[part 4 of 4: package /ComponentTypes]
AUTOSAR XML (schema 4-3-0)
package /ComponentTypes  (continued)
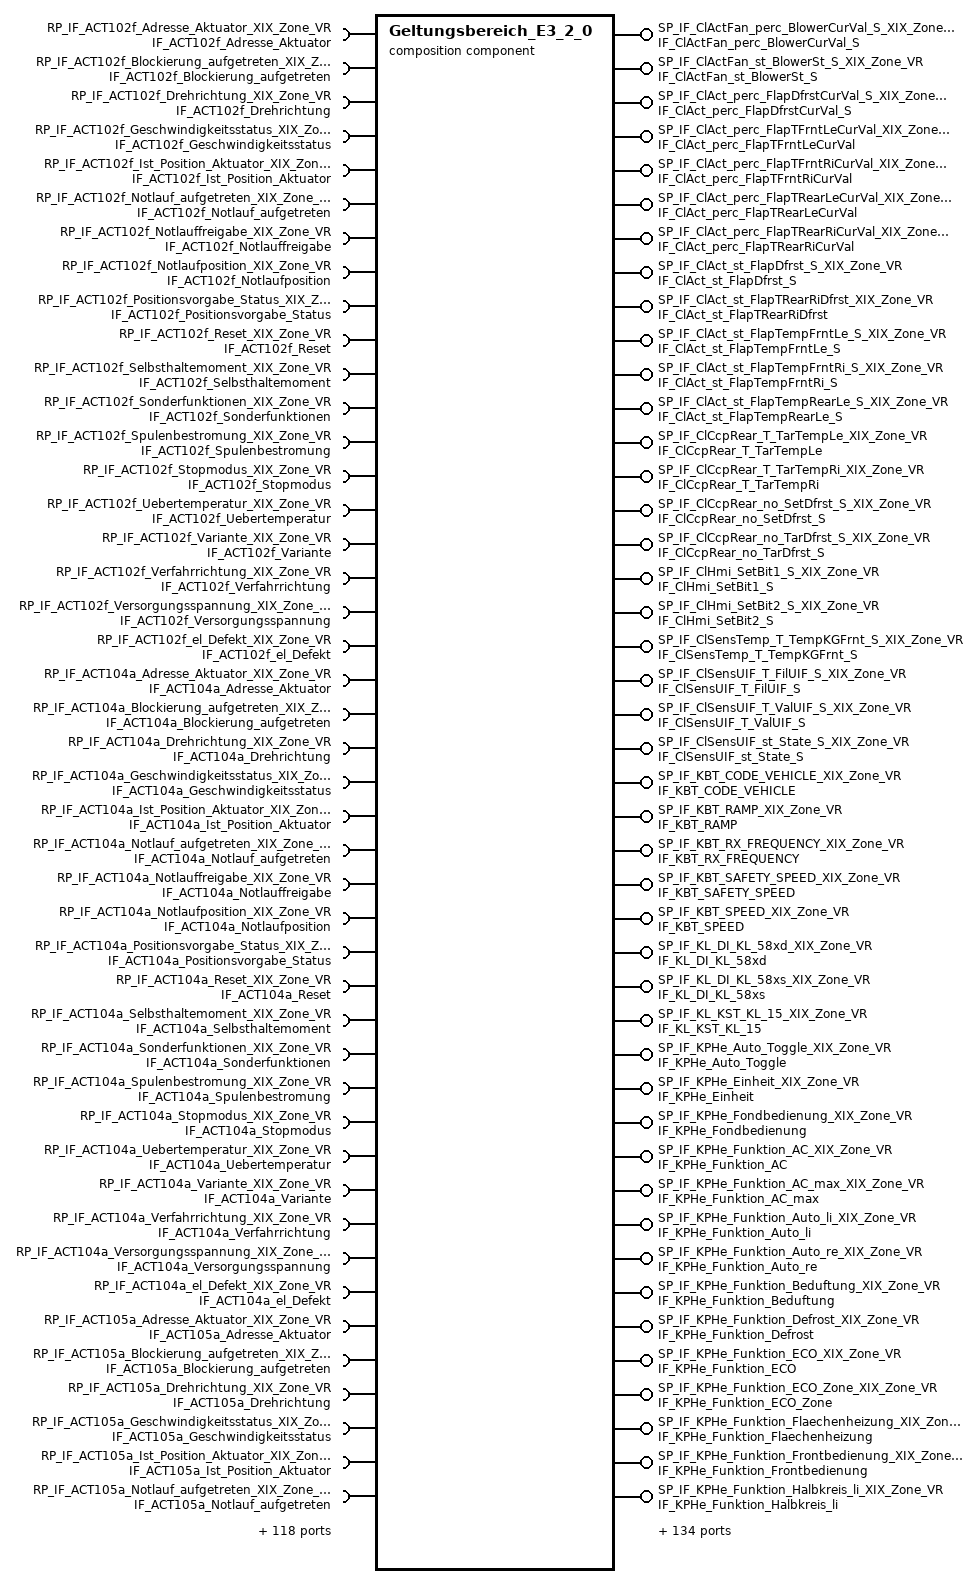
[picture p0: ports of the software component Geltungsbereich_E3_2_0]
  composition sw component type Geltungsbereich_E3_2_0
    178 x provide port:
      SP_IF_ClActFan_perc_BlowerCurVal_S_XIX_Zone_VR: provided-interface=IF_ClActFan_perc_BlowerCurVal_S
      SP_IF_ClActFan_st_BlowerSt_S_XIX_Zone_VR: provided-interface=IF_ClActFan_st_BlowerSt_S
      SP_IF_ClAct_perc_FlapDfrstCurVal_S_XIX_Zone_VR: provided-interface=IF_ClAct_perc_FlapDfrstCurVal_S
      SP_IF_ClAct_perc_FlapTFrntLeCurVal_XIX_Zone_VR: provided-interface=IF_ClAct_perc_FlapTFrntLeCurVal
      SP_IF_ClAct_perc_FlapTFrntRiCurVal_XIX_Zone_VR: provided-interface=IF_ClAct_perc_FlapTFrntRiCurVal
      SP_IF_ClAct_perc_FlapTRearLeCurVal_XIX_Zone_VR: provided-interface=IF_ClAct_perc_FlapTRearLeCurVal
      SP_IF_ClAct_perc_FlapTRearRiCurVal_XIX_Zone_VR: provided-interface=IF_ClAct_perc_FlapTRearRiCurVal
      SP_IF_ClAct_st_FlapDfrst_S_XIX_Zone_VR: provided-interface=IF_ClAct_st_FlapDfrst_S
      SP_IF_ClAct_st_FlapTRearRiDfrst_XIX_Zone_VR: provided-interface=IF_ClAct_st_FlapTRearRiDfrst
      SP_IF_ClAct_st_FlapTempFrntLe_S_XIX_Zone_VR: provided-interface=IF_ClAct_st_FlapTempFrntLe_S
      SP_IF_ClAct_st_FlapTempFrntRi_S_XIX_Zone_VR: provided-interface=IF_ClAct_st_FlapTempFrntRi_S
      SP_IF_ClAct_st_FlapTempRearLe_S_XIX_Zone_VR: provided-interface=IF_ClAct_st_FlapTempRearLe_S
      SP_IF_ClCcpRear_T_TarTempLe_XIX_Zone_VR: provided-interface=IF_ClCcpRear_T_TarTempLe
      SP_IF_ClCcpRear_T_TarTempRi_XIX_Zone_VR: provided-interface=IF_ClCcpRear_T_TarTempRi
      SP_IF_ClCcpRear_no_SetDfrst_S_XIX_Zone_VR: provided-interface=IF_ClCcpRear_no_SetDfrst_S
      SP_IF_ClCcpRear_no_TarDfrst_S_XIX_Zone_VR: provided-interface=IF_ClCcpRear_no_TarDfrst_S
      SP_IF_ClHmi_SetBit1_S_XIX_Zone_VR: provided-interface=IF_ClHmi_SetBit1_S
      SP_IF_ClHmi_SetBit2_S_XIX_Zone_VR: provided-interface=IF_ClHmi_SetBit2_S
      SP_IF_ClSensTemp_T_TempKGFrnt_S_XIX_Zone_VR: provided-interface=IF_ClSensTemp_T_TempKGFrnt_S
      SP_IF_ClSensUIF_T_FilUIF_S_XIX_Zone_VR: provided-interface=IF_ClSensUIF_T_FilUIF_S
      SP_IF_ClSensUIF_T_ValUIF_S_XIX_Zone_VR: provided-interface=IF_ClSensUIF_T_ValUIF_S
      SP_IF_ClSensUIF_st_State_S_XIX_Zone_VR: provided-interface=IF_ClSensUIF_st_State_S
      SP_IF_KBT_CODE_VEHICLE_XIX_Zone_VR: provided-interface=IF_KBT_CODE_VEHICLE
      SP_IF_KBT_RAMP_XIX_Zone_VR: provided-interface=IF_KBT_RAMP
      SP_IF_KBT_RX_FREQUENCY_XIX_Zone_VR: provided-interface=IF_KBT_RX_FREQUENCY
      SP_IF_KBT_SAFETY_SPEED_XIX_Zone_VR: provided-interface=IF_KBT_SAFETY_SPEED
      SP_IF_KBT_SPEED_XIX_Zone_VR: provided-interface=IF_KBT_SPEED
      SP_IF_KL_DI_KL_58xd_XIX_Zone_VR: provided-interface=IF_KL_DI_KL_58xd
      SP_IF_KL_DI_KL_58xs_XIX_Zone_VR: provided-interface=IF_KL_DI_KL_58xs
      SP_IF_KL_KST_KL_15_XIX_Zone_VR: provided-interface=IF_KL_KST_KL_15
      SP_IF_KPHe_Auto_Toggle_XIX_Zone_VR: provided-interface=IF_KPHe_Auto_Toggle
      SP_IF_KPHe_Einheit_XIX_Zone_VR: provided-interface=IF_KPHe_Einheit
      SP_IF_KPHe_Fondbedienung_XIX_Zone_VR: provided-interface=IF_KPHe_Fondbedienung
      SP_IF_KPHe_Funktion_AC_XIX_Zone_VR: provided-interface=IF_KPHe_Funktion_AC
      SP_IF_KPHe_Funktion_AC_max_XIX_Zone_VR: provided-interface=IF_KPHe_Funktion_AC_max
      SP_IF_KPHe_Funktion_Auto_li_XIX_Zone_VR: provided-interface=IF_KPHe_Funktion_Auto_li
      SP_IF_KPHe_Funktion_Auto_re_XIX_Zone_VR: provided-interface=IF_KPHe_Funktion_Auto_re
      SP_IF_KPHe_Funktion_Beduftung_XIX_Zone_VR: provided-interface=IF_KPHe_Funktion_Beduftung
      SP_IF_KPHe_Funktion_Defrost_XIX_Zone_VR: provided-interface=IF_KPHe_Funktion_Defrost
      SP_IF_KPHe_Funktion_ECO_XIX_Zone_VR: provided-interface=IF_KPHe_Funktion_ECO
      SP_IF_KPHe_Funktion_ECO_Zone_XIX_Zone_VR: provided-interface=IF_KPHe_Funktion_ECO_Zone
      SP_IF_KPHe_Funktion_Flaechenheizung_XIX_Zone_VR: provided-interface=IF_KPHe_Funktion_Flaechenheizung
      SP_IF_KPHe_Funktion_Frontbedienung_XIX_Zone_VR: provided-interface=IF_KPHe_Funktion_Frontbedienung
      SP_IF_KPHe_Funktion_Halbkreis_li_XIX_Zone_VR: provided-interface=IF_KPHe_Funktion_Halbkreis_li
      SP_IF_KPHe_Funktion_Halbkreis_re_XIX_Zone_VR: provided-interface=IF_KPHe_Funktion_Halbkreis_re
      SP_IF_KPHe_Funktion_Ionisator_XIX_Zone_VR: provided-interface=IF_KPHe_Funktion_Ionisator
      SP_IF_KPHe_Funktion_Kindersicherung_XIX_Zone_VR: provided-interface=IF_KPHe_Funktion_Kindersicherung
      SP_IF_KPHe_Funktion_Off_XIX_Zone_VR: provided-interface=IF_KPHe_Funktion_Off
      SP_IF_KPHe_Funktion_Sync_XIX_Zone_VR: provided-interface=IF_KPHe_Funktion_Sync
      SP_IF_KPHe_Funktion_Umluft_XIX_Zone_VR: provided-interface=IF_KPHe_Funktion_Umluft
      SP_IF_KPHe_Funktionsbeleuchtung_XIX_Zone_VR: provided-interface=IF_KPHe_Funktionsbeleuchtung
      SP_IF_KPHe_Fzg_Steigung_XIX_Zone_VR: provided-interface=IF_KPHe_Fzg_Steigung
      SP_IF_KPHe_Geblaese_Auto_li_XIX_Zone_VR: provided-interface=IF_KPHe_Geblaese_Auto_li
      SP_IF_KPHe_Geblaese_Auto_re_XIX_Zone_VR: provided-interface=IF_KPHe_Geblaese_Auto_re
      SP_IF_KPHe_Geblaese_Begrenzung_XIX_Zone_VR: provided-interface=IF_KPHe_Geblaese_Begrenzung
      SP_IF_KPHe_Geblaese_Stufe_li_XIX_Zone_VR: provided-interface=IF_KPHe_Geblaese_Stufe_li
      SP_IF_KPHe_Geblaese_Stufe_re_XIX_Zone_VR: provided-interface=IF_KPHe_Geblaese_Stufe_re
      SP_IF_KPHe_LCD_XIX_Zone_VR: provided-interface=IF_KPHe_LCD
      SP_IF_KPHe_Lenker_Position_XIX_Zone_VR: provided-interface=IF_KPHe_Lenker_Position
      SP_IF_KPHe_Luftverteilung_Auto_li_XIX_Zone_VR: provided-interface=IF_KPHe_Luftverteilung_Auto_li
      SP_IF_KPHe_Luftverteilung_Auto_re_XIX_Zone_VR: provided-interface=IF_KPHe_Luftverteilung_Auto_re
      SP_IF_KPHe_Luftverteilung_Mitte_li_XIX_Zone_VR: provided-interface=IF_KPHe_Luftverteilung_Mitte_li
      SP_IF_KPHe_Luftverteilung_Mitte_re_XIX_Zone_VR: provided-interface=IF_KPHe_Luftverteilung_Mitte_re
      SP_IF_KPHe_Luftverteilung_Oben_li_XIX_Zone_VR: provided-interface=IF_KPHe_Luftverteilung_Oben_li
      SP_IF_KPHe_Luftverteilung_Oben_re_XIX_Zone_VR: provided-interface=IF_KPHe_Luftverteilung_Oben_re
      SP_IF_KPHe_Luftverteilung_Unten_li_XIX_Zone_VR: provided-interface=IF_KPHe_Luftverteilung_Unten_li
      SP_IF_KPHe_Luftverteilung_Unten_re_XIX_Zone_VR: provided-interface=IF_KPHe_Luftverteilung_Unten_re
      SP_IF_KPHe_QBit_Steigung_XIX_Zone_VR: provided-interface=IF_KPHe_QBit_Steigung
      SP_IF_KPHe_Radio_Frequenz_XIX_Zone_VR: provided-interface=IF_KPHe_Radio_Frequenz
      SP_IF_KPHe_Sitzheizung_li_XIX_Zone_VR: provided-interface=IF_KPHe_Sitzheizung_li
      SP_IF_KPHe_Sitzheizung_re_XIX_Zone_VR: provided-interface=IF_KPHe_Sitzheizung_re
      SP_IF_KPHe_Sitzlueftung_li_XIX_Zone_VR: provided-interface=IF_KPHe_Sitzlueftung_li
      SP_IF_KPHe_Sitzlueftung_re_XIX_Zone_VR: provided-interface=IF_KPHe_Sitzlueftung_re
      SP_IF_KPHe_Stellgliedtest_XIX_Zone_VR: provided-interface=IF_KPHe_Stellgliedtest
      SP_IF_KPHe_Suchbeleuchtung_XIX_Zone_VR: provided-interface=IF_KPHe_Suchbeleuchtung
      SP_IF_KPHe_Symbol_Luftmenge_li_XIX_Zone_VR: provided-interface=IF_KPHe_Symbol_Luftmenge_li
      SP_IF_KPHe_Symbol_Luftmenge_re_XIX_Zone_VR: provided-interface=IF_KPHe_Symbol_Luftmenge_re
      SP_IF_KPHe_Symbol_Luftverteilung_li_XIX_Zone_VR: provided-interface=IF_KPHe_Symbol_Luftverteilung_li
      SP_IF_KPHe_Symbol_Luftverteilung_re_XIX_Zone_VR: provided-interface=IF_KPHe_Symbol_Luftverteilung_re
      SP_IF_KPHe_Symbol_Sitzheizung_li_XIX_Zone_VR: provided-interface=IF_KPHe_Symbol_Sitzheizung_li
      SP_IF_KPHe_Symbol_Sitzheizung_re_XIX_Zone_VR: provided-interface=IF_KPHe_Symbol_Sitzheizung_re
      SP_IF_KPHe_Symbol_Sitzlueftung_li_XIX_Zone_VR: provided-interface=IF_KPHe_Symbol_Sitzlueftung_li
      SP_IF_KPHe_Symbol_Sitzlueftung_re_XIX_Zone_VR: provided-interface=IF_KPHe_Symbol_Sitzlueftung_re
      SP_IF_KPHe_TFT_XIX_Zone_VR: provided-interface=IF_KPHe_TFT
      SP_IF_KPHe_Temp_li_XIX_Zone_VR: provided-interface=IF_KPHe_Temp_li
      SP_IF_KPHe_Temp_re_XIX_Zone_VR: provided-interface=IF_KPHe_Temp_re
      SP_IF_STRG100a_Adresse_XIX_Zone_VR: provided-interface=IF_STRG100a_Adresse
      SP_IF_STRG100a_Clear_Event_Flags_XIX_Zone_VR: provided-interface=IF_STRG100a_Clear_Event_Flags
      SP_IF_STRG100a_Drehrichtung_XIX_Zone_VR: provided-interface=IF_STRG100a_Drehrichtung
      SP_IF_STRG100a_Freig_Blockiererkennung_XIX_Zone_VR: provided-interface=IF_STRG100a_Freig_Blockiererkennung
      SP_IF_STRG100a_Geschwindigkeitsvorgabe_XIX_Zone_VR: provided-interface=IF_STRG100a_Geschwindigkeitsvorgabe
      SP_IF_STRG100a_Notlauffreigabe_XIX_Zone_VR: provided-interface=IF_STRG100a_Notlauffreigabe
      SP_IF_STRG100a_Notlaufposition_XIX_Zone_VR: provided-interface=IF_STRG100a_Notlaufposition
      SP_IF_STRG100a_PrgDaten_speichern_XIX_Zone_VR: provided-interface=IF_STRG100a_PrgDaten_speichern
      SP_IF_STRG100a_Select_Positionsvorgabe_XIX_Zone_VR: provided-interface=IF_STRG100a_Select_Positionsvorgabe
      SP_IF_STRG100a_Soll_Position_XIX_Zone_VR: provided-interface=IF_STRG100a_Soll_Position
      SP_IF_STRG100a_Spulenhaltebestromung_XIX_Zone_VR: provided-interface=IF_STRG100a_Spulenhaltebestromung
      SP_IF_STRG100a_Start_Position_XIX_Zone_VR: provided-interface=IF_STRG100a_Start_Position
      SP_IF_STRG100a_Stopmodus_XIX_Zone_VR: provided-interface=IF_STRG100a_Stopmodus
      SP_IF_STRG100f_Adresse_XIX_Zone_VR: provided-interface=IF_STRG100f_Adresse
      SP_IF_STRG100f_Clear_Event_Flags_XIX_Zone_VR: provided-interface=IF_STRG100f_Clear_Event_Flags
      SP_IF_STRG100f_Drehrichtung_XIX_Zone_VR: provided-interface=IF_STRG100f_Drehrichtung
      SP_IF_STRG100f_Freig_Blockiererkennung_XIX_Zone_VR: provided-interface=IF_STRG100f_Freig_Blockiererkennung
      SP_IF_STRG100f_Geschwindigkeitsvorgabe_XIX_Zone_VR: provided-interface=IF_STRG100f_Geschwindigkeitsvorgabe
      SP_IF_STRG100f_Notlauffreigabe_XIX_Zone_VR: provided-interface=IF_STRG100f_Notlauffreigabe
      SP_IF_STRG100f_Notlaufposition_XIX_Zone_VR: provided-interface=IF_STRG100f_Notlaufposition
      SP_IF_STRG100f_PrgDaten_speichern_XIX_Zone_VR: provided-interface=IF_STRG100f_PrgDaten_speichern
      SP_IF_STRG100f_Select_Positionsvorgabe_XIX_Zone_VR: provided-interface=IF_STRG100f_Select_Positionsvorgabe
      SP_IF_STRG100f_Soll_Position_XIX_Zone_VR: provided-interface=IF_STRG100f_Soll_Position
      SP_IF_STRG100f_Spulenhaltebestromung_XIX_Zone_VR: provided-interface=IF_STRG100f_Spulenhaltebestromung
      SP_IF_STRG100f_Start_Position_XIX_Zone_VR: provided-interface=IF_STRG100f_Start_Position
      SP_IF_STRG100f_Stopmodus_XIX_Zone_VR: provided-interface=IF_STRG100f_Stopmodus
      SP_IF_STRG102f_Adresse_XIX_Zone_VR: provided-interface=IF_STRG102f_Adresse
      SP_IF_STRG102f_Clear_Event_Flags_XIX_Zone_VR: provided-interface=IF_STRG102f_Clear_Event_Flags
      SP_IF_STRG102f_Drehrichtung_XIX_Zone_VR: provided-interface=IF_STRG102f_Drehrichtung
      SP_IF_STRG102f_Freig_Blockiererkennung_XIX_Zone_VR: provided-interface=IF_STRG102f_Freig_Blockiererkennung
      SP_IF_STRG102f_Geschwindigkeitsvorgabe_XIX_Zone_VR: provided-interface=IF_STRG102f_Geschwindigkeitsvorgabe
      SP_IF_STRG102f_Notlauffreigabe_XIX_Zone_VR: provided-interface=IF_STRG102f_Notlauffreigabe
      SP_IF_STRG102f_Notlaufposition_XIX_Zone_VR: provided-interface=IF_STRG102f_Notlaufposition
      SP_IF_STRG102f_PrgDaten_speichern_XIX_Zone_VR: provided-interface=IF_STRG102f_PrgDaten_speichern
      SP_IF_STRG102f_Select_Positionsvorgabe_XIX_Zone_VR: provided-interface=IF_STRG102f_Select_Positionsvorgabe
      SP_IF_STRG102f_Soll_Position_XIX_Zone_VR: provided-interface=IF_STRG102f_Soll_Position
      SP_IF_STRG102f_Spulenhaltebestromung_XIX_Zone_VR: provided-interface=IF_STRG102f_Spulenhaltebestromung
      SP_IF_STRG102f_Start_Position_XIX_Zone_VR: provided-interface=IF_STRG102f_Start_Position
      SP_IF_STRG102f_Stopmodus_XIX_Zone_VR: provided-interface=IF_STRG102f_Stopmodus
      SP_IF_STRG104a_Adresse_XIX_Zone_VR: provided-interface=IF_STRG104a_Adresse
      SP_IF_STRG104a_Clear_Event_Flags_XIX_Zone_VR: provided-interface=IF_STRG104a_Clear_Event_Flags
      SP_IF_STRG104a_Drehrichtung_XIX_Zone_VR: provided-interface=IF_STRG104a_Drehrichtung
      SP_IF_STRG104a_Freig_Blockiererkennung_XIX_Zone_VR: provided-interface=IF_STRG104a_Freig_Blockiererkennung
      SP_IF_STRG104a_Geschwindigkeitsvorgabe_XIX_Zone_VR: provided-interface=IF_STRG104a_Geschwindigkeitsvorgabe
      SP_IF_STRG104a_Notlauffreigabe_XIX_Zone_VR: provided-interface=IF_STRG104a_Notlauffreigabe
      SP_IF_STRG104a_Notlaufposition_XIX_Zone_VR: provided-interface=IF_STRG104a_Notlaufposition
      SP_IF_STRG104a_PrgDaten_speichern_XIX_Zone_VR: provided-interface=IF_STRG104a_PrgDaten_speichern
      SP_IF_STRG104a_Select_Positionsvorgabe_XIX_Zone_VR: provided-interface=IF_STRG104a_Select_Positionsvorgabe
      SP_IF_STRG104a_Soll_Position_XIX_Zone_VR: provided-interface=IF_STRG104a_Soll_Position
      SP_IF_STRG104a_Spulenhaltebestromung_XIX_Zone_VR: provided-interface=IF_STRG104a_Spulenhaltebestromung
      SP_IF_STRG104a_Start_Position_XIX_Zone_VR: provided-interface=IF_STRG104a_Start_Position
      SP_IF_STRG104a_Stopmodus_XIX_Zone_VR: provided-interface=IF_STRG104a_Stopmodus
      SP_IF_STRG105a_Adresse_XIX_Zone_VR: provided-interface=IF_STRG105a_Adresse
      SP_IF_STRG105a_Clear_Event_Flags_XIX_Zone_VR: provided-interface=IF_STRG105a_Clear_Event_Flags
      SP_IF_STRG105a_Drehrichtung_XIX_Zone_VR: provided-interface=IF_STRG105a_Drehrichtung
      SP_IF_STRG105a_Freig_Blockiererkennung_XIX_Zone_VR: provided-interface=IF_STRG105a_Freig_Blockiererkennung
      SP_IF_STRG105a_Geschwindigkeitsvorgabe_XIX_Zone_VR: provided-interface=IF_STRG105a_Geschwindigkeitsvorgabe
      SP_IF_STRG105a_Notlauffreigabe_XIX_Zone_VR: provided-interface=IF_STRG105a_Notlauffreigabe
      SP_IF_STRG105a_Notlaufposition_XIX_Zone_VR: provided-interface=IF_STRG105a_Notlaufposition
      SP_IF_STRG105a_PrgDaten_speichern_XIX_Zone_VR: provided-interface=IF_STRG105a_PrgDaten_speichern
      SP_IF_STRG105a_Select_Positionsvorgabe_XIX_Zone_VR: provided-interface=IF_STRG105a_Select_Positionsvorgabe
      SP_IF_STRG105a_Soll_Position_XIX_Zone_VR: provided-interface=IF_STRG105a_Soll_Position
      SP_IF_STRG105a_Spulenhaltebestromung_XIX_Zone_VR: provided-interface=IF_STRG105a_Spulenhaltebestromung
      SP_IF_STRG105a_Start_Position_XIX_Zone_VR: provided-interface=IF_STRG105a_Start_Position
      SP_IF_STRG105a_Stopmodus_XIX_Zone_VR: provided-interface=IF_STRG105a_Stopmodus
      SP_IF_STRG106a_Adresse_XIX_Zone_VR: provided-interface=IF_STRG106a_Adresse
      SP_IF_STRG106a_Clear_Event_Flags_XIX_Zone_VR: provided-interface=IF_STRG106a_Clear_Event_Flags
      SP_IF_STRG106a_Drehrichtung_XIX_Zone_VR: provided-interface=IF_STRG106a_Drehrichtung
      SP_IF_STRG106a_Freig_Blockiererkennung_XIX_Zone_VR: provided-interface=IF_STRG106a_Freig_Blockiererkennung
      SP_IF_STRG106a_Geschwindigkeitsvorgabe_XIX_Zone_VR: provided-interface=IF_STRG106a_Geschwindigkeitsvorgabe
      SP_IF_STRG106a_Notlauffreigabe_XIX_Zone_VR: provided-interface=IF_STRG106a_Notlauffreigabe
      SP_IF_STRG106a_Notlaufposition_XIX_Zone_VR: provided-interface=IF_STRG106a_Notlaufposition
      SP_IF_STRG106a_PrgDaten_speichern_XIX_Zone_VR: provided-interface=IF_STRG106a_PrgDaten_speichern
      SP_IF_STRG106a_Select_Positionsvorgabe_XIX_Zone_VR: provided-interface=IF_STRG106a_Select_Positionsvorgabe
      SP_IF_STRG106a_Soll_Position_XIX_Zone_VR: provided-interface=IF_STRG106a_Soll_Position
      SP_IF_STRG106a_Spulenhaltebestromung_XIX_Zone_VR: provided-interface=IF_STRG106a_Spulenhaltebestromung
      SP_IF_STRG106a_Start_Position_XIX_Zone_VR: provided-interface=IF_STRG106a_Start_Position
      SP_IF_STRG106a_Stopmodus_XIX_Zone_VR: provided-interface=IF_STRG106a_Stopmodus
      SP_IF_STRG109a_Adresse_XIX_Zone_VR: provided-interface=IF_STRG109a_Adresse
      SP_IF_STRG109a_Clear_Event_Flags_XIX_Zone_VR: provided-interface=IF_STRG109a_Clear_Event_Flags
      SP_IF_STRG109a_Drehrichtung_XIX_Zone_VR: provided-interface=IF_STRG109a_Drehrichtung
      SP_IF_STRG109a_Freig_Blockiererkennung_XIX_Zone_VR: provided-interface=IF_STRG109a_Freig_Blockiererkennung
      SP_IF_STRG109a_Geschwindigkeitsvorgabe_XIX_Zone_VR: provided-interface=IF_STRG109a_Geschwindigkeitsvorgabe
      SP_IF_STRG109a_Notlauffreigabe_XIX_Zone_VR: provided-interface=IF_STRG109a_Notlauffreigabe
      SP_IF_STRG109a_Notlaufposition_XIX_Zone_VR: provided-interface=IF_STRG109a_Notlaufposition
      SP_IF_STRG109a_PrgDaten_speichern_XIX_Zone_VR: provided-interface=IF_STRG109a_PrgDaten_speichern
      SP_IF_STRG109a_Select_Positionsvorgabe_XIX_Zone_VR: provided-interface=IF_STRG109a_Select_Positionsvorgabe
      SP_IF_STRG109a_Soll_Position_XIX_Zone_VR: provided-interface=IF_STRG109a_Soll_Position
      SP_IF_STRG109a_Spulenhaltebestromung_XIX_Zone_VR: provided-interface=IF_STRG109a_Spulenhaltebestromung
      SP_IF_STRG109a_Start_Position_XIX_Zone_VR: provided-interface=IF_STRG109a_Start_Position
      SP_IF_STRG109a_Stopmodus_XIX_Zone_VR: provided-interface=IF_STRG109a_Stopmodus
      SP_IF_TME_T_OutsideAirTemp_raw_XIX_Zone_VR: provided-interface=IF_TME_T_OutsideAirTemp_raw
    162 x require port:
      RP_IF_ACT102f_Adresse_Aktuator_XIX_Zone_VR: required-interface=IF_ACT102f_Adresse_Aktuator
      RP_IF_ACT102f_Blockierung_aufgetreten_XIX_Zone_VR: required-interface=IF_ACT102f_Blockierung_aufgetreten
      RP_IF_ACT102f_Drehrichtung_XIX_Zone_VR: required-interface=IF_ACT102f_Drehrichtung
      RP_IF_ACT102f_Geschwindigkeitsstatus_XIX_Zone_VR: required-interface=IF_ACT102f_Geschwindigkeitsstatus
      RP_IF_ACT102f_Ist_Position_Aktuator_XIX_Zone_VR: required-interface=IF_ACT102f_Ist_Position_Aktuator
      RP_IF_ACT102f_Notlauf_aufgetreten_XIX_Zone_VR: required-interface=IF_ACT102f_Notlauf_aufgetreten
      RP_IF_ACT102f_Notlauffreigabe_XIX_Zone_VR: required-interface=IF_ACT102f_Notlauffreigabe
      RP_IF_ACT102f_Notlaufposition_XIX_Zone_VR: required-interface=IF_ACT102f_Notlaufposition
      RP_IF_ACT102f_Positionsvorgabe_Status_XIX_Zone_VR: required-interface=IF_ACT102f_Positionsvorgabe_Status
      RP_IF_ACT102f_Reset_XIX_Zone_VR: required-interface=IF_ACT102f_Reset
      RP_IF_ACT102f_Selbsthaltemoment_XIX_Zone_VR: required-interface=IF_ACT102f_Selbsthaltemoment
      RP_IF_ACT102f_Sonderfunktionen_XIX_Zone_VR: required-interface=IF_ACT102f_Sonderfunktionen
      RP_IF_ACT102f_Spulenbestromung_XIX_Zone_VR: required-interface=IF_ACT102f_Spulenbestromung
      RP_IF_ACT102f_Stopmodus_XIX_Zone_VR: required-interface=IF_ACT102f_Stopmodus
      RP_IF_ACT102f_Uebertemperatur_XIX_Zone_VR: required-interface=IF_ACT102f_Uebertemperatur
      RP_IF_ACT102f_Variante_XIX_Zone_VR: required-interface=IF_ACT102f_Variante
      RP_IF_ACT102f_Verfahrrichtung_XIX_Zone_VR: required-interface=IF_ACT102f_Verfahrrichtung
      RP_IF_ACT102f_Versorgungsspannung_XIX_Zone_VR: required-interface=IF_ACT102f_Versorgungsspannung
      RP_IF_ACT102f_el_Defekt_XIX_Zone_VR: required-interface=IF_ACT102f_el_Defekt
      RP_IF_ACT104a_Adresse_Aktuator_XIX_Zone_VR: required-interface=IF_ACT104a_Adresse_Aktuator
      RP_IF_ACT104a_Blockierung_aufgetreten_XIX_Zone_VR: required-interface=IF_ACT104a_Blockierung_aufgetreten
      RP_IF_ACT104a_Drehrichtung_XIX_Zone_VR: required-interface=IF_ACT104a_Drehrichtung
      RP_IF_ACT104a_Geschwindigkeitsstatus_XIX_Zone_VR: required-interface=IF_ACT104a_Geschwindigkeitsstatus
      RP_IF_ACT104a_Ist_Position_Aktuator_XIX_Zone_VR: required-interface=IF_ACT104a_Ist_Position_Aktuator
      RP_IF_ACT104a_Notlauf_aufgetreten_XIX_Zone_VR: required-interface=IF_ACT104a_Notlauf_aufgetreten
      RP_IF_ACT104a_Notlauffreigabe_XIX_Zone_VR: required-interface=IF_ACT104a_Notlauffreigabe
      RP_IF_ACT104a_Notlaufposition_XIX_Zone_VR: required-interface=IF_ACT104a_Notlaufposition
      RP_IF_ACT104a_Positionsvorgabe_Status_XIX_Zone_VR: required-interface=IF_ACT104a_Positionsvorgabe_Status
      RP_IF_ACT104a_Reset_XIX_Zone_VR: required-interface=IF_ACT104a_Reset
      RP_IF_ACT104a_Selbsthaltemoment_XIX_Zone_VR: required-interface=IF_ACT104a_Selbsthaltemoment
      RP_IF_ACT104a_Sonderfunktionen_XIX_Zone_VR: required-interface=IF_ACT104a_Sonderfunktionen
      RP_IF_ACT104a_Spulenbestromung_XIX_Zone_VR: required-interface=IF_ACT104a_Spulenbestromung
      RP_IF_ACT104a_Stopmodus_XIX_Zone_VR: required-interface=IF_ACT104a_Stopmodus
      RP_IF_ACT104a_Uebertemperatur_XIX_Zone_VR: required-interface=IF_ACT104a_Uebertemperatur
      RP_IF_ACT104a_Variante_XIX_Zone_VR: required-interface=IF_ACT104a_Variante
      RP_IF_ACT104a_Verfahrrichtung_XIX_Zone_VR: required-interface=IF_ACT104a_Verfahrrichtung
      RP_IF_ACT104a_Versorgungsspannung_XIX_Zone_VR: required-interface=IF_ACT104a_Versorgungsspannung
      RP_IF_ACT104a_el_Defekt_XIX_Zone_VR: required-interface=IF_ACT104a_el_Defekt
      RP_IF_ACT105a_Adresse_Aktuator_XIX_Zone_VR: required-interface=IF_ACT105a_Adresse_Aktuator
      RP_IF_ACT105a_Blockierung_aufgetreten_XIX_Zone_VR: required-interface=IF_ACT105a_Blockierung_aufgetreten
      RP_IF_ACT105a_Drehrichtung_XIX_Zone_VR: required-interface=IF_ACT105a_Drehrichtung
      RP_IF_ACT105a_Geschwindigkeitsstatus_XIX_Zone_VR: required-interface=IF_ACT105a_Geschwindigkeitsstatus
      RP_IF_ACT105a_Ist_Position_Aktuator_XIX_Zone_VR: required-interface=IF_ACT105a_Ist_Position_Aktuator
      RP_IF_ACT105a_Notlauf_aufgetreten_XIX_Zone_VR: required-interface=IF_ACT105a_Notlauf_aufgetreten
      RP_IF_ACT105a_Notlauffreigabe_XIX_Zone_VR: required-interface=IF_ACT105a_Notlauffreigabe
      RP_IF_ACT105a_Notlaufposition_XIX_Zone_VR: required-interface=IF_ACT105a_Notlaufposition
      RP_IF_ACT105a_Positionsvorgabe_Status_XIX_Zone_VR: required-interface=IF_ACT105a_Positionsvorgabe_Status
      RP_IF_ACT105a_Reset_XIX_Zone_VR: required-interface=IF_ACT105a_Reset
      RP_IF_ACT105a_Selbsthaltemoment_XIX_Zone_VR: required-interface=IF_ACT105a_Selbsthaltemoment
      RP_IF_ACT105a_Sonderfunktionen_XIX_Zone_VR: required-interface=IF_ACT105a_Sonderfunktionen
      RP_IF_ACT105a_Spulenbestromung_XIX_Zone_VR: required-interface=IF_ACT105a_Spulenbestromung
      RP_IF_ACT105a_Stopmodus_XIX_Zone_VR: required-interface=IF_ACT105a_Stopmodus
      RP_IF_ACT105a_Uebertemperatur_XIX_Zone_VR: required-interface=IF_ACT105a_Uebertemperatur
      RP_IF_ACT105a_Variante_XIX_Zone_VR: required-interface=IF_ACT105a_Variante
      RP_IF_ACT105a_Verfahrrichtung_XIX_Zone_VR: required-interface=IF_ACT105a_Verfahrrichtung
      RP_IF_ACT105a_Versorgungsspannung_XIX_Zone_VR: required-interface=IF_ACT105a_Versorgungsspannung
      RP_IF_ACT105a_el_Defekt_XIX_Zone_VR: required-interface=IF_ACT105a_el_Defekt
      RP_IF_ACT106a_Adresse_Aktuator_XIX_Zone_VR: required-interface=IF_ACT106a_Adresse_Aktuator
      RP_IF_ACT106a_Blockierung_aufgetreten_XIX_Zone_VR: required-interface=IF_ACT106a_Blockierung_aufgetreten
      RP_IF_ACT106a_Drehrichtung_XIX_Zone_VR: required-interface=IF_ACT106a_Drehrichtung
      RP_IF_ACT106a_Geschwindigkeitsstatus_XIX_Zone_VR: required-interface=IF_ACT106a_Geschwindigkeitsstatus
      RP_IF_ACT106a_Ist_Position_Aktuator_XIX_Zone_VR: required-interface=IF_ACT106a_Ist_Position_Aktuator
      RP_IF_ACT106a_Notlauf_aufgetreten_XIX_Zone_VR: required-interface=IF_ACT106a_Notlauf_aufgetreten
      RP_IF_ACT106a_Notlauffreigabe_XIX_Zone_VR: required-interface=IF_ACT106a_Notlauffreigabe
      RP_IF_ACT106a_Notlaufposition_XIX_Zone_VR: required-interface=IF_ACT106a_Notlaufposition
      RP_IF_ACT106a_Positionsvorgabe_Status_XIX_Zone_VR: required-interface=IF_ACT106a_Positionsvorgabe_Status
      RP_IF_ACT106a_Reset_XIX_Zone_VR: required-interface=IF_ACT106a_Reset
      RP_IF_ACT106a_Selbsthaltemoment_XIX_Zone_VR: required-interface=IF_ACT106a_Selbsthaltemoment
      RP_IF_ACT106a_Sonderfunktionen_XIX_Zone_VR: required-interface=IF_ACT106a_Sonderfunktionen
      RP_IF_ACT106a_Spulenbestromung_XIX_Zone_VR: required-interface=IF_ACT106a_Spulenbestromung
      RP_IF_ACT106a_Stopmodus_XIX_Zone_VR: required-interface=IF_ACT106a_Stopmodus
      RP_IF_ACT106a_Uebertemperatur_XIX_Zone_VR: required-interface=IF_ACT106a_Uebertemperatur
      RP_IF_ACT106a_Variante_XIX_Zone_VR: required-interface=IF_ACT106a_Variante
      RP_IF_ACT106a_Verfahrrichtung_XIX_Zone_VR: required-interface=IF_ACT106a_Verfahrrichtung
      RP_IF_ACT106a_Versorgungsspannung_XIX_Zone_VR: required-interface=IF_ACT106a_Versorgungsspannung
      RP_IF_ACT106a_el_Defekt_XIX_Zone_VR: required-interface=IF_ACT106a_el_Defekt
      RP_IF_ACT109a_Adresse_Aktuator_XIX_Zone_VR: required-interface=IF_ACT109a_Adresse_Aktuator
      RP_IF_ACT109a_Blockierung_aufgetreten_XIX_Zone_VR: required-interface=IF_ACT109a_Blockierung_aufgetreten
      RP_IF_ACT109a_Drehrichtung_XIX_Zone_VR: required-interface=IF_ACT109a_Drehrichtung
      RP_IF_ACT109a_Geschwindigkeitsstatus_XIX_Zone_VR: required-interface=IF_ACT109a_Geschwindigkeitsstatus
      RP_IF_ACT109a_Ist_Position_Aktuator_XIX_Zone_VR: required-interface=IF_ACT109a_Ist_Position_Aktuator
      RP_IF_ACT109a_Notlauf_aufgetreten_XIX_Zone_VR: required-interface=IF_ACT109a_Notlauf_aufgetreten
      RP_IF_ACT109a_Notlauffreigabe_XIX_Zone_VR: required-interface=IF_ACT109a_Notlauffreigabe
      RP_IF_ACT109a_Notlaufposition_XIX_Zone_VR: required-interface=IF_ACT109a_Notlaufposition
      RP_IF_ACT109a_Positionsvorgabe_Status_XIX_Zone_VR: required-interface=IF_ACT109a_Positionsvorgabe_Status
      RP_IF_ACT109a_Reset_XIX_Zone_VR: required-interface=IF_ACT109a_Reset
      RP_IF_ACT109a_Selbsthaltemoment_XIX_Zone_VR: required-interface=IF_ACT109a_Selbsthaltemoment
      RP_IF_ACT109a_Sonderfunktionen_XIX_Zone_VR: required-interface=IF_ACT109a_Sonderfunktionen
      RP_IF_ACT109a_Spulenbestromung_XIX_Zone_VR: required-interface=IF_ACT109a_Spulenbestromung
      RP_IF_ACT109a_Stopmodus_XIX_Zone_VR: required-interface=IF_ACT109a_Stopmodus
      RP_IF_ACT109a_Uebertemperatur_XIX_Zone_VR: required-interface=IF_ACT109a_Uebertemperatur
      RP_IF_ACT109a_Variante_XIX_Zone_VR: required-interface=IF_ACT109a_Variante
      RP_IF_ACT109a_Verfahrrichtung_XIX_Zone_VR: required-interface=IF_ACT109a_Verfahrrichtung
      RP_IF_ACT109a_Versorgungsspannung_XIX_Zone_VR: required-interface=IF_ACT109a_Versorgungsspannung
      RP_IF_ACT109a_el_Defekt_XIX_Zone_VR: required-interface=IF_ACT109a_el_Defekt
      RP_IF_BLOWER_DIAG_FLAG1_XIX_Zone_VR: required-interface=IF_BLOWER_DIAG_FLAG1
      RP_IF_BLOWER_DIAG_FLAG2_XIX_Zone_VR: required-interface=IF_BLOWER_DIAG_FLAG2
      RP_IF_BLOWER_IBATT_XIX_Zone_VR: required-interface=IF_BLOWER_IBATT
      RP_IF_BLOWER_ROTATION_SPEED_XIX_Zone_VR: required-interface=IF_BLOWER_ROTATION_SPEED
      RP_IF_BLOWER_STATUS_MOTOR_XIX_Zone_VR: required-interface=IF_BLOWER_STATUS_MOTOR
      RP_IF_BLOWER_SUPPLIER_XIX_Zone_VR: required-interface=IF_BLOWER_SUPPLIER
      RP_IF_BLOWER_TEMPERATURE_XIX_Zone_VR: required-interface=IF_BLOWER_TEMPERATURE
      RP_IF_BLOWER_TORQUE_XIX_Zone_VR: required-interface=IF_BLOWER_TORQUE
      RP_IF_BLOWER_UBATT_XIX_Zone_VR: required-interface=IF_BLOWER_UBATT
      RP_IF_BLOWER_UMOTOR_XIX_Zone_VR: required-interface=IF_BLOWER_UMOTOR
      RP_IF_ClActFan_perc_BlowerTarVal_S_XIX_Zone_VR: required-interface=IF_ClActFan_perc_BlowerTarVal_S
      RP_IF_ClAct_perc_FlapDfrstTarVal_XIX_Zone_VR: required-interface=IF_ClAct_perc_FlapDfrstTarVal
      RP_IF_ClAct_perc_FlapTFrntLeTarVal_XIX_Zone_VR: required-interface=IF_ClAct_perc_FlapTFrntLeTarVal
      RP_IF_ClAct_perc_FlapTFrntRiTarVal_XIX_Zone_VR: required-interface=IF_ClAct_perc_FlapTFrntRiTarVal
      RP_IF_ClAct_perc_FlapTRearLeTarVal_XIX_Zone_VR: required-interface=IF_ClAct_perc_FlapTRearLeTarVal
      RP_IF_ClAct_perc_FlapTRearRiTarVal_XIX_Zone_VR: required-interface=IF_ClAct_perc_FlapTRearRiTarVal
      RP_IF_ClHmi_T_CurTempFrntLe_S_XIX_Zone_VR: required-interface=IF_ClHmi_T_CurTempFrntLe_S
      RP_IF_ClHmi_T_CurTempFrntRi_S_XIX_Zone_VR: required-interface=IF_ClHmi_T_CurTempFrntRi_S
      RP_IF_ClHmi_T_CurTempRearLe_S_XIX_Zone_VR: required-interface=IF_ClHmi_T_CurTempRearLe_S
      RP_IF_ClHmi_T_CurTempRearRi_S_XIX_Zone_VR: required-interface=IF_ClHmi_T_CurTempRearRi_S
      RP_IF_ClHmi_st_StDfrst_S_XIX_Zone_VR: required-interface=IF_ClHmi_st_StDfrst_S
      RP_IF_ClSens_SetBit1_S_XIX_Zone_VR: required-interface=IF_ClSens_SetBit1_S
      RP_IF_ClSens_SetBit2_S_XIX_Zone_VR: required-interface=IF_ClSens_SetBit2_S
      RP_IF_KL_DI_KL_58xd_XIX_Zone_VR: required-interface=IF_KL_DI_KL_58xd
      RP_IF_KL_DI_KL_58xs_XIX_Zone_VR: required-interface=IF_KL_DI_KL_58xs
      RP_IF_KL_KST_KL_15_XIX_Zone_VR: required-interface=IF_KL_KST_KL_15
      RP_IF_KPH_AC_XIX_Zone_VR: required-interface=IF_KPH_AC
      RP_IF_KPH_AC_max_XIX_Zone_VR: required-interface=IF_KPH_AC_max
      RP_IF_KPH_Auto_li_XIX_Zone_VR: required-interface=IF_KPH_Auto_li
      RP_IF_KPH_Auto_re_XIX_Zone_VR: required-interface=IF_KPH_Auto_re
      RP_IF_KPH_Beduftung_XIX_Zone_VR: required-interface=IF_KPH_Beduftung
      RP_IF_KPH_ECO_XIX_Zone_VR: required-interface=IF_KPH_ECO
      RP_IF_KPH_ECO_links_XIX_Zone_VR: required-interface=IF_KPH_ECO_links
      RP_IF_KPH_ECO_rechts_XIX_Zone_VR: required-interface=IF_KPH_ECO_rechts
      RP_IF_KPH_Flaechenheizung_XIX_Zone_VR: required-interface=IF_KPH_Flaechenheizung
      RP_IF_KPH_Geblaese_Auto_li_XIX_Zone_VR: required-interface=IF_KPH_Geblaese_Auto_li
      RP_IF_KPH_Geblaese_Auto_re_XIX_Zone_VR: required-interface=IF_KPH_Geblaese_Auto_re
      RP_IF_KPH_Geblaese_Stufe_li_XIX_Zone_VR: required-interface=IF_KPH_Geblaese_Stufe_li
      RP_IF_KPH_Geblaese_Stufe_re_XIX_Zone_VR: required-interface=IF_KPH_Geblaese_Stufe_re
      RP_IF_KPH_Init_XIX_Zone_VR: required-interface=IF_KPH_Init
      RP_IF_KPH_Ionisator_XIX_Zone_VR: required-interface=IF_KPH_Ionisator
      RP_IF_KPH_Klima_Menue_MMI_XIX_Zone_VR: required-interface=IF_KPH_Klima_Menue_MMI
      RP_IF_KPH_Lautsprecher_XIX_Zone_VR: required-interface=IF_KPH_Lautsprecher
      RP_IF_KPH_Lokalaktiv_XIX_Zone_VR: required-interface=IF_KPH_Lokalaktiv
      RP_IF_KPH_Luftverteilung_Auto_li_XIX_Zone_VR: required-interface=IF_KPH_Luftverteilung_Auto_li
      RP_IF_KPH_Luftverteilung_Auto_re_XIX_Zone_VR: required-interface=IF_KPH_Luftverteilung_Auto_re
      RP_IF_KPH_Luftverteilung_Mitte_li_XIX_Zone_VR: required-interface=IF_KPH_Luftverteilung_Mitte_li
      RP_IF_KPH_Luftverteilung_Mitte_re_XIX_Zone_VR: required-interface=IF_KPH_Luftverteilung_Mitte_re
      RP_IF_KPH_Luftverteilung_Oben_li_XIX_Zone_VR: required-interface=IF_KPH_Luftverteilung_Oben_li
      RP_IF_KPH_Luftverteilung_Oben_re_XIX_Zone_VR: required-interface=IF_KPH_Luftverteilung_Oben_re
      RP_IF_KPH_Luftverteilung_Unten_li_XIX_Zone_VR: required-interface=IF_KPH_Luftverteilung_Unten_li
      RP_IF_KPH_Luftverteilung_Unten_re_XIX_Zone_VR: required-interface=IF_KPH_Luftverteilung_Unten_re
      RP_IF_KPH_Neigungssensor_XIX_Zone_VR: required-interface=IF_KPH_Neigungssensor
      RP_IF_KPH_Off_XIX_Zone_VR: required-interface=IF_KPH_Off
      RP_IF_KPH_Panel_Error_XIX_Zone_VR: required-interface=IF_KPH_Panel_Error
      RP_IF_KPH_ResponseError_XIX_Zone_VR: required-interface=IF_KPH_ResponseError
      RP_IF_KPH_Sitzheizung_li_XIX_Zone_VR: required-interface=IF_KPH_Sitzheizung_li
      RP_IF_KPH_Sitzheizung_re_XIX_Zone_VR: required-interface=IF_KPH_Sitzheizung_re
      RP_IF_KPH_Sitzlueftung_li_XIX_Zone_VR: required-interface=IF_KPH_Sitzlueftung_li
      RP_IF_KPH_Sitzlueftung_re_XIX_Zone_VR: required-interface=IF_KPH_Sitzlueftung_re
      RP_IF_KPH_Status_Spannung_XIX_Zone_VR: required-interface=IF_KPH_Status_Spannung
      RP_IF_KPH_Sync_XIX_Zone_VR: required-interface=IF_KPH_Sync
      RP_IF_KPH_Tasten_Fehler_XIX_Zone_VR: required-interface=IF_KPH_Tasten_Fehler
      RP_IF_KPH_Temp_Platine_XIX_Zone_VR: required-interface=IF_KPH_Temp_Platine
      RP_IF_KPH_Temp_li_XIX_Zone_VR: required-interface=IF_KPH_Temp_li
      RP_IF_KPH_Temp_re_XIX_Zone_VR: required-interface=IF_KPH_Temp_re
      RP_IF_KPH_Umluft_XIX_Zone_VR: required-interface=IF_KPH_Umluft
    component ClimateControl_VR_XIX_Innenraumheizenelektrisch_XIX_Zone_VR: type=ClimateControl_VR_XIX_Innenraumheizenelektrisch_XIX_Zone_VR
    component Grundumfang_XIX_Zone_VR: type=Grundumfang_XIX_Zone_VR
    component ThermalManagement_VR_XIX_BereitstellungAuentemperatursignal_XIX_Zone_VR: type=ThermalManagement_VR_XIX_BereitstellungAuentemperatursignal_XIX_Zone_VR
    delegate ClimateControl_VR_XIX_Innenraumheizenelektrisch_XIX_Zone_VR.SP_IF_ClActFan_perc_BlowerCurVal_S_XIX_ClimateControl_VR_XIX_Innenraumheizenelektrisch_XIX_Zone_VR <-> outer port SP_IF_ClActFan_perc_BlowerCurVal_S_XIX_Zone_VR  # _XIX_ClimateControl_VR_XIX_Innenraumheizenelektrisch_XIX_Zone_VR_XIX_ClimateControl_XIX_Innenraumheizenelektrisch_XIX_VCP_Body_XIX_ClActFan_perc_BlowerCurVal_S
    delegate ClimateControl_VR_XIX_Innenraumheizenelektrisch_XIX_Zone_VR.SP_IF_ClActFan_st_BlowerSt_S_XIX_ClimateControl_VR_XIX_Innenraumheizenelektrisch_XIX_Zone_VR <-> outer port SP_IF_ClActFan_st_BlowerSt_S_XIX_Zone_VR  # _XIX_ClimateControl_VR_XIX_Innenraumheizenelektrisch_XIX_Zone_VR_XIX_ClimateControl_XIX_Innenraumheizenelektrisch_XIX_VCP_Body_XIX_ClActFan_st_BlowerSt_S
    delegate ClimateControl_VR_XIX_Innenraumheizenelektrisch_XIX_Zone_VR.SP_IF_ClAct_perc_FlapDfrstCurVal_S_XIX_ClimateControl_VR_XIX_Innenraumheizenelektrisch_XIX_Zone_VR <-> outer port SP_IF_ClAct_perc_FlapDfrstCurVal_S_XIX_Zone_VR  # _XIX_ClimateControl_VR_XIX_Innenraumheizenelektrisch_XIX_Zone_VR_XIX_ClimateControl_XIX_Innenraumheizenelektrisch_XIX_VCP_Body_XIX_ClAct_perc_FlapDfrstCurVal_S
    delegate ClimateControl_VR_XIX_Innenraumheizenelektrisch_XIX_Zone_VR.SP_IF_ClAct_perc_FlapTFrntLeCurVal_XIX_ClimateControl_VR_XIX_Innenraumheizenelektrisch_XIX_Zone_VR <-> outer port SP_IF_ClAct_perc_FlapTFrntLeCurVal_XIX_Zone_VR  # _XIX_ClimateControl_VR_XIX_Innenraumheizenelektrisch_XIX_Zone_VR_XIX_ClimateControl_XIX_Innenraumheizenelektrisch_XIX_VCP_Body_XIX_ClAct_perc_FlapTFrntLeCurVal
    delegate ClimateControl_VR_XIX_Innenraumheizenelektrisch_XIX_Zone_VR.SP_IF_ClAct_perc_FlapTFrntRiCurVal_XIX_ClimateControl_VR_XIX_Innenraumheizenelektrisch_XIX_Zone_VR <-> outer port SP_IF_ClAct_perc_FlapTFrntRiCurVal_XIX_Zone_VR  # _XIX_ClimateControl_VR_XIX_Innenraumheizenelektrisch_XIX_Zone_VR_XIX_ClimateControl_XIX_Innenraumheizenelektrisch_XIX_VCP_Body_XIX_ClAct_perc_FlapTFrntRiCurVal
    delegate ClimateControl_VR_XIX_Innenraumheizenelektrisch_XIX_Zone_VR.SP_IF_ClAct_perc_FlapTRearLeCurVal_XIX_ClimateControl_VR_XIX_Innenraumheizenelektrisch_XIX_Zone_VR <-> outer port SP_IF_ClAct_perc_FlapTRearLeCurVal_XIX_Zone_VR  # _XIX_ClimateControl_VR_XIX_Innenraumheizenelektrisch_XIX_Zone_VR_XIX_ClimateControl_XIX_Innenraumheizenelektrisch_XIX_VCP_Body_XIX_ClAct_perc_FlapTRearLeCurVal
    delegate ClimateControl_VR_XIX_Innenraumheizenelektrisch_XIX_Zone_VR.SP_IF_ClAct_perc_FlapTRearRiCurVal_XIX_ClimateControl_VR_XIX_Innenraumheizenelektrisch_XIX_Zone_VR <-> outer port SP_IF_ClAct_perc_FlapTRearRiCurVal_XIX_Zone_VR  # _XIX_ClimateControl_VR_XIX_Innenraumheizenelektrisch_XIX_Zone_VR_XIX_ClimateControl_XIX_Innenraumheizenelektrisch_XIX_VCP_Body_XIX_ClAct_perc_FlapTRearRiCurVal
    delegate ClimateControl_VR_XIX_Innenraumheizenelektrisch_XIX_Zone_VR.SP_IF_ClAct_st_FlapDfrst_S_XIX_ClimateControl_VR_XIX_Innenraumheizenelektrisch_XIX_Zone_VR <-> outer port SP_IF_ClAct_st_FlapDfrst_S_XIX_Zone_VR  # _XIX_ClimateControl_VR_XIX_Innenraumheizenelektrisch_XIX_Zone_VR_XIX_ClimateControl_XIX_Innenraumheizenelektrisch_XIX_VCP_Body_XIX_ClAct_st_FlapDfrst_S
    delegate ClimateControl_VR_XIX_Innenraumheizenelektrisch_XIX_Zone_VR.SP_IF_ClAct_st_FlapTRearRiDfrst_XIX_ClimateControl_VR_XIX_Innenraumheizenelektrisch_XIX_Zone_VR <-> outer port SP_IF_ClAct_st_FlapTRearRiDfrst_XIX_Zone_VR  # _XIX_ClimateControl_VR_XIX_Innenraumheizenelektrisch_XIX_Zone_VR_XIX_ClimateControl_XIX_Innenraumheizenelektrisch_XIX_VCP_Body_XIX_ClAct_st_FlapTRearRiDfrst
    delegate ClimateControl_VR_XIX_Innenraumheizenelektrisch_XIX_Zone_VR.SP_IF_ClAct_st_FlapTempFrntLe_S_XIX_ClimateControl_VR_XIX_Innenraumheizenelektrisch_XIX_Zone_VR <-> outer port SP_IF_ClAct_st_FlapTempFrntLe_S_XIX_Zone_VR  # _XIX_ClimateControl_VR_XIX_Innenraumheizenelektrisch_XIX_Zone_VR_XIX_ClimateControl_XIX_Innenraumheizenelektrisch_XIX_VCP_Body_XIX_ClAct_st_FlapTempFrntLe_S
    delegate ClimateControl_VR_XIX_Innenraumheizenelektrisch_XIX_Zone_VR.SP_IF_ClAct_st_FlapTempFrntRi_S_XIX_ClimateControl_VR_XIX_Innenraumheizenelektrisch_XIX_Zone_VR <-> outer port SP_IF_ClAct_st_FlapTempFrntRi_S_XIX_Zone_VR  # _XIX_ClimateControl_VR_XIX_Innenraumheizenelektrisch_XIX_Zone_VR_XIX_ClimateControl_XIX_Innenraumheizenelektrisch_XIX_VCP_Body_XIX_ClAct_st_FlapTempFrntRi_S
    delegate ClimateControl_VR_XIX_Innenraumheizenelektrisch_XIX_Zone_VR.SP_IF_ClAct_st_FlapTempRearLe_S_XIX_ClimateControl_VR_XIX_Innenraumheizenelektrisch_XIX_Zone_VR <-> outer port SP_IF_ClAct_st_FlapTempRearLe_S_XIX_Zone_VR  # _XIX_ClimateControl_VR_XIX_Innenraumheizenelektrisch_XIX_Zone_VR_XIX_ClimateControl_XIX_Innenraumheizenelektrisch_XIX_VCP_Body_XIX_ClAct_st_FlapTempRearLe_S
    delegate ClimateControl_VR_XIX_Innenraumheizenelektrisch_XIX_Zone_VR.SP_IF_ClCcpRear_T_TarTempLe_XIX_ClimateControl_VR_XIX_Innenraumheizenelektrisch_XIX_Zone_VR <-> outer port SP_IF_ClCcpRear_T_TarTempLe_XIX_Zone_VR  # _XIX_ClimateControl_VR_XIX_Innenraumheizenelektrisch_XIX_Zone_VR_XIX_ClimateControl_XIX_Innenraumheizenelektrisch_XIX_VCP_Body_XIX_ClCcpRear_T_TarTempLe
    delegate ClimateControl_VR_XIX_Innenraumheizenelektrisch_XIX_Zone_VR.SP_IF_ClCcpRear_T_TarTempRi_XIX_ClimateControl_VR_XIX_Innenraumheizenelektrisch_XIX_Zone_VR <-> outer port SP_IF_ClCcpRear_T_TarTempRi_XIX_Zone_VR  # _XIX_ClimateControl_VR_XIX_Innenraumheizenelektrisch_XIX_Zone_VR_XIX_ClimateControl_XIX_Innenraumheizenelektrisch_XIX_VCP_Body_XIX_ClCcpRear_T_TarTempRi
    delegate ClimateControl_VR_XIX_Innenraumheizenelektrisch_XIX_Zone_VR.SP_IF_ClCcpRear_no_SetDfrst_S_XIX_ClimateControl_VR_XIX_Innenraumheizenelektrisch_XIX_Zone_VR <-> outer port SP_IF_ClCcpRear_no_SetDfrst_S_XIX_Zone_VR  # _XIX_ClimateControl_VR_XIX_Innenraumheizenelektrisch_XIX_Zone_VR_XIX_ClimateControl_XIX_Innenraumheizenelektrisch_XIX_VCP_Body_XIX_ClCcpRear_no_SetDfrst_S
    delegate ClimateControl_VR_XIX_Innenraumheizenelektrisch_XIX_Zone_VR.SP_IF_ClCcpRear_no_TarDfrst_S_XIX_ClimateControl_VR_XIX_Innenraumheizenelektrisch_XIX_Zone_VR <-> outer port SP_IF_ClCcpRear_no_TarDfrst_S_XIX_Zone_VR  # _XIX_ClimateControl_VR_XIX_Innenraumheizenelektrisch_XIX_Zone_VR_XIX_ClimateControl_XIX_Innenraumheizenelektrisch_XIX_VCP_Body_XIX_ClCcpRear_no_TarDfrst_S
    delegate ClimateControl_VR_XIX_Innenraumheizenelektrisch_XIX_Zone_VR.SP_IF_ClHmi_SetBit1_S_XIX_ClimateControl_VR_XIX_Innenraumheizenelektrisch_XIX_Zone_VR <-> outer port SP_IF_ClHmi_SetBit1_S_XIX_Zone_VR  # _XIX_ClimateControl_VR_XIX_Innenraumheizenelektrisch_XIX_Zone_VR_XIX_ClimateControl_XIX_Innenraumheizenelektrisch_XIX_VCP_Body_XIX_ClHmi_SetBit1_S
    delegate ClimateControl_VR_XIX_Innenraumheizenelektrisch_XIX_Zone_VR.SP_IF_ClHmi_SetBit2_S_XIX_ClimateControl_VR_XIX_Innenraumheizenelektrisch_XIX_Zone_VR <-> outer port SP_IF_ClHmi_SetBit2_S_XIX_Zone_VR  # _XIX_ClimateControl_VR_XIX_Innenraumheizenelektrisch_XIX_Zone_VR_XIX_ClimateControl_XIX_Innenraumheizenelektrisch_XIX_VCP_Body_XIX_ClHmi_SetBit2_S
    delegate ClimateControl_VR_XIX_Innenraumheizenelektrisch_XIX_Zone_VR.SP_IF_ClSensTemp_T_TempKGFrnt_S_XIX_ClimateControl_VR_XIX_Innenraumheizenelektrisch_XIX_Zone_VR <-> outer port SP_IF_ClSensTemp_T_TempKGFrnt_S_XIX_Zone_VR  # _XIX_ClimateControl_VR_XIX_Innenraumheizenelektrisch_XIX_Zone_VR_XIX_ClimateControl_XIX_Innenraumheizenelektrisch_XIX_VCP_Body_XIX_ClSensTemp_T_TempKGFrnt_S
    delegate ClimateControl_VR_XIX_Innenraumheizenelektrisch_XIX_Zone_VR.SP_IF_ClSensUIF_T_FilUIF_S_XIX_ClimateControl_VR_XIX_Innenraumheizenelektrisch_XIX_Zone_VR <-> outer port SP_IF_ClSensUIF_T_FilUIF_S_XIX_Zone_VR  # _XIX_ClimateControl_VR_XIX_Innenraumheizenelektrisch_XIX_Zone_VR_XIX_ClimateControl_XIX_Innenraumheizenelektrisch_XIX_VCP_Body_XIX_ClSensUIF_T_FilUIF_S
    delegate ClimateControl_VR_XIX_Innenraumheizenelektrisch_XIX_Zone_VR.SP_IF_ClSensUIF_T_ValUIF_S_XIX_ClimateControl_VR_XIX_Innenraumheizenelektrisch_XIX_Zone_VR <-> outer port SP_IF_ClSensUIF_T_ValUIF_S_XIX_Zone_VR  # _XIX_ClimateControl_VR_XIX_Innenraumheizenelektrisch_XIX_Zone_VR_XIX_ClimateControl_XIX_Innenraumheizenelektrisch_XIX_VCP_Body_XIX_ClSensUIF_T_ValUIF_S
    delegate ClimateControl_VR_XIX_Innenraumheizenelektrisch_XIX_Zone_VR.SP_IF_ClSensUIF_st_State_S_XIX_ClimateControl_VR_XIX_Innenraumheizenelektrisch_XIX_Zone_VR <-> outer port SP_IF_ClSensUIF_st_State_S_XIX_Zone_VR  # _XIX_ClimateControl_VR_XIX_Innenraumheizenelektrisch_XIX_Zone_VR_XIX_ClimateControl_XIX_Innenraumheizenelektrisch_XIX_VCP_Body_XIX_ClSensUIF_st_State_S
    delegate ClimateControl_VR_XIX_Innenraumheizenelektrisch_XIX_Zone_VR.SP_IF_KBT_CODE_VEHICLE_XIX_ClimateControl_VR_XIX_Innenraumheizenelektrisch_XIX_Zone_VR <-> outer port SP_IF_KBT_CODE_VEHICLE_XIX_Zone_VR  # _XIX_ClimateControl_VR_XIX_Innenraumheizenelektrisch_XIX_Zone_VR_XIX_GeblaeseSteuerung_XIX_Innenraumheizenelektrisch_XIX_BLDC1_XIX_KBT_CODE_VEHICLE
    delegate ClimateControl_VR_XIX_Innenraumheizenelektrisch_XIX_Zone_VR.SP_IF_KBT_RAMP_XIX_ClimateControl_VR_XIX_Innenraumheizenelektrisch_XIX_Zone_VR <-> outer port SP_IF_KBT_RAMP_XIX_Zone_VR  # _XIX_ClimateControl_VR_XIX_Innenraumheizenelektrisch_XIX_Zone_VR_XIX_GeblaeseSteuerung_XIX_Innenraumheizenelektrisch_XIX_BLDC1_XIX_KBT_RAMP
    delegate ClimateControl_VR_XIX_Innenraumheizenelektrisch_XIX_Zone_VR.SP_IF_KBT_RX_FREQUENCY_XIX_ClimateControl_VR_XIX_Innenraumheizenelektrisch_XIX_Zone_VR <-> outer port SP_IF_KBT_RX_FREQUENCY_XIX_Zone_VR  # _XIX_ClimateControl_VR_XIX_Innenraumheizenelektrisch_XIX_Zone_VR_XIX_GeblaeseSteuerung_XIX_Innenraumheizenelektrisch_XIX_BLDC1_XIX_KBT_RX_FREQUENCY
    delegate ClimateControl_VR_XIX_Innenraumheizenelektrisch_XIX_Zone_VR.SP_IF_KBT_SAFETY_SPEED_XIX_ClimateControl_VR_XIX_Innenraumheizenelektrisch_XIX_Zone_VR <-> outer port SP_IF_KBT_SAFETY_SPEED_XIX_Zone_VR  # _XIX_ClimateControl_VR_XIX_Innenraumheizenelektrisch_XIX_Zone_VR_XIX_GeblaeseSteuerung_XIX_Innenraumheizenelektrisch_XIX_BLDC1_XIX_KBT_SAFETY_SPEED
    delegate ClimateControl_VR_XIX_Innenraumheizenelektrisch_XIX_Zone_VR.SP_IF_KBT_SPEED_XIX_ClimateControl_VR_XIX_Innenraumheizenelektrisch_XIX_Zone_VR <-> outer port SP_IF_KBT_SPEED_XIX_Zone_VR  # _XIX_ClimateControl_VR_XIX_Innenraumheizenelektrisch_XIX_Zone_VR_XIX_GeblaeseSteuerung_XIX_Innenraumheizenelektrisch_XIX_BLDC1_XIX_KBT_SPEED
    delegate ClimateControl_VR_XIX_Innenraumheizenelektrisch_XIX_Zone_VR.SP_IF_KL_DI_KL_58xd_XIX_ClimateControl_VR_XIX_Innenraumheizenelektrisch_XIX_Zone_VR <-> outer port SP_IF_KL_DI_KL_58xd_XIX_Zone_VR  # _XIX_ClimateControl_VR_XIX_Innenraumheizenelektrisch_XIX_Zone_VR_XIX_KlimasteuerungHinten_XIX_Innenraumheizenelektrisch_XIX_KPH_XIX_KL_DI_KL_58xd
    delegate ClimateControl_VR_XIX_Innenraumheizenelektrisch_XIX_Zone_VR.SP_IF_KL_DI_KL_58xs_XIX_ClimateControl_VR_XIX_Innenraumheizenelektrisch_XIX_Zone_VR <-> outer port SP_IF_KL_DI_KL_58xs_XIX_Zone_VR  # _XIX_ClimateControl_VR_XIX_Innenraumheizenelektrisch_XIX_Zone_VR_XIX_KlimasteuerungHinten_XIX_Innenraumheizenelektrisch_XIX_KPH_XIX_KL_DI_KL_58xs
    delegate ClimateControl_VR_XIX_Innenraumheizenelektrisch_XIX_Zone_VR.SP_IF_KL_KST_KL_15_XIX_ClimateControl_VR_XIX_Innenraumheizenelektrisch_XIX_Zone_VR <-> outer port SP_IF_KL_KST_KL_15_XIX_Zone_VR  # _XIX_ClimateControl_VR_XIX_Innenraumheizenelektrisch_XIX_Zone_VR_XIX_KlimasteuerungHinten_XIX_Innenraumheizenelektrisch_XIX_KPH_XIX_KL_KST_KL_15
    delegate ClimateControl_VR_XIX_Innenraumheizenelektrisch_XIX_Zone_VR.SP_IF_KPHe_Auto_Toggle_XIX_ClimateControl_VR_XIX_Innenraumheizenelektrisch_XIX_Zone_VR <-> outer port SP_IF_KPHe_Auto_Toggle_XIX_Zone_VR  # _XIX_ClimateControl_VR_XIX_Innenraumheizenelektrisch_XIX_Zone_VR_XIX_KlimasteuerungHinten_XIX_Innenraumheizenelektrisch_XIX_KPH_XIX_KPHe_Auto_Toggle
    delegate ClimateControl_VR_XIX_Innenraumheizenelektrisch_XIX_Zone_VR.SP_IF_KPHe_Einheit_XIX_ClimateControl_VR_XIX_Innenraumheizenelektrisch_XIX_Zone_VR <-> outer port SP_IF_KPHe_Einheit_XIX_Zone_VR  # _XIX_ClimateControl_VR_XIX_Innenraumheizenelektrisch_XIX_Zone_VR_XIX_KlimasteuerungHinten_XIX_Innenraumheizenelektrisch_XIX_KPH_XIX_KPHe_Einheit
    delegate ClimateControl_VR_XIX_Innenraumheizenelektrisch_XIX_Zone_VR.SP_IF_KPHe_Fondbedienung_XIX_ClimateControl_VR_XIX_Innenraumheizenelektrisch_XIX_Zone_VR <-> outer port SP_IF_KPHe_Fondbedienung_XIX_Zone_VR  # _XIX_ClimateControl_VR_XIX_Innenraumheizenelektrisch_XIX_Zone_VR_XIX_KlimasteuerungHinten_XIX_Innenraumheizenelektrisch_XIX_KPH_XIX_KPHe_Fondbedienung
    delegate ClimateControl_VR_XIX_Innenraumheizenelektrisch_XIX_Zone_VR.SP_IF_KPHe_Funktion_AC_XIX_ClimateControl_VR_XIX_Innenraumheizenelektrisch_XIX_Zone_VR <-> outer port SP_IF_KPHe_Funktion_AC_XIX_Zone_VR  # _XIX_ClimateControl_VR_XIX_Innenraumheizenelektrisch_XIX_Zone_VR_XIX_KlimasteuerungHinten_XIX_Innenraumheizenelektrisch_XIX_KPH_XIX_KPHe_Funktion_AC
    delegate ClimateControl_VR_XIX_Innenraumheizenelektrisch_XIX_Zone_VR.SP_IF_KPHe_Funktion_AC_max_XIX_ClimateControl_VR_XIX_Innenraumheizenelektrisch_XIX_Zone_VR <-> outer port SP_IF_KPHe_Funktion_AC_max_XIX_Zone_VR  # _XIX_ClimateControl_VR_XIX_Innenraumheizenelektrisch_XIX_Zone_VR_XIX_KlimasteuerungHinten_XIX_Innenraumheizenelektrisch_XIX_KPH_XIX_KPHe_Funktion_AC_max
    delegate ClimateControl_VR_XIX_Innenraumheizenelektrisch_XIX_Zone_VR.SP_IF_KPHe_Funktion_Auto_li_XIX_ClimateControl_VR_XIX_Innenraumheizenelektrisch_XIX_Zone_VR <-> outer port SP_IF_KPHe_Funktion_Auto_li_XIX_Zone_VR  # _XIX_ClimateControl_VR_XIX_Innenraumheizenelektrisch_XIX_Zone_VR_XIX_KlimasteuerungHinten_XIX_Innenraumheizenelektrisch_XIX_KPH_XIX_KPHe_Funktion_Auto_li
    delegate ClimateControl_VR_XIX_Innenraumheizenelektrisch_XIX_Zone_VR.SP_IF_KPHe_Funktion_Auto_re_XIX_ClimateControl_VR_XIX_Innenraumheizenelektrisch_XIX_Zone_VR <-> outer port SP_IF_KPHe_Funktion_Auto_re_XIX_Zone_VR  # _XIX_ClimateControl_VR_XIX_Innenraumheizenelektrisch_XIX_Zone_VR_XIX_KlimasteuerungHinten_XIX_Innenraumheizenelektrisch_XIX_KPH_XIX_KPHe_Funktion_Auto_re
    delegate ClimateControl_VR_XIX_Innenraumheizenelektrisch_XIX_Zone_VR.SP_IF_KPHe_Funktion_Beduftung_XIX_ClimateControl_VR_XIX_Innenraumheizenelektrisch_XIX_Zone_VR <-> outer port SP_IF_KPHe_Funktion_Beduftung_XIX_Zone_VR  # _XIX_ClimateControl_VR_XIX_Innenraumheizenelektrisch_XIX_Zone_VR_XIX_KlimasteuerungHinten_XIX_Innenraumheizenelektrisch_XIX_KPH_XIX_KPHe_Funktion_Beduftung
    delegate ClimateControl_VR_XIX_Innenraumheizenelektrisch_XIX_Zone_VR.SP_IF_KPHe_Funktion_Defrost_XIX_ClimateControl_VR_XIX_Innenraumheizenelektrisch_XIX_Zone_VR <-> outer port SP_IF_KPHe_Funktion_Defrost_XIX_Zone_VR  # _XIX_ClimateControl_VR_XIX_Innenraumheizenelektrisch_XIX_Zone_VR_XIX_KlimasteuerungHinten_XIX_Innenraumheizenelektrisch_XIX_KPH_XIX_KPHe_Funktion_Defrost
    delegate ClimateControl_VR_XIX_Innenraumheizenelektrisch_XIX_Zone_VR.SP_IF_KPHe_Funktion_ECO_XIX_ClimateControl_VR_XIX_Innenraumheizenelektrisch_XIX_Zone_VR <-> outer port SP_IF_KPHe_Funktion_ECO_XIX_Zone_VR  # _XIX_ClimateControl_VR_XIX_Innenraumheizenelektrisch_XIX_Zone_VR_XIX_KlimasteuerungHinten_XIX_Innenraumheizenelektrisch_XIX_KPH_XIX_KPHe_Funktion_ECO
    delegate ClimateControl_VR_XIX_Innenraumheizenelektrisch_XIX_Zone_VR.SP_IF_KPHe_Funktion_ECO_Zone_XIX_ClimateControl_VR_XIX_Innenraumheizenelektrisch_XIX_Zone_VR <-> outer port SP_IF_KPHe_Funktion_ECO_Zone_XIX_Zone_VR  # _XIX_ClimateControl_VR_XIX_Innenraumheizenelektrisch_XIX_Zone_VR_XIX_KlimasteuerungHinten_XIX_Innenraumheizenelektrisch_XIX_KPH_XIX_KPHe_Funktion_ECO_Zone
    delegate ClimateControl_VR_XIX_Innenraumheizenelektrisch_XIX_Zone_VR.SP_IF_KPHe_Funktion_Flaechenheizung_XIX_ClimateControl_VR_XIX_Innenraumheizenelektrisch_XIX_Zone_VR <-> outer port SP_IF_KPHe_Funktion_Flaechenheizung_XIX_Zone_VR  # _XIX_ClimateControl_VR_XIX_Innenraumheizenelektrisch_XIX_Zone_VR_XIX_KlimasteuerungHinten_XIX_Innenraumheizenelektrisch_XIX_KPH_XIX_KPHe_Funktion_Flaechenheizung
    delegate ClimateControl_VR_XIX_Innenraumheizenelektrisch_XIX_Zone_VR.SP_IF_KPHe_Funktion_Frontbedienung_XIX_ClimateControl_VR_XIX_Innenraumheizenelektrisch_XIX_Zone_VR <-> outer port SP_IF_KPHe_Funktion_Frontbedienung_XIX_Zone_VR  # _XIX_ClimateControl_VR_XIX_Innenraumheizenelektrisch_XIX_Zone_VR_XIX_KlimasteuerungHinten_XIX_Innenraumheizenelektrisch_XIX_KPH_XIX_KPHe_Funktion_Frontbedienung
    delegate ClimateControl_VR_XIX_Innenraumheizenelektrisch_XIX_Zone_VR.SP_IF_KPHe_Funktion_Halbkreis_li_XIX_ClimateControl_VR_XIX_Innenraumheizenelektrisch_XIX_Zone_VR <-> outer port SP_IF_KPHe_Funktion_Halbkreis_li_XIX_Zone_VR  # _XIX_ClimateControl_VR_XIX_Innenraumheizenelektrisch_XIX_Zone_VR_XIX_KlimasteuerungHinten_XIX_Innenraumheizenelektrisch_XIX_KPH_XIX_KPHe_Funktion_Halbkreis_li
    delegate ClimateControl_VR_XIX_Innenraumheizenelektrisch_XIX_Zone_VR.SP_IF_KPHe_Funktion_Halbkreis_re_XIX_ClimateControl_VR_XIX_Innenraumheizenelektrisch_XIX_Zone_VR <-> outer port SP_IF_KPHe_Funktion_Halbkreis_re_XIX_Zone_VR  # _XIX_ClimateControl_VR_XIX_Innenraumheizenelektrisch_XIX_Zone_VR_XIX_KlimasteuerungHinten_XIX_Innenraumheizenelektrisch_XIX_KPH_XIX_KPHe_Funktion_Halbkreis_re
    delegate ClimateControl_VR_XIX_Innenraumheizenelektrisch_XIX_Zone_VR.SP_IF_KPHe_Funktion_Ionisator_XIX_ClimateControl_VR_XIX_Innenraumheizenelektrisch_XIX_Zone_VR <-> outer port SP_IF_KPHe_Funktion_Ionisator_XIX_Zone_VR  # _XIX_ClimateControl_VR_XIX_Innenraumheizenelektrisch_XIX_Zone_VR_XIX_KlimasteuerungHinten_XIX_Innenraumheizenelektrisch_XIX_KPH_XIX_KPHe_Funktion_Ionisator
    delegate ClimateControl_VR_XIX_Innenraumheizenelektrisch_XIX_Zone_VR.SP_IF_KPHe_Funktion_Kindersicherung_XIX_ClimateControl_VR_XIX_Innenraumheizenelektrisch_XIX_Zone_VR <-> outer port SP_IF_KPHe_Funktion_Kindersicherung_XIX_Zone_VR  # _XIX_ClimateControl_VR_XIX_Innenraumheizenelektrisch_XIX_Zone_VR_XIX_KlimasteuerungHinten_XIX_Innenraumheizenelektrisch_XIX_KPH_XIX_KPHe_Funktion_Kindersicherung
    delegate ClimateControl_VR_XIX_Innenraumheizenelektrisch_XIX_Zone_VR.SP_IF_KPHe_Funktion_Off_XIX_ClimateControl_VR_XIX_Innenraumheizenelektrisch_XIX_Zone_VR <-> outer port SP_IF_KPHe_Funktion_Off_XIX_Zone_VR  # _XIX_ClimateControl_VR_XIX_Innenraumheizenelektrisch_XIX_Zone_VR_XIX_KlimasteuerungHinten_XIX_Innenraumheizenelektrisch_XIX_KPH_XIX_KPHe_Funktion_Off
    delegate ClimateControl_VR_XIX_Innenraumheizenelektrisch_XIX_Zone_VR.SP_IF_KPHe_Funktion_Sync_XIX_ClimateControl_VR_XIX_Innenraumheizenelektrisch_XIX_Zone_VR <-> outer port SP_IF_KPHe_Funktion_Sync_XIX_Zone_VR  # _XIX_ClimateControl_VR_XIX_Innenraumheizenelektrisch_XIX_Zone_VR_XIX_KlimasteuerungHinten_XIX_Innenraumheizenelektrisch_XIX_KPH_XIX_KPHe_Funktion_Sync
    delegate ClimateControl_VR_XIX_Innenraumheizenelektrisch_XIX_Zone_VR.SP_IF_KPHe_Funktion_Umluft_XIX_ClimateControl_VR_XIX_Innenraumheizenelektrisch_XIX_Zone_VR <-> outer port SP_IF_KPHe_Funktion_Umluft_XIX_Zone_VR  # _XIX_ClimateControl_VR_XIX_Innenraumheizenelektrisch_XIX_Zone_VR_XIX_KlimasteuerungHinten_XIX_Innenraumheizenelektrisch_XIX_KPH_XIX_KPHe_Funktion_Umluft
    delegate ClimateControl_VR_XIX_Innenraumheizenelektrisch_XIX_Zone_VR.SP_IF_KPHe_Funktionsbeleuchtung_XIX_ClimateControl_VR_XIX_Innenraumheizenelektrisch_XIX_Zone_VR <-> outer port SP_IF_KPHe_Funktionsbeleuchtung_XIX_Zone_VR  # _XIX_ClimateControl_VR_XIX_Innenraumheizenelektrisch_XIX_Zone_VR_XIX_KlimasteuerungHinten_XIX_Innenraumheizenelektrisch_XIX_KPH_XIX_KPHe_Funktionsbeleuchtung
    delegate ClimateControl_VR_XIX_Innenraumheizenelektrisch_XIX_Zone_VR.SP_IF_KPHe_Fzg_Steigung_XIX_ClimateControl_VR_XIX_Innenraumheizenelektrisch_XIX_Zone_VR <-> outer port SP_IF_KPHe_Fzg_Steigung_XIX_Zone_VR  # _XIX_ClimateControl_VR_XIX_Innenraumheizenelektrisch_XIX_Zone_VR_XIX_KlimasteuerungHinten_XIX_Innenraumheizenelektrisch_XIX_KPH_XIX_KPHe_Fzg_Steigung
    delegate ClimateControl_VR_XIX_Innenraumheizenelektrisch_XIX_Zone_VR.SP_IF_KPHe_Geblaese_Auto_li_XIX_ClimateControl_VR_XIX_Innenraumheizenelektrisch_XIX_Zone_VR <-> outer port SP_IF_KPHe_Geblaese_Auto_li_XIX_Zone_VR  # _XIX_ClimateControl_VR_XIX_Innenraumheizenelektrisch_XIX_Zone_VR_XIX_KlimasteuerungHinten_XIX_Innenraumheizenelektrisch_XIX_KPH_XIX_KPHe_Geblaese_Auto_li
    delegate ClimateControl_VR_XIX_Innenraumheizenelektrisch_XIX_Zone_VR.SP_IF_KPHe_Geblaese_Auto_re_XIX_ClimateControl_VR_XIX_Innenraumheizenelektrisch_XIX_Zone_VR <-> outer port SP_IF_KPHe_Geblaese_Auto_re_XIX_Zone_VR  # _XIX_ClimateControl_VR_XIX_Innenraumheizenelektrisch_XIX_Zone_VR_XIX_KlimasteuerungHinten_XIX_Innenraumheizenelektrisch_XIX_KPH_XIX_KPHe_Geblaese_Auto_re
    delegate ClimateControl_VR_XIX_Innenraumheizenelektrisch_XIX_Zone_VR.SP_IF_KPHe_Geblaese_Begrenzung_XIX_ClimateControl_VR_XIX_Innenraumheizenelektrisch_XIX_Zone_VR <-> outer port SP_IF_KPHe_Geblaese_Begrenzung_XIX_Zone_VR  # _XIX_ClimateControl_VR_XIX_Innenraumheizenelektrisch_XIX_Zone_VR_XIX_KlimasteuerungHinten_XIX_Innenraumheizenelektrisch_XIX_KPH_XIX_KPHe_Geblaese_Begrenzung
    delegate ClimateControl_VR_XIX_Innenraumheizenelektrisch_XIX_Zone_VR.SP_IF_KPHe_Geblaese_Stufe_li_XIX_ClimateControl_VR_XIX_Innenraumheizenelektrisch_XIX_Zone_VR <-> outer port SP_IF_KPHe_Geblaese_Stufe_li_XIX_Zone_VR  # _XIX_ClimateControl_VR_XIX_Innenraumheizenelektrisch_XIX_Zone_VR_XIX_KlimasteuerungHinten_XIX_Innenraumheizenelektrisch_XIX_KPH_XIX_KPHe_Geblaese_Stufe_li
    delegate ClimateControl_VR_XIX_Innenraumheizenelektrisch_XIX_Zone_VR.SP_IF_KPHe_Geblaese_Stufe_re_XIX_ClimateControl_VR_XIX_Innenraumheizenelektrisch_XIX_Zone_VR <-> outer port SP_IF_KPHe_Geblaese_Stufe_re_XIX_Zone_VR  # _XIX_ClimateControl_VR_XIX_Innenraumheizenelektrisch_XIX_Zone_VR_XIX_KlimasteuerungHinten_XIX_Innenraumheizenelektrisch_XIX_KPH_XIX_KPHe_Geblaese_Stufe_re
    delegate ClimateControl_VR_XIX_Innenraumheizenelektrisch_XIX_Zone_VR.SP_IF_KPHe_LCD_XIX_ClimateControl_VR_XIX_Innenraumheizenelektrisch_XIX_Zone_VR <-> outer port SP_IF_KPHe_LCD_XIX_Zone_VR  # _XIX_ClimateControl_VR_XIX_Innenraumheizenelektrisch_XIX_Zone_VR_XIX_KlimasteuerungHinten_XIX_Innenraumheizenelektrisch_XIX_KPH_XIX_KPHe_LCD
    delegate ClimateControl_VR_XIX_Innenraumheizenelektrisch_XIX_Zone_VR.SP_IF_KPHe_Lenker_Position_XIX_ClimateControl_VR_XIX_Innenraumheizenelektrisch_XIX_Zone_VR <-> outer port SP_IF_KPHe_Lenker_Position_XIX_Zone_VR  # _XIX_ClimateControl_VR_XIX_Innenraumheizenelektrisch_XIX_Zone_VR_XIX_KlimasteuerungHinten_XIX_Innenraumheizenelektrisch_XIX_KPH_XIX_KPHe_Lenker_Position
    delegate ClimateControl_VR_XIX_Innenraumheizenelektrisch_XIX_Zone_VR.SP_IF_KPHe_Luftverteilung_Auto_li_XIX_ClimateControl_VR_XIX_Innenraumheizenelektrisch_XIX_Zone_VR <-> outer port SP_IF_KPHe_Luftverteilung_Auto_li_XIX_Zone_VR  # _XIX_ClimateControl_VR_XIX_Innenraumheizenelektrisch_XIX_Zone_VR_XIX_KlimasteuerungHinten_XIX_Innenraumheizenelektrisch_XIX_KPH_XIX_KPHe_Luftverteilung_Auto_li
    delegate ClimateControl_VR_XIX_Innenraumheizenelektrisch_XIX_Zone_VR.SP_IF_KPHe_Luftverteilung_Auto_re_XIX_ClimateControl_VR_XIX_Innenraumheizenelektrisch_XIX_Zone_VR <-> outer port SP_IF_KPHe_Luftverteilung_Auto_re_XIX_Zone_VR  # _XIX_ClimateControl_VR_XIX_Innenraumheizenelektrisch_XIX_Zone_VR_XIX_KlimasteuerungHinten_XIX_Innenraumheizenelektrisch_XIX_KPH_XIX_KPHe_Luftverteilung_Auto_re
    delegate ClimateControl_VR_XIX_Innenraumheizenelektrisch_XIX_Zone_VR.SP_IF_KPHe_Luftverteilung_Mitte_li_XIX_ClimateControl_VR_XIX_Innenraumheizenelektrisch_XIX_Zone_VR <-> outer port SP_IF_KPHe_Luftverteilung_Mitte_li_XIX_Zone_VR  # _XIX_ClimateControl_VR_XIX_Innenraumheizenelektrisch_XIX_Zone_VR_XIX_KlimasteuerungHinten_XIX_Innenraumheizenelektrisch_XIX_KPH_XIX_KPHe_Luftverteilung_Mitte_li
    delegate ClimateControl_VR_XIX_Innenraumheizenelektrisch_XIX_Zone_VR.SP_IF_KPHe_Luftverteilung_Mitte_re_XIX_ClimateControl_VR_XIX_Innenraumheizenelektrisch_XIX_Zone_VR <-> outer port SP_IF_KPHe_Luftverteilung_Mitte_re_XIX_Zone_VR  # _XIX_ClimateControl_VR_XIX_Innenraumheizenelektrisch_XIX_Zone_VR_XIX_KlimasteuerungHinten_XIX_Innenraumheizenelektrisch_XIX_KPH_XIX_KPHe_Luftverteilung_Mitte_re
    delegate ClimateControl_VR_XIX_Innenraumheizenelektrisch_XIX_Zone_VR.SP_IF_KPHe_Luftverteilung_Oben_li_XIX_ClimateControl_VR_XIX_Innenraumheizenelektrisch_XIX_Zone_VR <-> outer port SP_IF_KPHe_Luftverteilung_Oben_li_XIX_Zone_VR  # _XIX_ClimateControl_VR_XIX_Innenraumheizenelektrisch_XIX_Zone_VR_XIX_KlimasteuerungHinten_XIX_Innenraumheizenelektrisch_XIX_KPH_XIX_KPHe_Luftverteilung_Oben_li
    delegate ClimateControl_VR_XIX_Innenraumheizenelektrisch_XIX_Zone_VR.SP_IF_KPHe_Luftverteilung_Oben_re_XIX_ClimateControl_VR_XIX_Innenraumheizenelektrisch_XIX_Zone_VR <-> outer port SP_IF_KPHe_Luftverteilung_Oben_re_XIX_Zone_VR  # _XIX_ClimateControl_VR_XIX_Innenraumheizenelektrisch_XIX_Zone_VR_XIX_KlimasteuerungHinten_XIX_Innenraumheizenelektrisch_XIX_KPH_XIX_KPHe_Luftverteilung_Oben_re
    delegate ClimateControl_VR_XIX_Innenraumheizenelektrisch_XIX_Zone_VR.SP_IF_KPHe_Luftverteilung_Unten_li_XIX_ClimateControl_VR_XIX_Innenraumheizenelektrisch_XIX_Zone_VR <-> outer port SP_IF_KPHe_Luftverteilung_Unten_li_XIX_Zone_VR  # _XIX_ClimateControl_VR_XIX_Innenraumheizenelektrisch_XIX_Zone_VR_XIX_KlimasteuerungHinten_XIX_Innenraumheizenelektrisch_XIX_KPH_XIX_KPHe_Luftverteilung_Unten_li
    delegate ClimateControl_VR_XIX_Innenraumheizenelektrisch_XIX_Zone_VR.SP_IF_KPHe_Luftverteilung_Unten_re_XIX_ClimateControl_VR_XIX_Innenraumheizenelektrisch_XIX_Zone_VR <-> outer port SP_IF_KPHe_Luftverteilung_Unten_re_XIX_Zone_VR  # _XIX_ClimateControl_VR_XIX_Innenraumheizenelektrisch_XIX_Zone_VR_XIX_KlimasteuerungHinten_XIX_Innenraumheizenelektrisch_XIX_KPH_XIX_KPHe_Luftverteilung_Unten_re
    delegate ClimateControl_VR_XIX_Innenraumheizenelektrisch_XIX_Zone_VR.SP_IF_KPHe_QBit_Steigung_XIX_ClimateControl_VR_XIX_Innenraumheizenelektrisch_XIX_Zone_VR <-> outer port SP_IF_KPHe_QBit_Steigung_XIX_Zone_VR  # _XIX_ClimateControl_VR_XIX_Innenraumheizenelektrisch_XIX_Zone_VR_XIX_KlimasteuerungHinten_XIX_Innenraumheizenelektrisch_XIX_KPH_XIX_KPHe_QBit_Steigung
    delegate ClimateControl_VR_XIX_Innenraumheizenelektrisch_XIX_Zone_VR.SP_IF_KPHe_Radio_Frequenz_XIX_ClimateControl_VR_XIX_Innenraumheizenelektrisch_XIX_Zone_VR <-> outer port SP_IF_KPHe_Radio_Frequenz_XIX_Zone_VR  # _XIX_ClimateControl_VR_XIX_Innenraumheizenelektrisch_XIX_Zone_VR_XIX_KlimasteuerungHinten_XIX_Innenraumheizenelektrisch_XIX_KPH_XIX_KPHe_Radio_Frequenz
    delegate ClimateControl_VR_XIX_Innenraumheizenelektrisch_XIX_Zone_VR.SP_IF_KPHe_Sitzheizung_li_XIX_ClimateControl_VR_XIX_Innenraumheizenelektrisch_XIX_Zone_VR <-> outer port SP_IF_KPHe_Sitzheizung_li_XIX_Zone_VR  # _XIX_ClimateControl_VR_XIX_Innenraumheizenelektrisch_XIX_Zone_VR_XIX_KlimasteuerungHinten_XIX_Innenraumheizenelektrisch_XIX_KPH_XIX_KPHe_Sitzheizung_li
    delegate ClimateControl_VR_XIX_Innenraumheizenelektrisch_XIX_Zone_VR.SP_IF_KPHe_Sitzheizung_re_XIX_ClimateControl_VR_XIX_Innenraumheizenelektrisch_XIX_Zone_VR <-> outer port SP_IF_KPHe_Sitzheizung_re_XIX_Zone_VR  # _XIX_ClimateControl_VR_XIX_Innenraumheizenelektrisch_XIX_Zone_VR_XIX_KlimasteuerungHinten_XIX_Innenraumheizenelektrisch_XIX_KPH_XIX_KPHe_Sitzheizung_re
    delegate ClimateControl_VR_XIX_Innenraumheizenelektrisch_XIX_Zone_VR.SP_IF_KPHe_Sitzlueftung_li_XIX_ClimateControl_VR_XIX_Innenraumheizenelektrisch_XIX_Zone_VR <-> outer port SP_IF_KPHe_Sitzlueftung_li_XIX_Zone_VR  # _XIX_ClimateControl_VR_XIX_Innenraumheizenelektrisch_XIX_Zone_VR_XIX_KlimasteuerungHinten_XIX_Innenraumheizenelektrisch_XIX_KPH_XIX_KPHe_Sitzlueftung_li
    delegate ClimateControl_VR_XIX_Innenraumheizenelektrisch_XIX_Zone_VR.SP_IF_KPHe_Sitzlueftung_re_XIX_ClimateControl_VR_XIX_Innenraumheizenelektrisch_XIX_Zone_VR <-> outer port SP_IF_KPHe_Sitzlueftung_re_XIX_Zone_VR  # _XIX_ClimateControl_VR_XIX_Innenraumheizenelektrisch_XIX_Zone_VR_XIX_KlimasteuerungHinten_XIX_Innenraumheizenelektrisch_XIX_KPH_XIX_KPHe_Sitzlueftung_re
    delegate ClimateControl_VR_XIX_Innenraumheizenelektrisch_XIX_Zone_VR.SP_IF_KPHe_Stellgliedtest_XIX_ClimateControl_VR_XIX_Innenraumheizenelektrisch_XIX_Zone_VR <-> outer port SP_IF_KPHe_Stellgliedtest_XIX_Zone_VR  # _XIX_ClimateControl_VR_XIX_Innenraumheizenelektrisch_XIX_Zone_VR_XIX_KlimasteuerungHinten_XIX_Innenraumheizenelektrisch_XIX_KPH_XIX_KPHe_Stellgliedtest
    delegate ClimateControl_VR_XIX_Innenraumheizenelektrisch_XIX_Zone_VR.SP_IF_KPHe_Suchbeleuchtung_XIX_ClimateControl_VR_XIX_Innenraumheizenelektrisch_XIX_Zone_VR <-> outer port SP_IF_KPHe_Suchbeleuchtung_XIX_Zone_VR  # _XIX_ClimateControl_VR_XIX_Innenraumheizenelektrisch_XIX_Zone_VR_XIX_KlimasteuerungHinten_XIX_Innenraumheizenelektrisch_XIX_KPH_XIX_KPHe_Suchbeleuchtung
    delegate ClimateControl_VR_XIX_Innenraumheizenelektrisch_XIX_Zone_VR.SP_IF_KPHe_Symbol_Luftmenge_li_XIX_ClimateControl_VR_XIX_Innenraumheizenelektrisch_XIX_Zone_VR <-> outer port SP_IF_KPHe_Symbol_Luftmenge_li_XIX_Zone_VR  # _XIX_ClimateControl_VR_XIX_Innenraumheizenelektrisch_XIX_Zone_VR_XIX_KlimasteuerungHinten_XIX_Innenraumheizenelektrisch_XIX_KPH_XIX_KPHe_Symbol_Luftmenge_li
    delegate ClimateControl_VR_XIX_Innenraumheizenelektrisch_XIX_Zone_VR.SP_IF_KPHe_Symbol_Luftmenge_re_XIX_ClimateControl_VR_XIX_Innenraumheizenelektrisch_XIX_Zone_VR <-> outer port SP_IF_KPHe_Symbol_Luftmenge_re_XIX_Zone_VR  # _XIX_ClimateControl_VR_XIX_Innenraumheizenelektrisch_XIX_Zone_VR_XIX_KlimasteuerungHinten_XIX_Innenraumheizenelektrisch_XIX_KPH_XIX_KPHe_Symbol_Luftmenge_re
    delegate ClimateControl_VR_XIX_Innenraumheizenelektrisch_XIX_Zone_VR.SP_IF_KPHe_Symbol_Luftverteilung_li_XIX_ClimateControl_VR_XIX_Innenraumheizenelektrisch_XIX_Zone_VR <-> outer port SP_IF_KPHe_Symbol_Luftverteilung_li_XIX_Zone_VR  # _XIX_ClimateControl_VR_XIX_Innenraumheizenelektrisch_XIX_Zone_VR_XIX_KlimasteuerungHinten_XIX_Innenraumheizenelektrisch_XIX_KPH_XIX_KPHe_Symbol_Luftverteilung_li
    delegate ClimateControl_VR_XIX_Innenraumheizenelektrisch_XIX_Zone_VR.SP_IF_KPHe_Symbol_Luftverteilung_re_XIX_ClimateControl_VR_XIX_Innenraumheizenelektrisch_XIX_Zone_VR <-> outer port SP_IF_KPHe_Symbol_Luftverteilung_re_XIX_Zone_VR  # _XIX_ClimateControl_VR_XIX_Innenraumheizenelektrisch_XIX_Zone_VR_XIX_KlimasteuerungHinten_XIX_Innenraumheizenelektrisch_XIX_KPH_XIX_KPHe_Symbol_Luftverteilung_re
    delegate ClimateControl_VR_XIX_Innenraumheizenelektrisch_XIX_Zone_VR.SP_IF_KPHe_Symbol_Sitzheizung_li_XIX_ClimateControl_VR_XIX_Innenraumheizenelektrisch_XIX_Zone_VR <-> outer port SP_IF_KPHe_Symbol_Sitzheizung_li_XIX_Zone_VR  # _XIX_ClimateControl_VR_XIX_Innenraumheizenelektrisch_XIX_Zone_VR_XIX_KlimasteuerungHinten_XIX_Innenraumheizenelektrisch_XIX_KPH_XIX_KPHe_Symbol_Sitzheizung_li
    delegate ClimateControl_VR_XIX_Innenraumheizenelektrisch_XIX_Zone_VR.SP_IF_KPHe_Symbol_Sitzheizung_re_XIX_ClimateControl_VR_XIX_Innenraumheizenelektrisch_XIX_Zone_VR <-> outer port SP_IF_KPHe_Symbol_Sitzheizung_re_XIX_Zone_VR  # _XIX_ClimateControl_VR_XIX_Innenraumheizenelektrisch_XIX_Zone_VR_XIX_KlimasteuerungHinten_XIX_Innenraumheizenelektrisch_XIX_KPH_XIX_KPHe_Symbol_Sitzheizung_re
    delegate ClimateControl_VR_XIX_Innenraumheizenelektrisch_XIX_Zone_VR.SP_IF_KPHe_Symbol_Sitzlueftung_li_XIX_ClimateControl_VR_XIX_Innenraumheizenelektrisch_XIX_Zone_VR <-> outer port SP_IF_KPHe_Symbol_Sitzlueftung_li_XIX_Zone_VR  # _XIX_ClimateControl_VR_XIX_Innenraumheizenelektrisch_XIX_Zone_VR_XIX_KlimasteuerungHinten_XIX_Innenraumheizenelektrisch_XIX_KPH_XIX_KPHe_Symbol_Sitzlueftung_li
    delegate ClimateControl_VR_XIX_Innenraumheizenelektrisch_XIX_Zone_VR.SP_IF_KPHe_Symbol_Sitzlueftung_re_XIX_ClimateControl_VR_XIX_Innenraumheizenelektrisch_XIX_Zone_VR <-> outer port SP_IF_KPHe_Symbol_Sitzlueftung_re_XIX_Zone_VR  # _XIX_ClimateControl_VR_XIX_Innenraumheizenelektrisch_XIX_Zone_VR_XIX_KlimasteuerungHinten_XIX_Innenraumheizenelektrisch_XIX_KPH_XIX_KPHe_Symbol_Sitzlueftung_re
    delegate ClimateControl_VR_XIX_Innenraumheizenelektrisch_XIX_Zone_VR.SP_IF_KPHe_TFT_XIX_ClimateControl_VR_XIX_Innenraumheizenelektrisch_XIX_Zone_VR <-> outer port SP_IF_KPHe_TFT_XIX_Zone_VR  # _XIX_ClimateControl_VR_XIX_Innenraumheizenelektrisch_XIX_Zone_VR_XIX_KlimasteuerungHinten_XIX_Innenraumheizenelektrisch_XIX_KPH_XIX_KPHe_TFT
    delegate ClimateControl_VR_XIX_Innenraumheizenelektrisch_XIX_Zone_VR.SP_IF_KPHe_Temp_li_XIX_ClimateControl_VR_XIX_Innenraumheizenelektrisch_XIX_Zone_VR <-> outer port SP_IF_KPHe_Temp_li_XIX_Zone_VR  # _XIX_ClimateControl_VR_XIX_Innenraumheizenelektrisch_XIX_Zone_VR_XIX_KlimasteuerungHinten_XIX_Innenraumheizenelektrisch_XIX_KPH_XIX_KPHe_Temp_li
    delegate ClimateControl_VR_XIX_Innenraumheizenelektrisch_XIX_Zone_VR.SP_IF_KPHe_Temp_re_XIX_ClimateControl_VR_XIX_Innenraumheizenelektrisch_XIX_Zone_VR <-> outer port SP_IF_KPHe_Temp_re_XIX_Zone_VR  # _XIX_ClimateControl_VR_XIX_Innenraumheizenelektrisch_XIX_Zone_VR_XIX_KlimasteuerungHinten_XIX_Innenraumheizenelektrisch_XIX_KPH_XIX_KPHe_Temp_re
    delegate ClimateControl_VR_XIX_Innenraumheizenelektrisch_XIX_Zone_VR.SP_IF_STRG100a_Adresse_XIX_ClimateControl_VR_XIX_Innenraumheizenelektrisch_XIX_Zone_VR <-> outer port SP_IF_STRG100a_Adresse_XIX_Zone_VR  # _XIX_ClimateControl_VR_XIX_Innenraumheizenelektrisch_XIX_Zone_VR_XIX_Klappen104aStellen_XIX_Innenraumheizenelektrisch_XIX_ACT_104a_XIX_STRG100a_Adresse
    delegate ClimateControl_VR_XIX_Innenraumheizenelektrisch_XIX_Zone_VR.SP_IF_STRG100a_Clear_Event_Flags_XIX_ClimateControl_VR_XIX_Innenraumheizenelektrisch_XIX_Zone_VR <-> outer port SP_IF_STRG100a_Clear_Event_Flags_XIX_Zone_VR  # _XIX_ClimateControl_VR_XIX_Innenraumheizenelektrisch_XIX_Zone_VR_XIX_Klappen104aStellen_XIX_Innenraumheizenelektrisch_XIX_ACT_104a_XIX_STRG100a_Clear_Event_Flags
    delegate ClimateControl_VR_XIX_Innenraumheizenelektrisch_XIX_Zone_VR.SP_IF_STRG100a_Drehrichtung_XIX_ClimateControl_VR_XIX_Innenraumheizenelektrisch_XIX_Zone_VR <-> outer port SP_IF_STRG100a_Drehrichtung_XIX_Zone_VR  # _XIX_ClimateControl_VR_XIX_Innenraumheizenelektrisch_XIX_Zone_VR_XIX_Klappen104aStellen_XIX_Innenraumheizenelektrisch_XIX_ACT_104a_XIX_STRG100a_Drehrichtung
    delegate ClimateControl_VR_XIX_Innenraumheizenelektrisch_XIX_Zone_VR.SP_IF_STRG100a_Freig_Blockiererkennung_XIX_ClimateControl_VR_XIX_Innenraumheizenelektrisch_XIX_Zone_VR <-> outer port SP_IF_STRG100a_Freig_Blockiererkennung_XIX_Zone_VR  # _XIX_ClimateControl_VR_XIX_Innenraumheizenelektrisch_XIX_Zone_VR_XIX_Klappen104aStellen_XIX_Innenraumheizenelektrisch_XIX_ACT_104a_XIX_STRG100a_Freig_Blockiererkennung
    delegate ClimateControl_VR_XIX_Innenraumheizenelektrisch_XIX_Zone_VR.SP_IF_STRG100a_Geschwindigkeitsvorgabe_XIX_ClimateControl_VR_XIX_Innenraumheizenelektrisch_XIX_Zone_VR <-> outer port SP_IF_STRG100a_Geschwindigkeitsvorgabe_XIX_Zone_VR  # _XIX_ClimateControl_VR_XIX_Innenraumheizenelektrisch_XIX_Zone_VR_XIX_Klappen104aStellen_XIX_Innenraumheizenelektrisch_XIX_ACT_104a_XIX_STRG100a_Geschwindigkeitsvorgabe
    delegate ClimateControl_VR_XIX_Innenraumheizenelektrisch_XIX_Zone_VR.SP_IF_STRG100a_Notlauffreigabe_XIX_ClimateControl_VR_XIX_Innenraumheizenelektrisch_XIX_Zone_VR <-> outer port SP_IF_STRG100a_Notlauffreigabe_XIX_Zone_VR  # _XIX_ClimateControl_VR_XIX_Innenraumheizenelektrisch_XIX_Zone_VR_XIX_Klappen104aStellen_XIX_Innenraumheizenelektrisch_XIX_ACT_104a_XIX_STRG100a_Notlauffreigabe
    delegate ClimateControl_VR_XIX_Innenraumheizenelektrisch_XIX_Zone_VR.SP_IF_STRG100a_Notlaufposition_XIX_ClimateControl_VR_XIX_Innenraumheizenelektrisch_XIX_Zone_VR <-> outer port SP_IF_STRG100a_Notlaufposition_XIX_Zone_VR  # _XIX_ClimateControl_VR_XIX_Innenraumheizenelektrisch_XIX_Zone_VR_XIX_Klappen104aStellen_XIX_Innenraumheizenelektrisch_XIX_ACT_104a_XIX_STRG100a_Notlaufposition
    delegate ClimateControl_VR_XIX_Innenraumheizenelektrisch_XIX_Zone_VR.SP_IF_STRG100a_PrgDaten_speichern_XIX_ClimateControl_VR_XIX_Innenraumheizenelektrisch_XIX_Zone_VR <-> outer port SP_IF_STRG100a_PrgDaten_speichern_XIX_Zone_VR  # _XIX_ClimateControl_VR_XIX_Innenraumheizenelektrisch_XIX_Zone_VR_XIX_Klappen104aStellen_XIX_Innenraumheizenelektrisch_XIX_ACT_104a_XIX_STRG100a_PrgDaten_speichern
    delegate ClimateControl_VR_XIX_Innenraumheizenelektrisch_XIX_Zone_VR.SP_IF_STRG100a_Select_Positionsvorgabe_XIX_ClimateControl_VR_XIX_Innenraumheizenelektrisch_XIX_Zone_VR <-> outer port SP_IF_STRG100a_Select_Positionsvorgabe_XIX_Zone_VR  # _XIX_ClimateControl_VR_XIX_Innenraumheizenelektrisch_XIX_Zone_VR_XIX_Klappen104aStellen_XIX_Innenraumheizenelektrisch_XIX_ACT_104a_XIX_STRG100a_Select_Positionsvorgabe
    delegate ClimateControl_VR_XIX_Innenraumheizenelektrisch_XIX_Zone_VR.SP_IF_STRG100a_Soll_Position_XIX_ClimateControl_VR_XIX_Innenraumheizenelektrisch_XIX_Zone_VR <-> outer port SP_IF_STRG100a_Soll_Position_XIX_Zone_VR  # _XIX_ClimateControl_VR_XIX_Innenraumheizenelektrisch_XIX_Zone_VR_XIX_Klappen104aStellen_XIX_Innenraumheizenelektrisch_XIX_ACT_104a_XIX_STRG100a_Soll_Position
    delegate ClimateControl_VR_XIX_Innenraumheizenelektrisch_XIX_Zone_VR.SP_IF_STRG100a_Spulenhaltebestromung_XIX_ClimateControl_VR_XIX_Innenraumheizenelektrisch_XIX_Zone_VR <-> outer port SP_IF_STRG100a_Spulenhaltebestromung_XIX_Zone_VR  # _XIX_ClimateControl_VR_XIX_Innenraumheizenelektrisch_XIX_Zone_VR_XIX_Klappen104aStellen_XIX_Innenraumheizenelektrisch_XIX_ACT_104a_XIX_STRG100a_Spulenhaltebestromung
    delegate ClimateControl_VR_XIX_Innenraumheizenelektrisch_XIX_Zone_VR.SP_IF_STRG100a_Start_Position_XIX_ClimateControl_VR_XIX_Innenraumheizenelektrisch_XIX_Zone_VR <-> outer port SP_IF_STRG100a_Start_Position_XIX_Zone_VR  # _XIX_ClimateControl_VR_XIX_Innenraumheizenelektrisch_XIX_Zone_VR_XIX_Klappen104aStellen_XIX_Innenraumheizenelektrisch_XIX_ACT_104a_XIX_STRG100a_Start_Position
    delegate ClimateControl_VR_XIX_Innenraumheizenelektrisch_XIX_Zone_VR.SP_IF_STRG100a_Stopmodus_XIX_ClimateControl_VR_XIX_Innenraumheizenelektrisch_XIX_Zone_VR <-> outer port SP_IF_STRG100a_Stopmodus_XIX_Zone_VR  # _XIX_ClimateControl_VR_XIX_Innenraumheizenelektrisch_XIX_Zone_VR_XIX_Klappen104aStellen_XIX_Innenraumheizenelektrisch_XIX_ACT_104a_XIX_STRG100a_Stopmodus
    delegate ClimateControl_VR_XIX_Innenraumheizenelektrisch_XIX_Zone_VR.SP_IF_STRG100f_Adresse_XIX_ClimateControl_VR_XIX_Innenraumheizenelektrisch_XIX_Zone_VR <-> outer port SP_IF_STRG100f_Adresse_XIX_Zone_VR  # _XIX_ClimateControl_VR_XIX_Innenraumheizenelektrisch_XIX_Zone_VR_XIX_Klappen102fStellen_XIX_Innenraumheizenelektrisch_XIX_ACT_102f_XIX_STRG100f_Adresse
    delegate ClimateControl_VR_XIX_Innenraumheizenelektrisch_XIX_Zone_VR.SP_IF_STRG100f_Clear_Event_Flags_XIX_ClimateControl_VR_XIX_Innenraumheizenelektrisch_XIX_Zone_VR <-> outer port SP_IF_STRG100f_Clear_Event_Flags_XIX_Zone_VR  # _XIX_ClimateControl_VR_XIX_Innenraumheizenelektrisch_XIX_Zone_VR_XIX_Klappen102fStellen_XIX_Innenraumheizenelektrisch_XIX_ACT_102f_XIX_STRG100f_Clear_Event_Flags
    delegate ClimateControl_VR_XIX_Innenraumheizenelektrisch_XIX_Zone_VR.SP_IF_STRG100f_Drehrichtung_XIX_ClimateControl_VR_XIX_Innenraumheizenelektrisch_XIX_Zone_VR <-> outer port SP_IF_STRG100f_Drehrichtung_XIX_Zone_VR  # _XIX_ClimateControl_VR_XIX_Innenraumheizenelektrisch_XIX_Zone_VR_XIX_Klappen102fStellen_XIX_Innenraumheizenelektrisch_XIX_ACT_102f_XIX_STRG100f_Drehrichtung
    delegate ClimateControl_VR_XIX_Innenraumheizenelektrisch_XIX_Zone_VR.SP_IF_STRG100f_Freig_Blockiererkennung_XIX_ClimateControl_VR_XIX_Innenraumheizenelektrisch_XIX_Zone_VR <-> outer port SP_IF_STRG100f_Freig_Blockiererkennung_XIX_Zone_VR  # _XIX_ClimateControl_VR_XIX_Innenraumheizenelektrisch_XIX_Zone_VR_XIX_Klappen102fStellen_XIX_Innenraumheizenelektrisch_XIX_ACT_102f_XIX_STRG100f_Freig_Blockiererkennung
    delegate ClimateControl_VR_XIX_Innenraumheizenelektrisch_XIX_Zone_VR.SP_IF_STRG100f_Geschwindigkeitsvorgabe_XIX_ClimateControl_VR_XIX_Innenraumheizenelektrisch_XIX_Zone_VR <-> outer port SP_IF_STRG100f_Geschwindigkeitsvorgabe_XIX_Zone_VR  # _XIX_ClimateControl_VR_XIX_Innenraumheizenelektrisch_XIX_Zone_VR_XIX_Klappen102fStellen_XIX_Innenraumheizenelektrisch_XIX_ACT_102f_XIX_STRG100f_Geschwindigkeitsvorgabe
    delegate ClimateControl_VR_XIX_Innenraumheizenelektrisch_XIX_Zone_VR.SP_IF_STRG100f_Notlauffreigabe_XIX_ClimateControl_VR_XIX_Innenraumheizenelektrisch_XIX_Zone_VR <-> outer port SP_IF_STRG100f_Notlauffreigabe_XIX_Zone_VR  # _XIX_ClimateControl_VR_XIX_Innenraumheizenelektrisch_XIX_Zone_VR_XIX_Klappen102fStellen_XIX_Innenraumheizenelektrisch_XIX_ACT_102f_XIX_STRG100f_Notlauffreigabe
    delegate ClimateControl_VR_XIX_Innenraumheizenelektrisch_XIX_Zone_VR.SP_IF_STRG100f_Notlaufposition_XIX_ClimateControl_VR_XIX_Innenraumheizenelektrisch_XIX_Zone_VR <-> outer port SP_IF_STRG100f_Notlaufposition_XIX_Zone_VR  # _XIX_ClimateControl_VR_XIX_Innenraumheizenelektrisch_XIX_Zone_VR_XIX_Klappen102fStellen_XIX_Innenraumheizenelektrisch_XIX_ACT_102f_XIX_STRG100f_Notlaufposition
    delegate ClimateControl_VR_XIX_Innenraumheizenelektrisch_XIX_Zone_VR.SP_IF_STRG100f_PrgDaten_speichern_XIX_ClimateControl_VR_XIX_Innenraumheizenelektrisch_XIX_Zone_VR <-> outer port SP_IF_STRG100f_PrgDaten_speichern_XIX_Zone_VR  # _XIX_ClimateControl_VR_XIX_Innenraumheizenelektrisch_XIX_Zone_VR_XIX_Klappen102fStellen_XIX_Innenraumheizenelektrisch_XIX_ACT_102f_XIX_STRG100f_PrgDaten_speichern
    delegate ClimateControl_VR_XIX_Innenraumheizenelektrisch_XIX_Zone_VR.SP_IF_STRG100f_Select_Positionsvorgabe_XIX_ClimateControl_VR_XIX_Innenraumheizenelektrisch_XIX_Zone_VR <-> outer port SP_IF_STRG100f_Select_Positionsvorgabe_XIX_Zone_VR  # _XIX_ClimateControl_VR_XIX_Innenraumheizenelektrisch_XIX_Zone_VR_XIX_Klappen102fStellen_XIX_Innenraumheizenelektrisch_XIX_ACT_102f_XIX_STRG100f_Select_Positionsvorgabe
    delegate ClimateControl_VR_XIX_Innenraumheizenelektrisch_XIX_Zone_VR.SP_IF_STRG100f_Soll_Position_XIX_ClimateControl_VR_XIX_Innenraumheizenelektrisch_XIX_Zone_VR <-> outer port SP_IF_STRG100f_Soll_Position_XIX_Zone_VR  # _XIX_ClimateControl_VR_XIX_Innenraumheizenelektrisch_XIX_Zone_VR_XIX_Klappen102fStellen_XIX_Innenraumheizenelektrisch_XIX_ACT_102f_XIX_STRG100f_Soll_Position
    delegate ClimateControl_VR_XIX_Innenraumheizenelektrisch_XIX_Zone_VR.SP_IF_STRG100f_Spulenhaltebestromung_XIX_ClimateControl_VR_XIX_Innenraumheizenelektrisch_XIX_Zone_VR <-> outer port SP_IF_STRG100f_Spulenhaltebestromung_XIX_Zone_VR  # _XIX_ClimateControl_VR_XIX_Innenraumheizenelektrisch_XIX_Zone_VR_XIX_Klappen102fStellen_XIX_Innenraumheizenelektrisch_XIX_ACT_102f_XIX_STRG100f_Spulenhaltebestromung
    delegate ClimateControl_VR_XIX_Innenraumheizenelektrisch_XIX_Zone_VR.SP_IF_STRG100f_Start_Position_XIX_ClimateControl_VR_XIX_Innenraumheizenelektrisch_XIX_Zone_VR <-> outer port SP_IF_STRG100f_Start_Position_XIX_Zone_VR  # _XIX_ClimateControl_VR_XIX_Innenraumheizenelektrisch_XIX_Zone_VR_XIX_Klappen102fStellen_XIX_Innenraumheizenelektrisch_XIX_ACT_102f_XIX_STRG100f_Start_Position
    delegate ClimateControl_VR_XIX_Innenraumheizenelektrisch_XIX_Zone_VR.SP_IF_STRG100f_Stopmodus_XIX_ClimateControl_VR_XIX_Innenraumheizenelektrisch_XIX_Zone_VR <-> outer port SP_IF_STRG100f_Stopmodus_XIX_Zone_VR  # _XIX_ClimateControl_VR_XIX_Innenraumheizenelektrisch_XIX_Zone_VR_XIX_Klappen102fStellen_XIX_Innenraumheizenelektrisch_XIX_ACT_102f_XIX_STRG100f_Stopmodus
    delegate ClimateControl_VR_XIX_Innenraumheizenelektrisch_XIX_Zone_VR.SP_IF_STRG102f_Adresse_XIX_ClimateControl_VR_XIX_Innenraumheizenelektrisch_XIX_Zone_VR <-> outer port SP_IF_STRG102f_Adresse_XIX_Zone_VR  # _XIX_ClimateControl_VR_XIX_Innenraumheizenelektrisch_XIX_Zone_VR_XIX_Klappen102fStellen_XIX_Innenraumheizenelektrisch_XIX_ACT_102f_XIX_STRG102f_Adresse
    delegate ClimateControl_VR_XIX_Innenraumheizenelektrisch_XIX_Zone_VR.SP_IF_STRG102f_Clear_Event_Flags_XIX_ClimateControl_VR_XIX_Innenraumheizenelektrisch_XIX_Zone_VR <-> outer port SP_IF_STRG102f_Clear_Event_Flags_XIX_Zone_VR  # _XIX_ClimateControl_VR_XIX_Innenraumheizenelektrisch_XIX_Zone_VR_XIX_Klappen102fStellen_XIX_Innenraumheizenelektrisch_XIX_ACT_102f_XIX_STRG102f_Clear_Event_Flags
    delegate ClimateControl_VR_XIX_Innenraumheizenelektrisch_XIX_Zone_VR.SP_IF_STRG102f_Drehrichtung_XIX_ClimateControl_VR_XIX_Innenraumheizenelektrisch_XIX_Zone_VR <-> outer port SP_IF_STRG102f_Drehrichtung_XIX_Zone_VR  # _XIX_ClimateControl_VR_XIX_Innenraumheizenelektrisch_XIX_Zone_VR_XIX_Klappen102fStellen_XIX_Innenraumheizenelektrisch_XIX_ACT_102f_XIX_STRG102f_Drehrichtung
    delegate ClimateControl_VR_XIX_Innenraumheizenelektrisch_XIX_Zone_VR.SP_IF_STRG102f_Freig_Blockiererkennung_XIX_ClimateControl_VR_XIX_Innenraumheizenelektrisch_XIX_Zone_VR <-> outer port SP_IF_STRG102f_Freig_Blockiererkennung_XIX_Zone_VR  # _XIX_ClimateControl_VR_XIX_Innenraumheizenelektrisch_XIX_Zone_VR_XIX_Klappen102fStellen_XIX_Innenraumheizenelektrisch_XIX_ACT_102f_XIX_STRG102f_Freig_Blockiererkennung
    delegate ClimateControl_VR_XIX_Innenraumheizenelektrisch_XIX_Zone_VR.SP_IF_STRG102f_Geschwindigkeitsvorgabe_XIX_ClimateControl_VR_XIX_Innenraumheizenelektrisch_XIX_Zone_VR <-> outer port SP_IF_STRG102f_Geschwindigkeitsvorgabe_XIX_Zone_VR  # _XIX_ClimateControl_VR_XIX_Innenraumheizenelektrisch_XIX_Zone_VR_XIX_Klappen102fStellen_XIX_Innenraumheizenelektrisch_XIX_ACT_102f_XIX_STRG102f_Geschwindigkeitsvorgabe
    delegate ClimateControl_VR_XIX_Innenraumheizenelektrisch_XIX_Zone_VR.SP_IF_STRG102f_Notlauffreigabe_XIX_ClimateControl_VR_XIX_Innenraumheizenelektrisch_XIX_Zone_VR <-> outer port SP_IF_STRG102f_Notlauffreigabe_XIX_Zone_VR  # _XIX_ClimateControl_VR_XIX_Innenraumheizenelektrisch_XIX_Zone_VR_XIX_Klappen102fStellen_XIX_Innenraumheizenelektrisch_XIX_ACT_102f_XIX_STRG102f_Notlauffreigabe
    delegate ClimateControl_VR_XIX_Innenraumheizenelektrisch_XIX_Zone_VR.SP_IF_STRG102f_Notlaufposition_XIX_ClimateControl_VR_XIX_Innenraumheizenelektrisch_XIX_Zone_VR <-> outer port SP_IF_STRG102f_Notlaufposition_XIX_Zone_VR  # _XIX_ClimateControl_VR_XIX_Innenraumheizenelektrisch_XIX_Zone_VR_XIX_Klappen102fStellen_XIX_Innenraumheizenelektrisch_XIX_ACT_102f_XIX_STRG102f_Notlaufposition
    delegate ClimateControl_VR_XIX_Innenraumheizenelektrisch_XIX_Zone_VR.SP_IF_STRG102f_PrgDaten_speichern_XIX_ClimateControl_VR_XIX_Innenraumheizenelektrisch_XIX_Zone_VR <-> outer port SP_IF_STRG102f_PrgDaten_speichern_XIX_Zone_VR  # _XIX_ClimateControl_VR_XIX_Innenraumheizenelektrisch_XIX_Zone_VR_XIX_Klappen102fStellen_XIX_Innenraumheizenelektrisch_XIX_ACT_102f_XIX_STRG102f_PrgDaten_speichern
    delegate ClimateControl_VR_XIX_Innenraumheizenelektrisch_XIX_Zone_VR.SP_IF_STRG102f_Select_Positionsvorgabe_XIX_ClimateControl_VR_XIX_Innenraumheizenelektrisch_XIX_Zone_VR <-> outer port SP_IF_STRG102f_Select_Positionsvorgabe_XIX_Zone_VR  # _XIX_ClimateControl_VR_XIX_Innenraumheizenelektrisch_XIX_Zone_VR_XIX_Klappen102fStellen_XIX_Innenraumheizenelektrisch_XIX_ACT_102f_XIX_STRG102f_Select_Positionsvorgabe
    delegate ClimateControl_VR_XIX_Innenraumheizenelektrisch_XIX_Zone_VR.SP_IF_STRG102f_Soll_Position_XIX_ClimateControl_VR_XIX_Innenraumheizenelektrisch_XIX_Zone_VR <-> outer port SP_IF_STRG102f_Soll_Position_XIX_Zone_VR  # _XIX_ClimateControl_VR_XIX_Innenraumheizenelektrisch_XIX_Zone_VR_XIX_Klappen102fStellen_XIX_Innenraumheizenelektrisch_XIX_ACT_102f_XIX_STRG102f_Soll_Position
    delegate ClimateControl_VR_XIX_Innenraumheizenelektrisch_XIX_Zone_VR.SP_IF_STRG102f_Spulenhaltebestromung_XIX_ClimateControl_VR_XIX_Innenraumheizenelektrisch_XIX_Zone_VR <-> outer port SP_IF_STRG102f_Spulenhaltebestromung_XIX_Zone_VR  # _XIX_ClimateControl_VR_XIX_Innenraumheizenelektrisch_XIX_Zone_VR_XIX_Klappen102fStellen_XIX_Innenraumheizenelektrisch_XIX_ACT_102f_XIX_STRG102f_Spulenhaltebestromung
    delegate ClimateControl_VR_XIX_Innenraumheizenelektrisch_XIX_Zone_VR.SP_IF_STRG102f_Start_Position_XIX_ClimateControl_VR_XIX_Innenraumheizenelektrisch_XIX_Zone_VR <-> outer port SP_IF_STRG102f_Start_Position_XIX_Zone_VR  # _XIX_ClimateControl_VR_XIX_Innenraumheizenelektrisch_XIX_Zone_VR_XIX_Klappen102fStellen_XIX_Innenraumheizenelektrisch_XIX_ACT_102f_XIX_STRG102f_Start_Position
    delegate ClimateControl_VR_XIX_Innenraumheizenelektrisch_XIX_Zone_VR.SP_IF_STRG102f_Stopmodus_XIX_ClimateControl_VR_XIX_Innenraumheizenelektrisch_XIX_Zone_VR <-> outer port SP_IF_STRG102f_Stopmodus_XIX_Zone_VR  # _XIX_ClimateControl_VR_XIX_Innenraumheizenelektrisch_XIX_Zone_VR_XIX_Klappen102fStellen_XIX_Innenraumheizenelektrisch_XIX_ACT_102f_XIX_STRG102f_Stopmodus
    delegate ClimateControl_VR_XIX_Innenraumheizenelektrisch_XIX_Zone_VR.SP_IF_STRG104a_Adresse_XIX_ClimateControl_VR_XIX_Innenraumheizenelektrisch_XIX_Zone_VR <-> outer port SP_IF_STRG104a_Adresse_XIX_Zone_VR  # _XIX_ClimateControl_VR_XIX_Innenraumheizenelektrisch_XIX_Zone_VR_XIX_Klappen104aStellen_XIX_Innenraumheizenelektrisch_XIX_ACT_104a_XIX_STRG104a_Adresse
    delegate ClimateControl_VR_XIX_Innenraumheizenelektrisch_XIX_Zone_VR.SP_IF_STRG104a_Clear_Event_Flags_XIX_ClimateControl_VR_XIX_Innenraumheizenelektrisch_XIX_Zone_VR <-> outer port SP_IF_STRG104a_Clear_Event_Flags_XIX_Zone_VR  # _XIX_ClimateControl_VR_XIX_Innenraumheizenelektrisch_XIX_Zone_VR_XIX_Klappen104aStellen_XIX_Innenraumheizenelektrisch_XIX_ACT_104a_XIX_STRG104a_Clear_Event_Flags
    delegate ClimateControl_VR_XIX_Innenraumheizenelektrisch_XIX_Zone_VR.SP_IF_STRG104a_Drehrichtung_XIX_ClimateControl_VR_XIX_Innenraumheizenelektrisch_XIX_Zone_VR <-> outer port SP_IF_STRG104a_Drehrichtung_XIX_Zone_VR  # _XIX_ClimateControl_VR_XIX_Innenraumheizenelektrisch_XIX_Zone_VR_XIX_Klappen104aStellen_XIX_Innenraumheizenelektrisch_XIX_ACT_104a_XIX_STRG104a_Drehrichtung
    delegate ClimateControl_VR_XIX_Innenraumheizenelektrisch_XIX_Zone_VR.SP_IF_STRG104a_Freig_Blockiererkennung_XIX_ClimateControl_VR_XIX_Innenraumheizenelektrisch_XIX_Zone_VR <-> outer port SP_IF_STRG104a_Freig_Blockiererkennung_XIX_Zone_VR  # _XIX_ClimateControl_VR_XIX_Innenraumheizenelektrisch_XIX_Zone_VR_XIX_Klappen104aStellen_XIX_Innenraumheizenelektrisch_XIX_ACT_104a_XIX_STRG104a_Freig_Blockiererkennung
    delegate ClimateControl_VR_XIX_Innenraumheizenelektrisch_XIX_Zone_VR.SP_IF_STRG104a_Geschwindigkeitsvorgabe_XIX_ClimateControl_VR_XIX_Innenraumheizenelektrisch_XIX_Zone_VR <-> outer port SP_IF_STRG104a_Geschwindigkeitsvorgabe_XIX_Zone_VR  # _XIX_ClimateControl_VR_XIX_Innenraumheizenelektrisch_XIX_Zone_VR_XIX_Klappen104aStellen_XIX_Innenraumheizenelektrisch_XIX_ACT_104a_XIX_STRG104a_Geschwindigkeitsvorgabe
    delegate ClimateControl_VR_XIX_Innenraumheizenelektrisch_XIX_Zone_VR.SP_IF_STRG104a_Notlauffreigabe_XIX_ClimateControl_VR_XIX_Innenraumheizenelektrisch_XIX_Zone_VR <-> outer port SP_IF_STRG104a_Notlauffreigabe_XIX_Zone_VR  # _XIX_ClimateControl_VR_XIX_Innenraumheizenelektrisch_XIX_Zone_VR_XIX_Klappen104aStellen_XIX_Innenraumheizenelektrisch_XIX_ACT_104a_XIX_STRG104a_Notlauffreigabe
    delegate ClimateControl_VR_XIX_Innenraumheizenelektrisch_XIX_Zone_VR.SP_IF_STRG104a_Notlaufposition_XIX_ClimateControl_VR_XIX_Innenraumheizenelektrisch_XIX_Zone_VR <-> outer port SP_IF_STRG104a_Notlaufposition_XIX_Zone_VR  # _XIX_ClimateControl_VR_XIX_Innenraumheizenelektrisch_XIX_Zone_VR_XIX_Klappen104aStellen_XIX_Innenraumheizenelektrisch_XIX_ACT_104a_XIX_STRG104a_Notlaufposition
    delegate ClimateControl_VR_XIX_Innenraumheizenelektrisch_XIX_Zone_VR.SP_IF_STRG104a_PrgDaten_speichern_XIX_ClimateControl_VR_XIX_Innenraumheizenelektrisch_XIX_Zone_VR <-> outer port SP_IF_STRG104a_PrgDaten_speichern_XIX_Zone_VR  # _XIX_ClimateControl_VR_XIX_Innenraumheizenelektrisch_XIX_Zone_VR_XIX_Klappen104aStellen_XIX_Innenraumheizenelektrisch_XIX_ACT_104a_XIX_STRG104a_PrgDaten_speichern
    delegate ClimateControl_VR_XIX_Innenraumheizenelektrisch_XIX_Zone_VR.SP_IF_STRG104a_Select_Positionsvorgabe_XIX_ClimateControl_VR_XIX_Innenraumheizenelektrisch_XIX_Zone_VR <-> outer port SP_IF_STRG104a_Select_Positionsvorgabe_XIX_Zone_VR  # _XIX_ClimateControl_VR_XIX_Innenraumheizenelektrisch_XIX_Zone_VR_XIX_Klappen104aStellen_XIX_Innenraumheizenelektrisch_XIX_ACT_104a_XIX_STRG104a_Select_Positionsvorgabe
    delegate ClimateControl_VR_XIX_Innenraumheizenelektrisch_XIX_Zone_VR.SP_IF_STRG104a_Soll_Position_XIX_ClimateControl_VR_XIX_Innenraumheizenelektrisch_XIX_Zone_VR <-> outer port SP_IF_STRG104a_Soll_Position_XIX_Zone_VR  # _XIX_ClimateControl_VR_XIX_Innenraumheizenelektrisch_XIX_Zone_VR_XIX_Klappen104aStellen_XIX_Innenraumheizenelektrisch_XIX_ACT_104a_XIX_STRG104a_Soll_Position
    delegate ClimateControl_VR_XIX_Innenraumheizenelektrisch_XIX_Zone_VR.SP_IF_STRG104a_Spulenhaltebestromung_XIX_ClimateControl_VR_XIX_Innenraumheizenelektrisch_XIX_Zone_VR <-> outer port SP_IF_STRG104a_Spulenhaltebestromung_XIX_Zone_VR  # _XIX_ClimateControl_VR_XIX_Innenraumheizenelektrisch_XIX_Zone_VR_XIX_Klappen104aStellen_XIX_Innenraumheizenelektrisch_XIX_ACT_104a_XIX_STRG104a_Spulenhaltebestromung
    delegate ClimateControl_VR_XIX_Innenraumheizenelektrisch_XIX_Zone_VR.SP_IF_STRG104a_Start_Position_XIX_ClimateControl_VR_XIX_Innenraumheizenelektrisch_XIX_Zone_VR <-> outer port SP_IF_STRG104a_Start_Position_XIX_Zone_VR  # _XIX_ClimateControl_VR_XIX_Innenraumheizenelektrisch_XIX_Zone_VR_XIX_Klappen104aStellen_XIX_Innenraumheizenelektrisch_XIX_ACT_104a_XIX_STRG104a_Start_Position
    delegate ClimateControl_VR_XIX_Innenraumheizenelektrisch_XIX_Zone_VR.SP_IF_STRG104a_Stopmodus_XIX_ClimateControl_VR_XIX_Innenraumheizenelektrisch_XIX_Zone_VR <-> outer port SP_IF_STRG104a_Stopmodus_XIX_Zone_VR  # _XIX_ClimateControl_VR_XIX_Innenraumheizenelektrisch_XIX_Zone_VR_XIX_Klappen104aStellen_XIX_Innenraumheizenelektrisch_XIX_ACT_104a_XIX_STRG104a_Stopmodus
    delegate ClimateControl_VR_XIX_Innenraumheizenelektrisch_XIX_Zone_VR.SP_IF_STRG105a_Adresse_XIX_ClimateControl_VR_XIX_Innenraumheizenelektrisch_XIX_Zone_VR <-> outer port SP_IF_STRG105a_Adresse_XIX_Zone_VR  # _XIX_ClimateControl_VR_XIX_Innenraumheizenelektrisch_XIX_Zone_VR_XIX_Klappen105aStellen_XIX_Innenraumheizenelektrisch_XIX_ACT_105a_XIX_STRG105a_Adresse
    delegate ClimateControl_VR_XIX_Innenraumheizenelektrisch_XIX_Zone_VR.SP_IF_STRG105a_Clear_Event_Flags_XIX_ClimateControl_VR_XIX_Innenraumheizenelektrisch_XIX_Zone_VR <-> outer port SP_IF_STRG105a_Clear_Event_Flags_XIX_Zone_VR  # _XIX_ClimateControl_VR_XIX_Innenraumheizenelektrisch_XIX_Zone_VR_XIX_Klappen105aStellen_XIX_Innenraumheizenelektrisch_XIX_ACT_105a_XIX_STRG105a_Clear_Event_Flags
    delegate ClimateControl_VR_XIX_Innenraumheizenelektrisch_XIX_Zone_VR.SP_IF_STRG105a_Drehrichtung_XIX_ClimateControl_VR_XIX_Innenraumheizenelektrisch_XIX_Zone_VR <-> outer port SP_IF_STRG105a_Drehrichtung_XIX_Zone_VR  # _XIX_ClimateControl_VR_XIX_Innenraumheizenelektrisch_XIX_Zone_VR_XIX_Klappen105aStellen_XIX_Innenraumheizenelektrisch_XIX_ACT_105a_XIX_STRG105a_Drehrichtung
    delegate ClimateControl_VR_XIX_Innenraumheizenelektrisch_XIX_Zone_VR.SP_IF_STRG105a_Freig_Blockiererkennung_XIX_ClimateControl_VR_XIX_Innenraumheizenelektrisch_XIX_Zone_VR <-> outer port SP_IF_STRG105a_Freig_Blockiererkennung_XIX_Zone_VR  # _XIX_ClimateControl_VR_XIX_Innenraumheizenelektrisch_XIX_Zone_VR_XIX_Klappen105aStellen_XIX_Innenraumheizenelektrisch_XIX_ACT_105a_XIX_STRG105a_Freig_Blockiererkennung
    delegate ClimateControl_VR_XIX_Innenraumheizenelektrisch_XIX_Zone_VR.SP_IF_STRG105a_Geschwindigkeitsvorgabe_XIX_ClimateControl_VR_XIX_Innenraumheizenelektrisch_XIX_Zone_VR <-> outer port SP_IF_STRG105a_Geschwindigkeitsvorgabe_XIX_Zone_VR  # _XIX_ClimateControl_VR_XIX_Innenraumheizenelektrisch_XIX_Zone_VR_XIX_Klappen105aStellen_XIX_Innenraumheizenelektrisch_XIX_ACT_105a_XIX_STRG105a_Geschwindigkeitsvorgabe
    delegate ClimateControl_VR_XIX_Innenraumheizenelektrisch_XIX_Zone_VR.SP_IF_STRG105a_Notlauffreigabe_XIX_ClimateControl_VR_XIX_Innenraumheizenelektrisch_XIX_Zone_VR <-> outer port SP_IF_STRG105a_Notlauffreigabe_XIX_Zone_VR  # _XIX_ClimateControl_VR_XIX_Innenraumheizenelektrisch_XIX_Zone_VR_XIX_Klappen105aStellen_XIX_Innenraumheizenelektrisch_XIX_ACT_105a_XIX_STRG105a_Notlauffreigabe
    delegate ClimateControl_VR_XIX_Innenraumheizenelektrisch_XIX_Zone_VR.SP_IF_STRG105a_Notlaufposition_XIX_ClimateControl_VR_XIX_Innenraumheizenelektrisch_XIX_Zone_VR <-> outer port SP_IF_STRG105a_Notlaufposition_XIX_Zone_VR  # _XIX_ClimateControl_VR_XIX_Innenraumheizenelektrisch_XIX_Zone_VR_XIX_Klappen105aStellen_XIX_Innenraumheizenelektrisch_XIX_ACT_105a_XIX_STRG105a_Notlaufposition
    delegate ClimateControl_VR_XIX_Innenraumheizenelektrisch_XIX_Zone_VR.SP_IF_STRG105a_PrgDaten_speichern_XIX_ClimateControl_VR_XIX_Innenraumheizenelektrisch_XIX_Zone_VR <-> outer port SP_IF_STRG105a_PrgDaten_speichern_XIX_Zone_VR  # _XIX_ClimateControl_VR_XIX_Innenraumheizenelektrisch_XIX_Zone_VR_XIX_Klappen105aStellen_XIX_Innenraumheizenelektrisch_XIX_ACT_105a_XIX_STRG105a_PrgDaten_speichern
    delegate ClimateControl_VR_XIX_Innenraumheizenelektrisch_XIX_Zone_VR.SP_IF_STRG105a_Select_Positionsvorgabe_XIX_ClimateControl_VR_XIX_Innenraumheizenelektrisch_XIX_Zone_VR <-> outer port SP_IF_STRG105a_Select_Positionsvorgabe_XIX_Zone_VR  # _XIX_ClimateControl_VR_XIX_Innenraumheizenelektrisch_XIX_Zone_VR_XIX_Klappen105aStellen_XIX_Innenraumheizenelektrisch_XIX_ACT_105a_XIX_STRG105a_Select_Positionsvorgabe
    delegate ClimateControl_VR_XIX_Innenraumheizenelektrisch_XIX_Zone_VR.SP_IF_STRG105a_Soll_Position_XIX_ClimateControl_VR_XIX_Innenraumheizenelektrisch_XIX_Zone_VR <-> outer port SP_IF_STRG105a_Soll_Position_XIX_Zone_VR  # _XIX_ClimateControl_VR_XIX_Innenraumheizenelektrisch_XIX_Zone_VR_XIX_Klappen105aStellen_XIX_Innenraumheizenelektrisch_XIX_ACT_105a_XIX_STRG105a_Soll_Position
    delegate ClimateControl_VR_XIX_Innenraumheizenelektrisch_XIX_Zone_VR.SP_IF_STRG105a_Spulenhaltebestromung_XIX_ClimateControl_VR_XIX_Innenraumheizenelektrisch_XIX_Zone_VR <-> outer port SP_IF_STRG105a_Spulenhaltebestromung_XIX_Zone_VR  # _XIX_ClimateControl_VR_XIX_Innenraumheizenelektrisch_XIX_Zone_VR_XIX_Klappen105aStellen_XIX_Innenraumheizenelektrisch_XIX_ACT_105a_XIX_STRG105a_Spulenhaltebestromung
    delegate ClimateControl_VR_XIX_Innenraumheizenelektrisch_XIX_Zone_VR.SP_IF_STRG105a_Start_Position_XIX_ClimateControl_VR_XIX_Innenraumheizenelektrisch_XIX_Zone_VR <-> outer port SP_IF_STRG105a_Start_Position_XIX_Zone_VR  # _XIX_ClimateControl_VR_XIX_Innenraumheizenelektrisch_XIX_Zone_VR_XIX_Klappen105aStellen_XIX_Innenraumheizenelektrisch_XIX_ACT_105a_XIX_STRG105a_Start_Position
    delegate ClimateControl_VR_XIX_Innenraumheizenelektrisch_XIX_Zone_VR.SP_IF_STRG105a_Stopmodus_XIX_ClimateControl_VR_XIX_Innenraumheizenelektrisch_XIX_Zone_VR <-> outer port SP_IF_STRG105a_Stopmodus_XIX_Zone_VR  # _XIX_ClimateControl_VR_XIX_Innenraumheizenelektrisch_XIX_Zone_VR_XIX_Klappen105aStellen_XIX_Innenraumheizenelektrisch_XIX_ACT_105a_XIX_STRG105a_Stopmodus
    delegate ClimateControl_VR_XIX_Innenraumheizenelektrisch_XIX_Zone_VR.SP_IF_STRG106a_Adresse_XIX_ClimateControl_VR_XIX_Innenraumheizenelektrisch_XIX_Zone_VR <-> outer port SP_IF_STRG106a_Adresse_XIX_Zone_VR  # _XIX_ClimateControl_VR_XIX_Innenraumheizenelektrisch_XIX_Zone_VR_XIX_Klappen106aStellen_XIX_Innenraumheizenelektrisch_XIX_ACT_106a_XIX_STRG106a_Adresse
    delegate ClimateControl_VR_XIX_Innenraumheizenelektrisch_XIX_Zone_VR.SP_IF_STRG106a_Clear_Event_Flags_XIX_ClimateControl_VR_XIX_Innenraumheizenelektrisch_XIX_Zone_VR <-> outer port SP_IF_STRG106a_Clear_Event_Flags_XIX_Zone_VR  # _XIX_ClimateControl_VR_XIX_Innenraumheizenelektrisch_XIX_Zone_VR_XIX_Klappen106aStellen_XIX_Innenraumheizenelektrisch_XIX_ACT_106a_XIX_STRG106a_Clear_Event_Flags
    delegate ClimateControl_VR_XIX_Innenraumheizenelektrisch_XIX_Zone_VR.SP_IF_STRG106a_Drehrichtung_XIX_ClimateControl_VR_XIX_Innenraumheizenelektrisch_XIX_Zone_VR <-> outer port SP_IF_STRG106a_Drehrichtung_XIX_Zone_VR  # _XIX_ClimateControl_VR_XIX_Innenraumheizenelektrisch_XIX_Zone_VR_XIX_Klappen106aStellen_XIX_Innenraumheizenelektrisch_XIX_ACT_106a_XIX_STRG106a_Drehrichtung
    delegate ClimateControl_VR_XIX_Innenraumheizenelektrisch_XIX_Zone_VR.SP_IF_STRG106a_Freig_Blockiererkennung_XIX_ClimateControl_VR_XIX_Innenraumheizenelektrisch_XIX_Zone_VR <-> outer port SP_IF_STRG106a_Freig_Blockiererkennung_XIX_Zone_VR  # _XIX_ClimateControl_VR_XIX_Innenraumheizenelektrisch_XIX_Zone_VR_XIX_Klappen106aStellen_XIX_Innenraumheizenelektrisch_XIX_ACT_106a_XIX_STRG106a_Freig_Blockiererkennung
    delegate ClimateControl_VR_XIX_Innenraumheizenelektrisch_XIX_Zone_VR.SP_IF_STRG106a_Geschwindigkeitsvorgabe_XIX_ClimateControl_VR_XIX_Innenraumheizenelektrisch_XIX_Zone_VR <-> outer port SP_IF_STRG106a_Geschwindigkeitsvorgabe_XIX_Zone_VR  # _XIX_ClimateControl_VR_XIX_Innenraumheizenelektrisch_XIX_Zone_VR_XIX_Klappen106aStellen_XIX_Innenraumheizenelektrisch_XIX_ACT_106a_XIX_STRG106a_Geschwindigkeitsvorgabe
    delegate ClimateControl_VR_XIX_Innenraumheizenelektrisch_XIX_Zone_VR.SP_IF_STRG106a_Notlauffreigabe_XIX_ClimateControl_VR_XIX_Innenraumheizenelektrisch_XIX_Zone_VR <-> outer port SP_IF_STRG106a_Notlauffreigabe_XIX_Zone_VR  # _XIX_ClimateControl_VR_XIX_Innenraumheizenelektrisch_XIX_Zone_VR_XIX_Klappen106aStellen_XIX_Innenraumheizenelektrisch_XIX_ACT_106a_XIX_STRG106a_Notlauffreigabe
    delegate ClimateControl_VR_XIX_Innenraumheizenelektrisch_XIX_Zone_VR.SP_IF_STRG106a_Notlaufposition_XIX_ClimateControl_VR_XIX_Innenraumheizenelektrisch_XIX_Zone_VR <-> outer port SP_IF_STRG106a_Notlaufposition_XIX_Zone_VR  # _XIX_ClimateControl_VR_XIX_Innenraumheizenelektrisch_XIX_Zone_VR_XIX_Klappen106aStellen_XIX_Innenraumheizenelektrisch_XIX_ACT_106a_XIX_STRG106a_Notlaufposition
    delegate ClimateControl_VR_XIX_Innenraumheizenelektrisch_XIX_Zone_VR.SP_IF_STRG106a_PrgDaten_speichern_XIX_ClimateControl_VR_XIX_Innenraumheizenelektrisch_XIX_Zone_VR <-> outer port SP_IF_STRG106a_PrgDaten_speichern_XIX_Zone_VR  # _XIX_ClimateControl_VR_XIX_Innenraumheizenelektrisch_XIX_Zone_VR_XIX_Klappen106aStellen_XIX_Innenraumheizenelektrisch_XIX_ACT_106a_XIX_STRG106a_PrgDaten_speichern
    delegate ClimateControl_VR_XIX_Innenraumheizenelektrisch_XIX_Zone_VR.SP_IF_STRG106a_Select_Positionsvorgabe_XIX_ClimateControl_VR_XIX_Innenraumheizenelektrisch_XIX_Zone_VR <-> outer port SP_IF_STRG106a_Select_Positionsvorgabe_XIX_Zone_VR  # _XIX_ClimateControl_VR_XIX_Innenraumheizenelektrisch_XIX_Zone_VR_XIX_Klappen106aStellen_XIX_Innenraumheizenelektrisch_XIX_ACT_106a_XIX_STRG106a_Select_Positionsvorgabe
    delegate ClimateControl_VR_XIX_Innenraumheizenelektrisch_XIX_Zone_VR.SP_IF_STRG106a_Soll_Position_XIX_ClimateControl_VR_XIX_Innenraumheizenelektrisch_XIX_Zone_VR <-> outer port SP_IF_STRG106a_Soll_Position_XIX_Zone_VR  # _XIX_ClimateControl_VR_XIX_Innenraumheizenelektrisch_XIX_Zone_VR_XIX_Klappen106aStellen_XIX_Innenraumheizenelektrisch_XIX_ACT_106a_XIX_STRG106a_Soll_Position
    delegate ClimateControl_VR_XIX_Innenraumheizenelektrisch_XIX_Zone_VR.SP_IF_STRG106a_Spulenhaltebestromung_XIX_ClimateControl_VR_XIX_Innenraumheizenelektrisch_XIX_Zone_VR <-> outer port SP_IF_STRG106a_Spulenhaltebestromung_XIX_Zone_VR  # _XIX_ClimateControl_VR_XIX_Innenraumheizenelektrisch_XIX_Zone_VR_XIX_Klappen106aStellen_XIX_Innenraumheizenelektrisch_XIX_ACT_106a_XIX_STRG106a_Spulenhaltebestromung
    delegate ClimateControl_VR_XIX_Innenraumheizenelektrisch_XIX_Zone_VR.SP_IF_STRG106a_Start_Position_XIX_ClimateControl_VR_XIX_Innenraumheizenelektrisch_XIX_Zone_VR <-> outer port SP_IF_STRG106a_Start_Position_XIX_Zone_VR  # _XIX_ClimateControl_VR_XIX_Innenraumheizenelektrisch_XIX_Zone_VR_XIX_Klappen106aStellen_XIX_Innenraumheizenelektrisch_XIX_ACT_106a_XIX_STRG106a_Start_Position
    delegate ClimateControl_VR_XIX_Innenraumheizenelektrisch_XIX_Zone_VR.SP_IF_STRG106a_Stopmodus_XIX_ClimateControl_VR_XIX_Innenraumheizenelektrisch_XIX_Zone_VR <-> outer port SP_IF_STRG106a_Stopmodus_XIX_Zone_VR  # _XIX_ClimateControl_VR_XIX_Innenraumheizenelektrisch_XIX_Zone_VR_XIX_Klappen106aStellen_XIX_Innenraumheizenelektrisch_XIX_ACT_106a_XIX_STRG106a_Stopmodus
    delegate ClimateControl_VR_XIX_Innenraumheizenelektrisch_XIX_Zone_VR.SP_IF_STRG109a_Adresse_XIX_ClimateControl_VR_XIX_Innenraumheizenelektrisch_XIX_Zone_VR <-> outer port SP_IF_STRG109a_Adresse_XIX_Zone_VR  # _XIX_ClimateControl_VR_XIX_Innenraumheizenelektrisch_XIX_Zone_VR_XIX_Klappen109aStellen_XIX_Innenraumheizenelektrisch_XIX_ACT_109a_XIX_STRG109a_Adresse
    delegate ClimateControl_VR_XIX_Innenraumheizenelektrisch_XIX_Zone_VR.SP_IF_STRG109a_Clear_Event_Flags_XIX_ClimateControl_VR_XIX_Innenraumheizenelektrisch_XIX_Zone_VR <-> outer port SP_IF_STRG109a_Clear_Event_Flags_XIX_Zone_VR  # _XIX_ClimateControl_VR_XIX_Innenraumheizenelektrisch_XIX_Zone_VR_XIX_Klappen109aStellen_XIX_Innenraumheizenelektrisch_XIX_ACT_109a_XIX_STRG109a_Clear_Event_Flags
    delegate ClimateControl_VR_XIX_Innenraumheizenelektrisch_XIX_Zone_VR.SP_IF_STRG109a_Drehrichtung_XIX_ClimateControl_VR_XIX_Innenraumheizenelektrisch_XIX_Zone_VR <-> outer port SP_IF_STRG109a_Drehrichtung_XIX_Zone_VR  # _XIX_ClimateControl_VR_XIX_Innenraumheizenelektrisch_XIX_Zone_VR_XIX_Klappen109aStellen_XIX_Innenraumheizenelektrisch_XIX_ACT_109a_XIX_STRG109a_Drehrichtung
    delegate ClimateControl_VR_XIX_Innenraumheizenelektrisch_XIX_Zone_VR.SP_IF_STRG109a_Freig_Blockiererkennung_XIX_ClimateControl_VR_XIX_Innenraumheizenelektrisch_XIX_Zone_VR <-> outer port SP_IF_STRG109a_Freig_Blockiererkennung_XIX_Zone_VR  # _XIX_ClimateControl_VR_XIX_Innenraumheizenelektrisch_XIX_Zone_VR_XIX_Klappen109aStellen_XIX_Innenraumheizenelektrisch_XIX_ACT_109a_XIX_STRG109a_Freig_Blockiererkennung
    delegate ClimateControl_VR_XIX_Innenraumheizenelektrisch_XIX_Zone_VR.SP_IF_STRG109a_Geschwindigkeitsvorgabe_XIX_ClimateControl_VR_XIX_Innenraumheizenelektrisch_XIX_Zone_VR <-> outer port SP_IF_STRG109a_Geschwindigkeitsvorgabe_XIX_Zone_VR  # _XIX_ClimateControl_VR_XIX_Innenraumheizenelektrisch_XIX_Zone_VR_XIX_Klappen109aStellen_XIX_Innenraumheizenelektrisch_XIX_ACT_109a_XIX_STRG109a_Geschwindigkeitsvorgabe
    delegate ClimateControl_VR_XIX_Innenraumheizenelektrisch_XIX_Zone_VR.SP_IF_STRG109a_Notlauffreigabe_XIX_ClimateControl_VR_XIX_Innenraumheizenelektrisch_XIX_Zone_VR <-> outer port SP_IF_STRG109a_Notlauffreigabe_XIX_Zone_VR  # _XIX_ClimateControl_VR_XIX_Innenraumheizenelektrisch_XIX_Zone_VR_XIX_Klappen109aStellen_XIX_Innenraumheizenelektrisch_XIX_ACT_109a_XIX_STRG109a_Notlauffreigabe
    delegate ClimateControl_VR_XIX_Innenraumheizenelektrisch_XIX_Zone_VR.SP_IF_STRG109a_Notlaufposition_XIX_ClimateControl_VR_XIX_Innenraumheizenelektrisch_XIX_Zone_VR <-> outer port SP_IF_STRG109a_Notlaufposition_XIX_Zone_VR  # _XIX_ClimateControl_VR_XIX_Innenraumheizenelektrisch_XIX_Zone_VR_XIX_Klappen109aStellen_XIX_Innenraumheizenelektrisch_XIX_ACT_109a_XIX_STRG109a_Notlaufposition
    delegate ClimateControl_VR_XIX_Innenraumheizenelektrisch_XIX_Zone_VR.SP_IF_STRG109a_PrgDaten_speichern_XIX_ClimateControl_VR_XIX_Innenraumheizenelektrisch_XIX_Zone_VR <-> outer port SP_IF_STRG109a_PrgDaten_speichern_XIX_Zone_VR  # _XIX_ClimateControl_VR_XIX_Innenraumheizenelektrisch_XIX_Zone_VR_XIX_Klappen109aStellen_XIX_Innenraumheizenelektrisch_XIX_ACT_109a_XIX_STRG109a_PrgDaten_speichern
    delegate ClimateControl_VR_XIX_Innenraumheizenelektrisch_XIX_Zone_VR.SP_IF_STRG109a_Select_Positionsvorgabe_XIX_ClimateControl_VR_XIX_Innenraumheizenelektrisch_XIX_Zone_VR <-> outer port SP_IF_STRG109a_Select_Positionsvorgabe_XIX_Zone_VR  # _XIX_ClimateControl_VR_XIX_Innenraumheizenelektrisch_XIX_Zone_VR_XIX_Klappen109aStellen_XIX_Innenraumheizenelektrisch_XIX_ACT_109a_XIX_STRG109a_Select_Positionsvorgabe
    delegate ClimateControl_VR_XIX_Innenraumheizenelektrisch_XIX_Zone_VR.SP_IF_STRG109a_Soll_Position_XIX_ClimateControl_VR_XIX_Innenraumheizenelektrisch_XIX_Zone_VR <-> outer port SP_IF_STRG109a_Soll_Position_XIX_Zone_VR  # _XIX_ClimateControl_VR_XIX_Innenraumheizenelektrisch_XIX_Zone_VR_XIX_Klappen109aStellen_XIX_Innenraumheizenelektrisch_XIX_ACT_109a_XIX_STRG109a_Soll_Position
    delegate ClimateControl_VR_XIX_Innenraumheizenelektrisch_XIX_Zone_VR.SP_IF_STRG109a_Spulenhaltebestromung_XIX_ClimateControl_VR_XIX_Innenraumheizenelektrisch_XIX_Zone_VR <-> outer port SP_IF_STRG109a_Spulenhaltebestromung_XIX_Zone_VR  # _XIX_ClimateControl_VR_XIX_Innenraumheizenelektrisch_XIX_Zone_VR_XIX_Klappen109aStellen_XIX_Innenraumheizenelektrisch_XIX_ACT_109a_XIX_STRG109a_Spulenhaltebestromung
    delegate ClimateControl_VR_XIX_Innenraumheizenelektrisch_XIX_Zone_VR.SP_IF_STRG109a_Start_Position_XIX_ClimateControl_VR_XIX_Innenraumheizenelektrisch_XIX_Zone_VR <-> outer port SP_IF_STRG109a_Start_Position_XIX_Zone_VR  # _XIX_ClimateControl_VR_XIX_Innenraumheizenelektrisch_XIX_Zone_VR_XIX_Klappen109aStellen_XIX_Innenraumheizenelektrisch_XIX_ACT_109a_XIX_STRG109a_Start_Position
    delegate ClimateControl_VR_XIX_Innenraumheizenelektrisch_XIX_Zone_VR.SP_IF_STRG109a_Stopmodus_XIX_ClimateControl_VR_XIX_Innenraumheizenelektrisch_XIX_Zone_VR <-> outer port SP_IF_STRG109a_Stopmodus_XIX_Zone_VR  # _XIX_ClimateControl_VR_XIX_Innenraumheizenelektrisch_XIX_Zone_VR_XIX_Klappen109aStellen_XIX_Innenraumheizenelektrisch_XIX_ACT_109a_XIX_STRG109a_Stopmodus
    delegate ClimateControl_VR_XIX_Innenraumheizenelektrisch_XIX_Zone_VR.RP_IF_KL_DI_KL_58xs_XIX_ClimateControl_VR_XIX_Innenraumheizenelektrisch_XIX_Zone_VR <-> outer port RP_IF_KL_DI_KL_58xs_XIX_Zone_VR  # _XIX_ClimateControl_XIX_Innenraumheizenelektrisch_XIX_VCP_Body_XIX_ClimateControl_VR_XIX_Innenraumheizenelektrisch_XIX_Zone_VR_XIX_KL_DI_KL_58xs
    delegate ClimateControl_VR_XIX_Innenraumheizenelektrisch_XIX_Zone_VR.RP_IF_KL_DI_KL_58xd_XIX_ClimateControl_VR_XIX_Innenraumheizenelektrisch_XIX_Zone_VR <-> outer port RP_IF_KL_DI_KL_58xd_XIX_Zone_VR  # _XIX_ClimateControl_XIX_Innenraumheizenelektrisch_XIX_VCP_Body_XIX_ClimateControl_VR_XIX_Innenraumheizenelektrisch_XIX_Zone_VR_XIX_KL_DI_KL_58xd
    delegate ClimateControl_VR_XIX_Innenraumheizenelektrisch_XIX_Zone_VR.RP_IF_ClHmi_T_CurTempRearLe_S_XIX_ClimateControl_VR_XIX_Innenraumheizenelektrisch_XIX_Zone_VR <-> outer port RP_IF_ClHmi_T_CurTempRearLe_S_XIX_Zone_VR  # _XIX_ClimateControl_XIX_Innenraumheizenelektrisch_XIX_VCP_Body_XIX_ClimateControl_VR_XIX_Innenraumheizenelektrisch_XIX_Zone_VR_XIX_ClHmi_T_CurTempRearLe_S
    delegate ClimateControl_VR_XIX_Innenraumheizenelektrisch_XIX_Zone_VR.RP_IF_ClHmi_T_CurTempFrntLe_S_XIX_ClimateControl_VR_XIX_Innenraumheizenelektrisch_XIX_Zone_VR <-> outer port RP_IF_ClHmi_T_CurTempFrntLe_S_XIX_Zone_VR  # _XIX_ClimateControl_XIX_Innenraumheizenelektrisch_XIX_VCP_Body_XIX_ClimateControl_VR_XIX_Innenraumheizenelektrisch_XIX_Zone_VR_XIX_ClHmi_T_CurTempFrntLe_S
    delegate ClimateControl_VR_XIX_Innenraumheizenelektrisch_XIX_Zone_VR.RP_IF_ClActFan_perc_BlowerTarVal_S_XIX_ClimateControl_VR_XIX_Innenraumheizenelektrisch_XIX_Zone_VR <-> outer port RP_IF_ClActFan_perc_BlowerTarVal_S_XIX_Zone_VR  # _XIX_ClimateControl_XIX_Innenraumheizenelektrisch_XIX_VCP_Body_XIX_ClimateControl_VR_XIX_Innenraumheizenelektrisch_XIX_Zone_VR_XIX_ClActFan_perc_BlowerTarVal_S
    delegate ClimateControl_VR_XIX_Innenraumheizenelektrisch_XIX_Zone_VR.RP_IF_ClSens_SetBit1_S_XIX_ClimateControl_VR_XIX_Innenraumheizenelektrisch_XIX_Zone_VR <-> outer port RP_IF_ClSens_SetBit1_S_XIX_Zone_VR  # _XIX_ClimateControl_XIX_Innenraumheizenelektrisch_XIX_VCP_Body_XIX_ClimateControl_VR_XIX_Innenraumheizenelektrisch_XIX_Zone_VR_XIX_ClSens_SetBit1_S
    delegate ClimateControl_VR_XIX_Innenraumheizenelektrisch_XIX_Zone_VR.RP_IF_ClHmi_st_StDfrst_S_XIX_ClimateControl_VR_XIX_Innenraumheizenelektrisch_XIX_Zone_VR <-> outer port RP_IF_ClHmi_st_StDfrst_S_XIX_Zone_VR  # _XIX_ClimateControl_XIX_Innenraumheizenelektrisch_XIX_VCP_Body_XIX_ClimateControl_VR_XIX_Innenraumheizenelektrisch_XIX_Zone_VR_XIX_ClHmi_st_StDfrst_S
    delegate ClimateControl_VR_XIX_Innenraumheizenelektrisch_XIX_Zone_VR.RP_IF_ClSens_SetBit2_S_XIX_ClimateControl_VR_XIX_Innenraumheizenelektrisch_XIX_Zone_VR <-> outer port RP_IF_ClSens_SetBit2_S_XIX_Zone_VR  # _XIX_ClimateControl_XIX_Innenraumheizenelektrisch_XIX_VCP_Body_XIX_ClimateControl_VR_XIX_Innenraumheizenelektrisch_XIX_Zone_VR_XIX_ClSens_SetBit2_S
    delegate ClimateControl_VR_XIX_Innenraumheizenelektrisch_XIX_Zone_VR.RP_IF_ClHmi_T_CurTempRearRi_S_XIX_ClimateControl_VR_XIX_Innenraumheizenelektrisch_XIX_Zone_VR <-> outer port RP_IF_ClHmi_T_CurTempRearRi_S_XIX_Zone_VR  # _XIX_ClimateControl_XIX_Innenraumheizenelektrisch_XIX_VCP_Body_XIX_ClimateControl_VR_XIX_Innenraumheizenelektrisch_XIX_Zone_VR_XIX_ClHmi_T_CurTempRearRi_S
    delegate ClimateControl_VR_XIX_Innenraumheizenelektrisch_XIX_Zone_VR.RP_IF_ClAct_perc_FlapTFrntLeTarVal_XIX_ClimateControl_VR_XIX_Innenraumheizenelektrisch_XIX_Zone_VR <-> outer port RP_IF_ClAct_perc_FlapTFrntLeTarVal_XIX_Zone_VR  # _XIX_ClimateControl_XIX_Innenraumheizenelektrisch_XIX_VCP_Body_XIX_ClimateControl_VR_XIX_Innenraumheizenelektrisch_XIX_Zone_VR_XIX_ClAct_perc_FlapTFrntLeTarVal
    delegate ClimateControl_VR_XIX_Innenraumheizenelektrisch_XIX_Zone_VR.RP_IF_KL_KST_KL_15_XIX_ClimateControl_VR_XIX_Innenraumheizenelektrisch_XIX_Zone_VR <-> outer port RP_IF_KL_KST_KL_15_XIX_Zone_VR  # _XIX_ClimateControl_XIX_Innenraumheizenelektrisch_XIX_VCP_Body_XIX_ClimateControl_VR_XIX_Innenraumheizenelektrisch_XIX_Zone_VR_XIX_KL_KST_KL_15
    delegate ClimateControl_VR_XIX_Innenraumheizenelektrisch_XIX_Zone_VR.RP_IF_ClAct_perc_FlapTRearLeTarVal_XIX_ClimateControl_VR_XIX_Innenraumheizenelektrisch_XIX_Zone_VR <-> outer port RP_IF_ClAct_perc_FlapTRearLeTarVal_XIX_Zone_VR  # _XIX_ClimateControl_XIX_Innenraumheizenelektrisch_XIX_VCP_Body_XIX_ClimateControl_VR_XIX_Innenraumheizenelektrisch_XIX_Zone_VR_XIX_ClAct_perc_FlapTRearLeTarVal
    delegate ClimateControl_VR_XIX_Innenraumheizenelektrisch_XIX_Zone_VR.RP_IF_ClHmi_T_CurTempFrntRi_S_XIX_ClimateControl_VR_XIX_Innenraumheizenelektrisch_XIX_Zone_VR <-> outer port RP_IF_ClHmi_T_CurTempFrntRi_S_XIX_Zone_VR  # _XIX_ClimateControl_XIX_Innenraumheizenelektrisch_XIX_VCP_Body_XIX_ClimateControl_VR_XIX_Innenraumheizenelektrisch_XIX_Zone_VR_XIX_ClHmi_T_CurTempFrntRi_S
    delegate ClimateControl_VR_XIX_Innenraumheizenelektrisch_XIX_Zone_VR.RP_IF_ClAct_perc_FlapTFrntRiTarVal_XIX_ClimateControl_VR_XIX_Innenraumheizenelektrisch_XIX_Zone_VR <-> outer port RP_IF_ClAct_perc_FlapTFrntRiTarVal_XIX_Zone_VR  # _XIX_ClimateControl_XIX_Innenraumheizenelektrisch_XIX_VCP_Body_XIX_ClimateControl_VR_XIX_Innenraumheizenelektrisch_XIX_Zone_VR_XIX_ClAct_perc_FlapTFrntRiTarVal
    delegate ClimateControl_VR_XIX_Innenraumheizenelektrisch_XIX_Zone_VR.RP_IF_ClAct_perc_FlapTRearRiTarVal_XIX_ClimateControl_VR_XIX_Innenraumheizenelektrisch_XIX_Zone_VR <-> outer port RP_IF_ClAct_perc_FlapTRearRiTarVal_XIX_Zone_VR  # _XIX_ClimateControl_XIX_Innenraumheizenelektrisch_XIX_VCP_Body_XIX_ClimateControl_VR_XIX_Innenraumheizenelektrisch_XIX_Zone_VR_XIX_ClAct_perc_FlapTRearRiTarVal
    delegate ClimateControl_VR_XIX_Innenraumheizenelektrisch_XIX_Zone_VR.RP_IF_ClAct_perc_FlapDfrstTarVal_XIX_ClimateControl_VR_XIX_Innenraumheizenelektrisch_XIX_Zone_VR <-> outer port RP_IF_ClAct_perc_FlapDfrstTarVal_XIX_Zone_VR  # _XIX_ClimateControl_XIX_Innenraumheizenelektrisch_XIX_VCP_Body_XIX_ClimateControl_VR_XIX_Innenraumheizenelektrisch_XIX_Zone_VR_XIX_ClAct_perc_FlapDfrstTarVal
    delegate ClimateControl_VR_XIX_Innenraumheizenelektrisch_XIX_Zone_VR.RP_IF_BLOWER_DIAG_FLAG2_XIX_ClimateControl_VR_XIX_Innenraumheizenelektrisch_XIX_Zone_VR <-> outer port RP_IF_BLOWER_DIAG_FLAG2_XIX_Zone_VR  # _XIX_GeblaeseSteuerung_XIX_Innenraumheizenelektrisch_XIX_BLDC1_XIX_ClimateControl_VR_XIX_Innenraumheizenelektrisch_XIX_Zone_VR_XIX_BLOWER_DIAG_FLAG2
    delegate ClimateControl_VR_XIX_Innenraumheizenelektrisch_XIX_Zone_VR.RP_IF_BLOWER_UMOTOR_XIX_ClimateControl_VR_XIX_Innenraumheizenelektrisch_XIX_Zone_VR <-> outer port RP_IF_BLOWER_UMOTOR_XIX_Zone_VR  # _XIX_GeblaeseSteuerung_XIX_Innenraumheizenelektrisch_XIX_BLDC1_XIX_ClimateControl_VR_XIX_Innenraumheizenelektrisch_XIX_Zone_VR_XIX_BLOWER_UMOTOR
    delegate ClimateControl_VR_XIX_Innenraumheizenelektrisch_XIX_Zone_VR.RP_IF_BLOWER_TEMPERATURE_XIX_ClimateControl_VR_XIX_Innenraumheizenelektrisch_XIX_Zone_VR <-> outer port RP_IF_BLOWER_TEMPERATURE_XIX_Zone_VR  # _XIX_GeblaeseSteuerung_XIX_Innenraumheizenelektrisch_XIX_BLDC1_XIX_ClimateControl_VR_XIX_Innenraumheizenelektrisch_XIX_Zone_VR_XIX_BLOWER_TEMPERATURE
    delegate ClimateControl_VR_XIX_Innenraumheizenelektrisch_XIX_Zone_VR.RP_IF_BLOWER_ROTATION_SPEED_XIX_ClimateControl_VR_XIX_Innenraumheizenelektrisch_XIX_Zone_VR <-> outer port RP_IF_BLOWER_ROTATION_SPEED_XIX_Zone_VR  # _XIX_GeblaeseSteuerung_XIX_Innenraumheizenelektrisch_XIX_BLDC1_XIX_ClimateControl_VR_XIX_Innenraumheizenelektrisch_XIX_Zone_VR_XIX_BLOWER_ROTATION_SPEED
    delegate ClimateControl_VR_XIX_Innenraumheizenelektrisch_XIX_Zone_VR.RP_IF_BLOWER_STATUS_MOTOR_XIX_ClimateControl_VR_XIX_Innenraumheizenelektrisch_XIX_Zone_VR <-> outer port RP_IF_BLOWER_STATUS_MOTOR_XIX_Zone_VR  # _XIX_GeblaeseSteuerung_XIX_Innenraumheizenelektrisch_XIX_BLDC1_XIX_ClimateControl_VR_XIX_Innenraumheizenelektrisch_XIX_Zone_VR_XIX_BLOWER_STATUS_MOTOR
    delegate ClimateControl_VR_XIX_Innenraumheizenelektrisch_XIX_Zone_VR.RP_IF_BLOWER_UBATT_XIX_ClimateControl_VR_XIX_Innenraumheizenelektrisch_XIX_Zone_VR <-> outer port RP_IF_BLOWER_UBATT_XIX_Zone_VR  # _XIX_GeblaeseSteuerung_XIX_Innenraumheizenelektrisch_XIX_BLDC1_XIX_ClimateControl_VR_XIX_Innenraumheizenelektrisch_XIX_Zone_VR_XIX_BLOWER_UBATT
    delegate ClimateControl_VR_XIX_Innenraumheizenelektrisch_XIX_Zone_VR.RP_IF_BLOWER_DIAG_FLAG1_XIX_ClimateControl_VR_XIX_Innenraumheizenelektrisch_XIX_Zone_VR <-> outer port RP_IF_BLOWER_DIAG_FLAG1_XIX_Zone_VR  # _XIX_GeblaeseSteuerung_XIX_Innenraumheizenelektrisch_XIX_BLDC1_XIX_ClimateControl_VR_XIX_Innenraumheizenelektrisch_XIX_Zone_VR_XIX_BLOWER_DIAG_FLAG1
    delegate ClimateControl_VR_XIX_Innenraumheizenelektrisch_XIX_Zone_VR.RP_IF_BLOWER_TORQUE_XIX_ClimateControl_VR_XIX_Innenraumheizenelektrisch_XIX_Zone_VR <-> outer port RP_IF_BLOWER_TORQUE_XIX_Zone_VR  # _XIX_GeblaeseSteuerung_XIX_Innenraumheizenelektrisch_XIX_BLDC1_XIX_ClimateControl_VR_XIX_Innenraumheizenelektrisch_XIX_Zone_VR_XIX_BLOWER_TORQUE
    delegate ClimateControl_VR_XIX_Innenraumheizenelektrisch_XIX_Zone_VR.RP_IF_BLOWER_SUPPLIER_XIX_ClimateControl_VR_XIX_Innenraumheizenelektrisch_XIX_Zone_VR <-> outer port RP_IF_BLOWER_SUPPLIER_XIX_Zone_VR  # _XIX_GeblaeseSteuerung_XIX_Innenraumheizenelektrisch_XIX_BLDC1_XIX_ClimateControl_VR_XIX_Innenraumheizenelektrisch_XIX_Zone_VR_XIX_BLOWER_SUPPLIER
    delegate ClimateControl_VR_XIX_Innenraumheizenelektrisch_XIX_Zone_VR.RP_IF_BLOWER_IBATT_XIX_ClimateControl_VR_XIX_Innenraumheizenelektrisch_XIX_Zone_VR <-> outer port RP_IF_BLOWER_IBATT_XIX_Zone_VR  # _XIX_GeblaeseSteuerung_XIX_Innenraumheizenelektrisch_XIX_BLDC1_XIX_ClimateControl_VR_XIX_Innenraumheizenelektrisch_XIX_Zone_VR_XIX_BLOWER_IBATT
    delegate ClimateControl_VR_XIX_Innenraumheizenelektrisch_XIX_Zone_VR.RP_IF_ACT102f_Positionsvorgabe_Status_XIX_ClimateControl_VR_XIX_Innenraumheizenelektrisch_XIX_Zone_VR <-> outer port RP_IF_ACT102f_Positionsvorgabe_Status_XIX_Zone_VR  # _XIX_Klappen102fStellen_XIX_Innenraumheizenelektrisch_XIX_ACT_102f_XIX_ClimateControl_VR_XIX_Innenraumheizenelektrisch_XIX_Zone_VR_XIX_ACT102f_Positionsvorgabe_Status
    delegate ClimateControl_VR_XIX_Innenraumheizenelektrisch_XIX_Zone_VR.RP_IF_ACT102f_Adresse_Aktuator_XIX_ClimateControl_VR_XIX_Innenraumheizenelektrisch_XIX_Zone_VR <-> outer port RP_IF_ACT102f_Adresse_Aktuator_XIX_Zone_VR  # _XIX_Klappen102fStellen_XIX_Innenraumheizenelektrisch_XIX_ACT_102f_XIX_ClimateControl_VR_XIX_Innenraumheizenelektrisch_XIX_Zone_VR_XIX_ACT102f_Adresse_Aktuator
    delegate ClimateControl_VR_XIX_Innenraumheizenelektrisch_XIX_Zone_VR.RP_IF_ACT102f_Stopmodus_XIX_ClimateControl_VR_XIX_Innenraumheizenelektrisch_XIX_Zone_VR <-> outer port RP_IF_ACT102f_Stopmodus_XIX_Zone_VR  # _XIX_Klappen102fStellen_XIX_Innenraumheizenelektrisch_XIX_ACT_102f_XIX_ClimateControl_VR_XIX_Innenraumheizenelektrisch_XIX_Zone_VR_XIX_ACT102f_Stopmodus
    delegate ClimateControl_VR_XIX_Innenraumheizenelektrisch_XIX_Zone_VR.RP_IF_ACT102f_Sonderfunktionen_XIX_ClimateControl_VR_XIX_Innenraumheizenelektrisch_XIX_Zone_VR <-> outer port RP_IF_ACT102f_Sonderfunktionen_XIX_Zone_VR  # _XIX_Klappen102fStellen_XIX_Innenraumheizenelektrisch_XIX_ACT_102f_XIX_ClimateControl_VR_XIX_Innenraumheizenelektrisch_XIX_Zone_VR_XIX_ACT102f_Sonderfunktionen
    delegate ClimateControl_VR_XIX_Innenraumheizenelektrisch_XIX_Zone_VR.RP_IF_ACT102f_Variante_XIX_ClimateControl_VR_XIX_Innenraumheizenelektrisch_XIX_Zone_VR <-> outer port RP_IF_ACT102f_Variante_XIX_Zone_VR  # _XIX_Klappen102fStellen_XIX_Innenraumheizenelektrisch_XIX_ACT_102f_XIX_ClimateControl_VR_XIX_Innenraumheizenelektrisch_XIX_Zone_VR_XIX_ACT102f_Variante
    delegate ClimateControl_VR_XIX_Innenraumheizenelektrisch_XIX_Zone_VR.RP_IF_ACT102f_Versorgungsspannung_XIX_ClimateControl_VR_XIX_Innenraumheizenelektrisch_XIX_Zone_VR <-> outer port RP_IF_ACT102f_Versorgungsspannung_XIX_Zone_VR  # _XIX_Klappen102fStellen_XIX_Innenraumheizenelektrisch_XIX_ACT_102f_XIX_ClimateControl_VR_XIX_Innenraumheizenelektrisch_XIX_Zone_VR_XIX_ACT102f_Versorgungsspannung
    delegate ClimateControl_VR_XIX_Innenraumheizenelektrisch_XIX_Zone_VR.RP_IF_ACT102f_Selbsthaltemoment_XIX_ClimateControl_VR_XIX_Innenraumheizenelektrisch_XIX_Zone_VR <-> outer port RP_IF_ACT102f_Selbsthaltemoment_XIX_Zone_VR  # _XIX_Klappen102fStellen_XIX_Innenraumheizenelektrisch_XIX_ACT_102f_XIX_ClimateControl_VR_XIX_Innenraumheizenelektrisch_XIX_Zone_VR_XIX_ACT102f_Selbsthaltemoment
    delegate ClimateControl_VR_XIX_Innenraumheizenelektrisch_XIX_Zone_VR.RP_IF_ACT102f_Geschwindigkeitsstatus_XIX_ClimateControl_VR_XIX_Innenraumheizenelektrisch_XIX_Zone_VR <-> outer port RP_IF_ACT102f_Geschwindigkeitsstatus_XIX_Zone_VR  # _XIX_Klappen102fStellen_XIX_Innenraumheizenelektrisch_XIX_ACT_102f_XIX_ClimateControl_VR_XIX_Innenraumheizenelektrisch_XIX_Zone_VR_XIX_ACT102f_Geschwindigkeitsstatus
    delegate ClimateControl_VR_XIX_Innenraumheizenelektrisch_XIX_Zone_VR.RP_IF_ACT102f_Spulenbestromung_XIX_ClimateControl_VR_XIX_Innenraumheizenelektrisch_XIX_Zone_VR <-> outer port RP_IF_ACT102f_Spulenbestromung_XIX_Zone_VR  # _XIX_Klappen102fStellen_XIX_Innenraumheizenelektrisch_XIX_ACT_102f_XIX_ClimateControl_VR_XIX_Innenraumheizenelektrisch_XIX_Zone_VR_XIX_ACT102f_Spulenbestromung
    delegate ClimateControl_VR_XIX_Innenraumheizenelektrisch_XIX_Zone_VR.RP_IF_ACT102f_Ist_Position_Aktuator_XIX_ClimateControl_VR_XIX_Innenraumheizenelektrisch_XIX_Zone_VR <-> outer port RP_IF_ACT102f_Ist_Position_Aktuator_XIX_Zone_VR  # _XIX_Klappen102fStellen_XIX_Innenraumheizenelektrisch_XIX_ACT_102f_XIX_ClimateControl_VR_XIX_Innenraumheizenelektrisch_XIX_Zone_VR_XIX_ACT102f_Ist_Position_Aktuator
    delegate ClimateControl_VR_XIX_Innenraumheizenelektrisch_XIX_Zone_VR.RP_IF_ACT102f_Notlauffreigabe_XIX_ClimateControl_VR_XIX_Innenraumheizenelektrisch_XIX_Zone_VR <-> outer port RP_IF_ACT102f_Notlauffreigabe_XIX_Zone_VR  # _XIX_Klappen102fStellen_XIX_Innenraumheizenelektrisch_XIX_ACT_102f_XIX_ClimateControl_VR_XIX_Innenraumheizenelektrisch_XIX_Zone_VR_XIX_ACT102f_Notlauffreigabe
    delegate ClimateControl_VR_XIX_Innenraumheizenelektrisch_XIX_Zone_VR.RP_IF_ACT102f_Notlauf_aufgetreten_XIX_ClimateControl_VR_XIX_Innenraumheizenelektrisch_XIX_Zone_VR <-> outer port RP_IF_ACT102f_Notlauf_aufgetreten_XIX_Zone_VR  # _XIX_Klappen102fStellen_XIX_Innenraumheizenelektrisch_XIX_ACT_102f_XIX_ClimateControl_VR_XIX_Innenraumheizenelektrisch_XIX_Zone_VR_XIX_ACT102f_Notlauf_aufgetreten
    delegate ClimateControl_VR_XIX_Innenraumheizenelektrisch_XIX_Zone_VR.RP_IF_ACT102f_Blockierung_aufgetreten_XIX_ClimateControl_VR_XIX_Innenraumheizenelektrisch_XIX_Zone_VR <-> outer port RP_IF_ACT102f_Blockierung_aufgetreten_XIX_Zone_VR  # _XIX_Klappen102fStellen_XIX_Innenraumheizenelektrisch_XIX_ACT_102f_XIX_ClimateControl_VR_XIX_Innenraumheizenelektrisch_XIX_Zone_VR_XIX_ACT102f_Blockierung_aufgetreten
    delegate ClimateControl_VR_XIX_Innenraumheizenelektrisch_XIX_Zone_VR.RP_IF_ACT102f_el_Defekt_XIX_ClimateControl_VR_XIX_Innenraumheizenelektrisch_XIX_Zone_VR <-> outer port RP_IF_ACT102f_el_Defekt_XIX_Zone_VR  # _XIX_Klappen102fStellen_XIX_Innenraumheizenelektrisch_XIX_ACT_102f_XIX_ClimateControl_VR_XIX_Innenraumheizenelektrisch_XIX_Zone_VR_XIX_ACT102f_el_Defekt
    delegate ClimateControl_VR_XIX_Innenraumheizenelektrisch_XIX_Zone_VR.RP_IF_ACT102f_Notlaufposition_XIX_ClimateControl_VR_XIX_Innenraumheizenelektrisch_XIX_Zone_VR <-> outer port RP_IF_ACT102f_Notlaufposition_XIX_Zone_VR  # _XIX_Klappen102fStellen_XIX_Innenraumheizenelektrisch_XIX_ACT_102f_XIX_ClimateControl_VR_XIX_Innenraumheizenelektrisch_XIX_Zone_VR_XIX_ACT102f_Notlaufposition
    delegate ClimateControl_VR_XIX_Innenraumheizenelektrisch_XIX_Zone_VR.RP_IF_ACT102f_Verfahrrichtung_XIX_ClimateControl_VR_XIX_Innenraumheizenelektrisch_XIX_Zone_VR <-> outer port RP_IF_ACT102f_Verfahrrichtung_XIX_Zone_VR  # _XIX_Klappen102fStellen_XIX_Innenraumheizenelektrisch_XIX_ACT_102f_XIX_ClimateControl_VR_XIX_Innenraumheizenelektrisch_XIX_Zone_VR_XIX_ACT102f_Verfahrrichtung
    delegate ClimateControl_VR_XIX_Innenraumheizenelektrisch_XIX_Zone_VR.RP_IF_ACT102f_Uebertemperatur_XIX_ClimateControl_VR_XIX_Innenraumheizenelektrisch_XIX_Zone_VR <-> outer port RP_IF_ACT102f_Uebertemperatur_XIX_Zone_VR  # _XIX_Klappen102fStellen_XIX_Innenraumheizenelektrisch_XIX_ACT_102f_XIX_ClimateControl_VR_XIX_Innenraumheizenelektrisch_XIX_Zone_VR_XIX_ACT102f_Uebertemperatur
    delegate ClimateControl_VR_XIX_Innenraumheizenelektrisch_XIX_Zone_VR.RP_IF_ACT102f_Drehrichtung_XIX_ClimateControl_VR_XIX_Innenraumheizenelektrisch_XIX_Zone_VR <-> outer port RP_IF_ACT102f_Drehrichtung_XIX_Zone_VR  # _XIX_Klappen102fStellen_XIX_Innenraumheizenelektrisch_XIX_ACT_102f_XIX_ClimateControl_VR_XIX_Innenraumheizenelektrisch_XIX_Zone_VR_XIX_ACT102f_Drehrichtung
    delegate ClimateControl_VR_XIX_Innenraumheizenelektrisch_XIX_Zone_VR.RP_IF_ACT102f_Reset_XIX_ClimateControl_VR_XIX_Innenraumheizenelektrisch_XIX_Zone_VR <-> outer port RP_IF_ACT102f_Reset_XIX_Zone_VR  # _XIX_Klappen102fStellen_XIX_Innenraumheizenelektrisch_XIX_ACT_102f_XIX_ClimateControl_VR_XIX_Innenraumheizenelektrisch_XIX_Zone_VR_XIX_ACT102f_Reset
    delegate ClimateControl_VR_XIX_Innenraumheizenelektrisch_XIX_Zone_VR.RP_IF_ACT104a_Spulenbestromung_XIX_ClimateControl_VR_XIX_Innenraumheizenelektrisch_XIX_Zone_VR <-> outer port RP_IF_ACT104a_Spulenbestromung_XIX_Zone_VR  # _XIX_Klappen104aStellen_XIX_Innenraumheizenelektrisch_XIX_ACT_104a_XIX_ClimateControl_VR_XIX_Innenraumheizenelektrisch_XIX_Zone_VR_XIX_ACT104a_Spulenbestromung
    delegate ClimateControl_VR_XIX_Innenraumheizenelektrisch_XIX_Zone_VR.RP_IF_ACT104a_Blockierung_aufgetreten_XIX_ClimateControl_VR_XIX_Innenraumheizenelektrisch_XIX_Zone_VR <-> outer port RP_IF_ACT104a_Blockierung_aufgetreten_XIX_Zone_VR  # _XIX_Klappen104aStellen_XIX_Innenraumheizenelektrisch_XIX_ACT_104a_XIX_ClimateControl_VR_XIX_Innenraumheizenelektrisch_XIX_Zone_VR_XIX_ACT104a_Blockierung_aufgetreten
    delegate ClimateControl_VR_XIX_Innenraumheizenelektrisch_XIX_Zone_VR.RP_IF_ACT104a_Positionsvorgabe_Status_XIX_ClimateControl_VR_XIX_Innenraumheizenelektrisch_XIX_Zone_VR <-> outer port RP_IF_ACT104a_Positionsvorgabe_Status_XIX_Zone_VR  # _XIX_Klappen104aStellen_XIX_Innenraumheizenelektrisch_XIX_ACT_104a_XIX_ClimateControl_VR_XIX_Innenraumheizenelektrisch_XIX_Zone_VR_XIX_ACT104a_Positionsvorgabe_Status
    delegate ClimateControl_VR_XIX_Innenraumheizenelektrisch_XIX_Zone_VR.RP_IF_ACT104a_Adresse_Aktuator_XIX_ClimateControl_VR_XIX_Innenraumheizenelektrisch_XIX_Zone_VR <-> outer port RP_IF_ACT104a_Adresse_Aktuator_XIX_Zone_VR  # _XIX_Klappen104aStellen_XIX_Innenraumheizenelektrisch_XIX_ACT_104a_XIX_ClimateControl_VR_XIX_Innenraumheizenelektrisch_XIX_Zone_VR_XIX_ACT104a_Adresse_Aktuator
    delegate ClimateControl_VR_XIX_Innenraumheizenelektrisch_XIX_Zone_VR.RP_IF_ACT104a_el_Defekt_XIX_ClimateControl_VR_XIX_Innenraumheizenelektrisch_XIX_Zone_VR <-> outer port RP_IF_ACT104a_el_Defekt_XIX_Zone_VR  # _XIX_Klappen104aStellen_XIX_Innenraumheizenelektrisch_XIX_ACT_104a_XIX_ClimateControl_VR_XIX_Innenraumheizenelektrisch_XIX_Zone_VR_XIX_ACT104a_el_Defekt
    delegate ClimateControl_VR_XIX_Innenraumheizenelektrisch_XIX_Zone_VR.RP_IF_ACT104a_Notlaufposition_XIX_ClimateControl_VR_XIX_Innenraumheizenelektrisch_XIX_Zone_VR <-> outer port RP_IF_ACT104a_Notlaufposition_XIX_Zone_VR  # _XIX_Klappen104aStellen_XIX_Innenraumheizenelektrisch_XIX_ACT_104a_XIX_ClimateControl_VR_XIX_Innenraumheizenelektrisch_XIX_Zone_VR_XIX_ACT104a_Notlaufposition
    delegate ClimateControl_VR_XIX_Innenraumheizenelektrisch_XIX_Zone_VR.RP_IF_ACT104a_Reset_XIX_ClimateControl_VR_XIX_Innenraumheizenelektrisch_XIX_Zone_VR <-> outer port RP_IF_ACT104a_Reset_XIX_Zone_VR  # _XIX_Klappen104aStellen_XIX_Innenraumheizenelektrisch_XIX_ACT_104a_XIX_ClimateControl_VR_XIX_Innenraumheizenelektrisch_XIX_Zone_VR_XIX_ACT104a_Reset
    delegate ClimateControl_VR_XIX_Innenraumheizenelektrisch_XIX_Zone_VR.RP_IF_ACT104a_Verfahrrichtung_XIX_ClimateControl_VR_XIX_Innenraumheizenelektrisch_XIX_Zone_VR <-> outer port RP_IF_ACT104a_Verfahrrichtung_XIX_Zone_VR  # _XIX_Klappen104aStellen_XIX_Innenraumheizenelektrisch_XIX_ACT_104a_XIX_ClimateControl_VR_XIX_Innenraumheizenelektrisch_XIX_Zone_VR_XIX_ACT104a_Verfahrrichtung
    delegate ClimateControl_VR_XIX_Innenraumheizenelektrisch_XIX_Zone_VR.RP_IF_ACT104a_Selbsthaltemoment_XIX_ClimateControl_VR_XIX_Innenraumheizenelektrisch_XIX_Zone_VR <-> outer port RP_IF_ACT104a_Selbsthaltemoment_XIX_Zone_VR  # _XIX_Klappen104aStellen_XIX_Innenraumheizenelektrisch_XIX_ACT_104a_XIX_ClimateControl_VR_XIX_Innenraumheizenelektrisch_XIX_Zone_VR_XIX_ACT104a_Selbsthaltemoment
    delegate ClimateControl_VR_XIX_Innenraumheizenelektrisch_XIX_Zone_VR.RP_IF_ACT104a_Uebertemperatur_XIX_ClimateControl_VR_XIX_Innenraumheizenelektrisch_XIX_Zone_VR <-> outer port RP_IF_ACT104a_Uebertemperatur_XIX_Zone_VR  # _XIX_Klappen104aStellen_XIX_Innenraumheizenelektrisch_XIX_ACT_104a_XIX_ClimateControl_VR_XIX_Innenraumheizenelektrisch_XIX_Zone_VR_XIX_ACT104a_Uebertemperatur
    delegate ClimateControl_VR_XIX_Innenraumheizenelektrisch_XIX_Zone_VR.RP_IF_ACT104a_Sonderfunktionen_XIX_ClimateControl_VR_XIX_Innenraumheizenelektrisch_XIX_Zone_VR <-> outer port RP_IF_ACT104a_Sonderfunktionen_XIX_Zone_VR  # _XIX_Klappen104aStellen_XIX_Innenraumheizenelektrisch_XIX_ACT_104a_XIX_ClimateControl_VR_XIX_Innenraumheizenelektrisch_XIX_Zone_VR_XIX_ACT104a_Sonderfunktionen
    delegate ClimateControl_VR_XIX_Innenraumheizenelektrisch_XIX_Zone_VR.RP_IF_ACT104a_Notlauffreigabe_XIX_ClimateControl_VR_XIX_Innenraumheizenelektrisch_XIX_Zone_VR <-> outer port RP_IF_ACT104a_Notlauffreigabe_XIX_Zone_VR  # _XIX_Klappen104aStellen_XIX_Innenraumheizenelektrisch_XIX_ACT_104a_XIX_ClimateControl_VR_XIX_Innenraumheizenelektrisch_XIX_Zone_VR_XIX_ACT104a_Notlauffreigabe
    delegate ClimateControl_VR_XIX_Innenraumheizenelektrisch_XIX_Zone_VR.RP_IF_ACT104a_Notlauf_aufgetreten_XIX_ClimateControl_VR_XIX_Innenraumheizenelektrisch_XIX_Zone_VR <-> outer port RP_IF_ACT104a_Notlauf_aufgetreten_XIX_Zone_VR  # _XIX_Klappen104aStellen_XIX_Innenraumheizenelektrisch_XIX_ACT_104a_XIX_ClimateControl_VR_XIX_Innenraumheizenelektrisch_XIX_Zone_VR_XIX_ACT104a_Notlauf_aufgetreten
    delegate ClimateControl_VR_XIX_Innenraumheizenelektrisch_XIX_Zone_VR.RP_IF_ACT104a_Drehrichtung_XIX_ClimateControl_VR_XIX_Innenraumheizenelektrisch_XIX_Zone_VR <-> outer port RP_IF_ACT104a_Drehrichtung_XIX_Zone_VR  # _XIX_Klappen104aStellen_XIX_Innenraumheizenelektrisch_XIX_ACT_104a_XIX_ClimateControl_VR_XIX_Innenraumheizenelektrisch_XIX_Zone_VR_XIX_ACT104a_Drehrichtung
    delegate ClimateControl_VR_XIX_Innenraumheizenelektrisch_XIX_Zone_VR.RP_IF_ACT104a_Stopmodus_XIX_ClimateControl_VR_XIX_Innenraumheizenelektrisch_XIX_Zone_VR <-> outer port RP_IF_ACT104a_Stopmodus_XIX_Zone_VR  # _XIX_Klappen104aStellen_XIX_Innenraumheizenelektrisch_XIX_ACT_104a_XIX_ClimateControl_VR_XIX_Innenraumheizenelektrisch_XIX_Zone_VR_XIX_ACT104a_Stopmodus
    delegate ClimateControl_VR_XIX_Innenraumheizenelektrisch_XIX_Zone_VR.RP_IF_ACT104a_Ist_Position_Aktuator_XIX_ClimateControl_VR_XIX_Innenraumheizenelektrisch_XIX_Zone_VR <-> outer port RP_IF_ACT104a_Ist_Position_Aktuator_XIX_Zone_VR  # _XIX_Klappen104aStellen_XIX_Innenraumheizenelektrisch_XIX_ACT_104a_XIX_ClimateControl_VR_XIX_Innenraumheizenelektrisch_XIX_Zone_VR_XIX_ACT104a_Ist_Position_Aktuator
    delegate ClimateControl_VR_XIX_Innenraumheizenelektrisch_XIX_Zone_VR.RP_IF_ACT104a_Variante_XIX_ClimateControl_VR_XIX_Innenraumheizenelektrisch_XIX_Zone_VR <-> outer port RP_IF_ACT104a_Variante_XIX_Zone_VR  # _XIX_Klappen104aStellen_XIX_Innenraumheizenelektrisch_XIX_ACT_104a_XIX_ClimateControl_VR_XIX_Innenraumheizenelektrisch_XIX_Zone_VR_XIX_ACT104a_Variante
    delegate ClimateControl_VR_XIX_Innenraumheizenelektrisch_XIX_Zone_VR.RP_IF_ACT104a_Geschwindigkeitsstatus_XIX_ClimateControl_VR_XIX_Innenraumheizenelektrisch_XIX_Zone_VR <-> outer port RP_IF_ACT104a_Geschwindigkeitsstatus_XIX_Zone_VR  # _XIX_Klappen104aStellen_XIX_Innenraumheizenelektrisch_XIX_ACT_104a_XIX_ClimateControl_VR_XIX_Innenraumheizenelektrisch_XIX_Zone_VR_XIX_ACT104a_Geschwindigkeitsstatus
    delegate ClimateControl_VR_XIX_Innenraumheizenelektrisch_XIX_Zone_VR.RP_IF_ACT104a_Versorgungsspannung_XIX_ClimateControl_VR_XIX_Innenraumheizenelektrisch_XIX_Zone_VR <-> outer port RP_IF_ACT104a_Versorgungsspannung_XIX_Zone_VR  # _XIX_Klappen104aStellen_XIX_Innenraumheizenelektrisch_XIX_ACT_104a_XIX_ClimateControl_VR_XIX_Innenraumheizenelektrisch_XIX_Zone_VR_XIX_ACT104a_Versorgungsspannung
    delegate ClimateControl_VR_XIX_Innenraumheizenelektrisch_XIX_Zone_VR.RP_IF_ACT105a_Ist_Position_Aktuator_XIX_ClimateControl_VR_XIX_Innenraumheizenelektrisch_XIX_Zone_VR <-> outer port RP_IF_ACT105a_Ist_Position_Aktuator_XIX_Zone_VR  # _XIX_Klappen105aStellen_XIX_Innenraumheizenelektrisch_XIX_ACT_105a_XIX_ClimateControl_VR_XIX_Innenraumheizenelektrisch_XIX_Zone_VR_XIX_ACT105a_Ist_Position_Aktuator
    delegate ClimateControl_VR_XIX_Innenraumheizenelektrisch_XIX_Zone_VR.RP_IF_ACT105a_Notlauf_aufgetreten_XIX_ClimateControl_VR_XIX_Innenraumheizenelektrisch_XIX_Zone_VR <-> outer port RP_IF_ACT105a_Notlauf_aufgetreten_XIX_Zone_VR  # _XIX_Klappen105aStellen_XIX_Innenraumheizenelektrisch_XIX_ACT_105a_XIX_ClimateControl_VR_XIX_Innenraumheizenelektrisch_XIX_Zone_VR_XIX_ACT105a_Notlauf_aufgetreten
    delegate ClimateControl_VR_XIX_Innenraumheizenelektrisch_XIX_Zone_VR.RP_IF_ACT105a_Versorgungsspannung_XIX_ClimateControl_VR_XIX_Innenraumheizenelektrisch_XIX_Zone_VR <-> outer port RP_IF_ACT105a_Versorgungsspannung_XIX_Zone_VR  # _XIX_Klappen105aStellen_XIX_Innenraumheizenelektrisch_XIX_ACT_105a_XIX_ClimateControl_VR_XIX_Innenraumheizenelektrisch_XIX_Zone_VR_XIX_ACT105a_Versorgungsspannung
    delegate ClimateControl_VR_XIX_Innenraumheizenelektrisch_XIX_Zone_VR.RP_IF_ACT105a_Notlaufposition_XIX_ClimateControl_VR_XIX_Innenraumheizenelektrisch_XIX_Zone_VR <-> outer port RP_IF_ACT105a_Notlaufposition_XIX_Zone_VR  # _XIX_Klappen105aStellen_XIX_Innenraumheizenelektrisch_XIX_ACT_105a_XIX_ClimateControl_VR_XIX_Innenraumheizenelektrisch_XIX_Zone_VR_XIX_ACT105a_Notlaufposition
    delegate ClimateControl_VR_XIX_Innenraumheizenelektrisch_XIX_Zone_VR.RP_IF_ACT105a_Drehrichtung_XIX_ClimateControl_VR_XIX_Innenraumheizenelektrisch_XIX_Zone_VR <-> outer port RP_IF_ACT105a_Drehrichtung_XIX_Zone_VR  # _XIX_Klappen105aStellen_XIX_Innenraumheizenelektrisch_XIX_ACT_105a_XIX_ClimateControl_VR_XIX_Innenraumheizenelektrisch_XIX_Zone_VR_XIX_ACT105a_Drehrichtung
    delegate ClimateControl_VR_XIX_Innenraumheizenelektrisch_XIX_Zone_VR.RP_IF_ACT105a_Positionsvorgabe_Status_XIX_ClimateControl_VR_XIX_Innenraumheizenelektrisch_XIX_Zone_VR <-> outer port RP_IF_ACT105a_Positionsvorgabe_Status_XIX_Zone_VR  # _XIX_Klappen105aStellen_XIX_Innenraumheizenelektrisch_XIX_ACT_105a_XIX_ClimateControl_VR_XIX_Innenraumheizenelektrisch_XIX_Zone_VR_XIX_ACT105a_Positionsvorgabe_Status
    delegate ClimateControl_VR_XIX_Innenraumheizenelektrisch_XIX_Zone_VR.RP_IF_ACT105a_Variante_XIX_ClimateControl_VR_XIX_Innenraumheizenelektrisch_XIX_Zone_VR <-> outer port RP_IF_ACT105a_Variante_XIX_Zone_VR  # _XIX_Klappen105aStellen_XIX_Innenraumheizenelektrisch_XIX_ACT_105a_XIX_ClimateControl_VR_XIX_Innenraumheizenelektrisch_XIX_Zone_VR_XIX_ACT105a_Variante
    delegate ClimateControl_VR_XIX_Innenraumheizenelektrisch_XIX_Zone_VR.RP_IF_ACT105a_Uebertemperatur_XIX_ClimateControl_VR_XIX_Innenraumheizenelektrisch_XIX_Zone_VR <-> outer port RP_IF_ACT105a_Uebertemperatur_XIX_Zone_VR  # _XIX_Klappen105aStellen_XIX_Innenraumheizenelektrisch_XIX_ACT_105a_XIX_ClimateControl_VR_XIX_Innenraumheizenelektrisch_XIX_Zone_VR_XIX_ACT105a_Uebertemperatur
    delegate ClimateControl_VR_XIX_Innenraumheizenelektrisch_XIX_Zone_VR.RP_IF_ACT105a_Reset_XIX_ClimateControl_VR_XIX_Innenraumheizenelektrisch_XIX_Zone_VR <-> outer port RP_IF_ACT105a_Reset_XIX_Zone_VR  # _XIX_Klappen105aStellen_XIX_Innenraumheizenelektrisch_XIX_ACT_105a_XIX_ClimateControl_VR_XIX_Innenraumheizenelektrisch_XIX_Zone_VR_XIX_ACT105a_Reset
    delegate ClimateControl_VR_XIX_Innenraumheizenelektrisch_XIX_Zone_VR.RP_IF_ACT105a_Selbsthaltemoment_XIX_ClimateControl_VR_XIX_Innenraumheizenelektrisch_XIX_Zone_VR <-> outer port RP_IF_ACT105a_Selbsthaltemoment_XIX_Zone_VR  # _XIX_Klappen105aStellen_XIX_Innenraumheizenelektrisch_XIX_ACT_105a_XIX_ClimateControl_VR_XIX_Innenraumheizenelektrisch_XIX_Zone_VR_XIX_ACT105a_Selbsthaltemoment
    delegate ClimateControl_VR_XIX_Innenraumheizenelektrisch_XIX_Zone_VR.RP_IF_ACT105a_Geschwindigkeitsstatus_XIX_ClimateControl_VR_XIX_Innenraumheizenelektrisch_XIX_Zone_VR <-> outer port RP_IF_ACT105a_Geschwindigkeitsstatus_XIX_Zone_VR  # _XIX_Klappen105aStellen_XIX_Innenraumheizenelektrisch_XIX_ACT_105a_XIX_ClimateControl_VR_XIX_Innenraumheizenelektrisch_XIX_Zone_VR_XIX_ACT105a_Geschwindigkeitsstatus
    delegate ClimateControl_VR_XIX_Innenraumheizenelektrisch_XIX_Zone_VR.RP_IF_ACT105a_Verfahrrichtung_XIX_ClimateControl_VR_XIX_Innenraumheizenelektrisch_XIX_Zone_VR <-> outer port RP_IF_ACT105a_Verfahrrichtung_XIX_Zone_VR  # _XIX_Klappen105aStellen_XIX_Innenraumheizenelektrisch_XIX_ACT_105a_XIX_ClimateControl_VR_XIX_Innenraumheizenelektrisch_XIX_Zone_VR_XIX_ACT105a_Verfahrrichtung
    delegate ClimateControl_VR_XIX_Innenraumheizenelektrisch_XIX_Zone_VR.RP_IF_ACT105a_el_Defekt_XIX_ClimateControl_VR_XIX_Innenraumheizenelektrisch_XIX_Zone_VR <-> outer port RP_IF_ACT105a_el_Defekt_XIX_Zone_VR  # _XIX_Klappen105aStellen_XIX_Innenraumheizenelektrisch_XIX_ACT_105a_XIX_ClimateControl_VR_XIX_Innenraumheizenelektrisch_XIX_Zone_VR_XIX_ACT105a_el_Defekt
    delegate ClimateControl_VR_XIX_Innenraumheizenelektrisch_XIX_Zone_VR.RP_IF_ACT105a_Notlauffreigabe_XIX_ClimateControl_VR_XIX_Innenraumheizenelektrisch_XIX_Zone_VR <-> outer port RP_IF_ACT105a_Notlauffreigabe_XIX_Zone_VR  # _XIX_Klappen105aStellen_XIX_Innenraumheizenelektrisch_XIX_ACT_105a_XIX_ClimateControl_VR_XIX_Innenraumheizenelektrisch_XIX_Zone_VR_XIX_ACT105a_Notlauffreigabe
    delegate ClimateControl_VR_XIX_Innenraumheizenelektrisch_XIX_Zone_VR.RP_IF_ACT105a_Blockierung_aufgetreten_XIX_ClimateControl_VR_XIX_Innenraumheizenelektrisch_XIX_Zone_VR <-> outer port RP_IF_ACT105a_Blockierung_aufgetreten_XIX_Zone_VR  # _XIX_Klappen105aStellen_XIX_Innenraumheizenelektrisch_XIX_ACT_105a_XIX_ClimateControl_VR_XIX_Innenraumheizenelektrisch_XIX_Zone_VR_XIX_ACT105a_Blockierung_aufgetreten
    delegate ClimateControl_VR_XIX_Innenraumheizenelektrisch_XIX_Zone_VR.RP_IF_ACT105a_Adresse_Aktuator_XIX_ClimateControl_VR_XIX_Innenraumheizenelektrisch_XIX_Zone_VR <-> outer port RP_IF_ACT105a_Adresse_Aktuator_XIX_Zone_VR  # _XIX_Klappen105aStellen_XIX_Innenraumheizenelektrisch_XIX_ACT_105a_XIX_ClimateControl_VR_XIX_Innenraumheizenelektrisch_XIX_Zone_VR_XIX_ACT105a_Adresse_Aktuator
    delegate ClimateControl_VR_XIX_Innenraumheizenelektrisch_XIX_Zone_VR.RP_IF_ACT105a_Spulenbestromung_XIX_ClimateControl_VR_XIX_Innenraumheizenelektrisch_XIX_Zone_VR <-> outer port RP_IF_ACT105a_Spulenbestromung_XIX_Zone_VR  # _XIX_Klappen105aStellen_XIX_Innenraumheizenelektrisch_XIX_ACT_105a_XIX_ClimateControl_VR_XIX_Innenraumheizenelektrisch_XIX_Zone_VR_XIX_ACT105a_Spulenbestromung
    delegate ClimateControl_VR_XIX_Innenraumheizenelektrisch_XIX_Zone_VR.RP_IF_ACT105a_Sonderfunktionen_XIX_ClimateControl_VR_XIX_Innenraumheizenelektrisch_XIX_Zone_VR <-> outer port RP_IF_ACT105a_Sonderfunktionen_XIX_Zone_VR  # _XIX_Klappen105aStellen_XIX_Innenraumheizenelektrisch_XIX_ACT_105a_XIX_ClimateControl_VR_XIX_Innenraumheizenelektrisch_XIX_Zone_VR_XIX_ACT105a_Sonderfunktionen
    delegate ClimateControl_VR_XIX_Innenraumheizenelektrisch_XIX_Zone_VR.RP_IF_ACT105a_Stopmodus_XIX_ClimateControl_VR_XIX_Innenraumheizenelektrisch_XIX_Zone_VR <-> outer port RP_IF_ACT105a_Stopmodus_XIX_Zone_VR  # _XIX_Klappen105aStellen_XIX_Innenraumheizenelektrisch_XIX_ACT_105a_XIX_ClimateControl_VR_XIX_Innenraumheizenelektrisch_XIX_Zone_VR_XIX_ACT105a_Stopmodus
    delegate ClimateControl_VR_XIX_Innenraumheizenelektrisch_XIX_Zone_VR.RP_IF_ACT106a_Positionsvorgabe_Status_XIX_ClimateControl_VR_XIX_Innenraumheizenelektrisch_XIX_Zone_VR <-> outer port RP_IF_ACT106a_Positionsvorgabe_Status_XIX_Zone_VR  # _XIX_Klappen106aStellen_XIX_Innenraumheizenelektrisch_XIX_ACT_106a_XIX_ClimateControl_VR_XIX_Innenraumheizenelektrisch_XIX_Zone_VR_XIX_ACT106a_Positionsvorgabe_Status
    delegate ClimateControl_VR_XIX_Innenraumheizenelektrisch_XIX_Zone_VR.RP_IF_ACT106a_Ist_Position_Aktuator_XIX_ClimateControl_VR_XIX_Innenraumheizenelektrisch_XIX_Zone_VR <-> outer port RP_IF_ACT106a_Ist_Position_Aktuator_XIX_Zone_VR  # _XIX_Klappen106aStellen_XIX_Innenraumheizenelektrisch_XIX_ACT_106a_XIX_ClimateControl_VR_XIX_Innenraumheizenelektrisch_XIX_Zone_VR_XIX_ACT106a_Ist_Position_Aktuator
    delegate ClimateControl_VR_XIX_Innenraumheizenelektrisch_XIX_Zone_VR.RP_IF_ACT106a_Geschwindigkeitsstatus_XIX_ClimateControl_VR_XIX_Innenraumheizenelektrisch_XIX_Zone_VR <-> outer port RP_IF_ACT106a_Geschwindigkeitsstatus_XIX_Zone_VR  # _XIX_Klappen106aStellen_XIX_Innenraumheizenelektrisch_XIX_ACT_106a_XIX_ClimateControl_VR_XIX_Innenraumheizenelektrisch_XIX_Zone_VR_XIX_ACT106a_Geschwindigkeitsstatus
    delegate ClimateControl_VR_XIX_Innenraumheizenelektrisch_XIX_Zone_VR.RP_IF_ACT106a_Versorgungsspannung_XIX_ClimateControl_VR_XIX_Innenraumheizenelektrisch_XIX_Zone_VR <-> outer port RP_IF_ACT106a_Versorgungsspannung_XIX_Zone_VR  # _XIX_Klappen106aStellen_XIX_Innenraumheizenelektrisch_XIX_ACT_106a_XIX_ClimateControl_VR_XIX_Innenraumheizenelektrisch_XIX_Zone_VR_XIX_ACT106a_Versorgungsspannung
    delegate ClimateControl_VR_XIX_Innenraumheizenelektrisch_XIX_Zone_VR.RP_IF_ACT106a_Uebertemperatur_XIX_ClimateControl_VR_XIX_Innenraumheizenelektrisch_XIX_Zone_VR <-> outer port RP_IF_ACT106a_Uebertemperatur_XIX_Zone_VR  # _XIX_Klappen106aStellen_XIX_Innenraumheizenelektrisch_XIX_ACT_106a_XIX_ClimateControl_VR_XIX_Innenraumheizenelektrisch_XIX_Zone_VR_XIX_ACT106a_Uebertemperatur
    delegate ClimateControl_VR_XIX_Innenraumheizenelektrisch_XIX_Zone_VR.RP_IF_ACT106a_Verfahrrichtung_XIX_ClimateControl_VR_XIX_Innenraumheizenelektrisch_XIX_Zone_VR <-> outer port RP_IF_ACT106a_Verfahrrichtung_XIX_Zone_VR  # _XIX_Klappen106aStellen_XIX_Innenraumheizenelektrisch_XIX_ACT_106a_XIX_ClimateControl_VR_XIX_Innenraumheizenelektrisch_XIX_Zone_VR_XIX_ACT106a_Verfahrrichtung
    delegate ClimateControl_VR_XIX_Innenraumheizenelektrisch_XIX_Zone_VR.RP_IF_ACT106a_Adresse_Aktuator_XIX_ClimateControl_VR_XIX_Innenraumheizenelektrisch_XIX_Zone_VR <-> outer port RP_IF_ACT106a_Adresse_Aktuator_XIX_Zone_VR  # _XIX_Klappen106aStellen_XIX_Innenraumheizenelektrisch_XIX_ACT_106a_XIX_ClimateControl_VR_XIX_Innenraumheizenelektrisch_XIX_Zone_VR_XIX_ACT106a_Adresse_Aktuator
    delegate ClimateControl_VR_XIX_Innenraumheizenelektrisch_XIX_Zone_VR.RP_IF_ACT106a_Stopmodus_XIX_ClimateControl_VR_XIX_Innenraumheizenelektrisch_XIX_Zone_VR <-> outer port RP_IF_ACT106a_Stopmodus_XIX_Zone_VR  # _XIX_Klappen106aStellen_XIX_Innenraumheizenelektrisch_XIX_ACT_106a_XIX_ClimateControl_VR_XIX_Innenraumheizenelektrisch_XIX_Zone_VR_XIX_ACT106a_Stopmodus
    delegate ClimateControl_VR_XIX_Innenraumheizenelektrisch_XIX_Zone_VR.RP_IF_ACT106a_Variante_XIX_ClimateControl_VR_XIX_Innenraumheizenelektrisch_XIX_Zone_VR <-> outer port RP_IF_ACT106a_Variante_XIX_Zone_VR  # _XIX_Klappen106aStellen_XIX_Innenraumheizenelektrisch_XIX_ACT_106a_XIX_ClimateControl_VR_XIX_Innenraumheizenelektrisch_XIX_Zone_VR_XIX_ACT106a_Variante
    delegate ClimateControl_VR_XIX_Innenraumheizenelektrisch_XIX_Zone_VR.RP_IF_ACT106a_Sonderfunktionen_XIX_ClimateControl_VR_XIX_Innenraumheizenelektrisch_XIX_Zone_VR <-> outer port RP_IF_ACT106a_Sonderfunktionen_XIX_Zone_VR  # _XIX_Klappen106aStellen_XIX_Innenraumheizenelektrisch_XIX_ACT_106a_XIX_ClimateControl_VR_XIX_Innenraumheizenelektrisch_XIX_Zone_VR_XIX_ACT106a_Sonderfunktionen
    delegate ClimateControl_VR_XIX_Innenraumheizenelektrisch_XIX_Zone_VR.RP_IF_ACT106a_Reset_XIX_ClimateControl_VR_XIX_Innenraumheizenelektrisch_XIX_Zone_VR <-> outer port RP_IF_ACT106a_Reset_XIX_Zone_VR  # _XIX_Klappen106aStellen_XIX_Innenraumheizenelektrisch_XIX_ACT_106a_XIX_ClimateControl_VR_XIX_Innenraumheizenelektrisch_XIX_Zone_VR_XIX_ACT106a_Reset
    delegate ClimateControl_VR_XIX_Innenraumheizenelektrisch_XIX_Zone_VR.RP_IF_ACT106a_Blockierung_aufgetreten_XIX_ClimateControl_VR_XIX_Innenraumheizenelektrisch_XIX_Zone_VR <-> outer port RP_IF_ACT106a_Blockierung_aufgetreten_XIX_Zone_VR  # _XIX_Klappen106aStellen_XIX_Innenraumheizenelektrisch_XIX_ACT_106a_XIX_ClimateControl_VR_XIX_Innenraumheizenelektrisch_XIX_Zone_VR_XIX_ACT106a_Blockierung_aufgetreten
    delegate ClimateControl_VR_XIX_Innenraumheizenelektrisch_XIX_Zone_VR.RP_IF_ACT106a_Notlauffreigabe_XIX_ClimateControl_VR_XIX_Innenraumheizenelektrisch_XIX_Zone_VR <-> outer port RP_IF_ACT106a_Notlauffreigabe_XIX_Zone_VR  # _XIX_Klappen106aStellen_XIX_Innenraumheizenelektrisch_XIX_ACT_106a_XIX_ClimateControl_VR_XIX_Innenraumheizenelektrisch_XIX_Zone_VR_XIX_ACT106a_Notlauffreigabe
    delegate ClimateControl_VR_XIX_Innenraumheizenelektrisch_XIX_Zone_VR.RP_IF_ACT106a_Drehrichtung_XIX_ClimateControl_VR_XIX_Innenraumheizenelektrisch_XIX_Zone_VR <-> outer port RP_IF_ACT106a_Drehrichtung_XIX_Zone_VR  # _XIX_Klappen106aStellen_XIX_Innenraumheizenelektrisch_XIX_ACT_106a_XIX_ClimateControl_VR_XIX_Innenraumheizenelektrisch_XIX_Zone_VR_XIX_ACT106a_Drehrichtung
    delegate ClimateControl_VR_XIX_Innenraumheizenelektrisch_XIX_Zone_VR.RP_IF_ACT106a_Notlauf_aufgetreten_XIX_ClimateControl_VR_XIX_Innenraumheizenelektrisch_XIX_Zone_VR <-> outer port RP_IF_ACT106a_Notlauf_aufgetreten_XIX_Zone_VR  # _XIX_Klappen106aStellen_XIX_Innenraumheizenelektrisch_XIX_ACT_106a_XIX_ClimateControl_VR_XIX_Innenraumheizenelektrisch_XIX_Zone_VR_XIX_ACT106a_Notlauf_aufgetreten
    delegate ClimateControl_VR_XIX_Innenraumheizenelektrisch_XIX_Zone_VR.RP_IF_ACT106a_Selbsthaltemoment_XIX_ClimateControl_VR_XIX_Innenraumheizenelektrisch_XIX_Zone_VR <-> outer port RP_IF_ACT106a_Selbsthaltemoment_XIX_Zone_VR  # _XIX_Klappen106aStellen_XIX_Innenraumheizenelektrisch_XIX_ACT_106a_XIX_ClimateControl_VR_XIX_Innenraumheizenelektrisch_XIX_Zone_VR_XIX_ACT106a_Selbsthaltemoment
    delegate ClimateControl_VR_XIX_Innenraumheizenelektrisch_XIX_Zone_VR.RP_IF_ACT106a_Notlaufposition_XIX_ClimateControl_VR_XIX_Innenraumheizenelektrisch_XIX_Zone_VR <-> outer port RP_IF_ACT106a_Notlaufposition_XIX_Zone_VR  # _XIX_Klappen106aStellen_XIX_Innenraumheizenelektrisch_XIX_ACT_106a_XIX_ClimateControl_VR_XIX_Innenraumheizenelektrisch_XIX_Zone_VR_XIX_ACT106a_Notlaufposition
    delegate ClimateControl_VR_XIX_Innenraumheizenelektrisch_XIX_Zone_VR.RP_IF_ACT106a_el_Defekt_XIX_ClimateControl_VR_XIX_Innenraumheizenelektrisch_XIX_Zone_VR <-> outer port RP_IF_ACT106a_el_Defekt_XIX_Zone_VR  # _XIX_Klappen106aStellen_XIX_Innenraumheizenelektrisch_XIX_ACT_106a_XIX_ClimateControl_VR_XIX_Innenraumheizenelektrisch_XIX_Zone_VR_XIX_ACT106a_el_Defekt
    delegate ClimateControl_VR_XIX_Innenraumheizenelektrisch_XIX_Zone_VR.RP_IF_ACT106a_Spulenbestromung_XIX_ClimateControl_VR_XIX_Innenraumheizenelektrisch_XIX_Zone_VR <-> outer port RP_IF_ACT106a_Spulenbestromung_XIX_Zone_VR  # _XIX_Klappen106aStellen_XIX_Innenraumheizenelektrisch_XIX_ACT_106a_XIX_ClimateControl_VR_XIX_Innenraumheizenelektrisch_XIX_Zone_VR_XIX_ACT106a_Spulenbestromung
    delegate ClimateControl_VR_XIX_Innenraumheizenelektrisch_XIX_Zone_VR.RP_IF_ACT109a_Verfahrrichtung_XIX_ClimateControl_VR_XIX_Innenraumheizenelektrisch_XIX_Zone_VR <-> outer port RP_IF_ACT109a_Verfahrrichtung_XIX_Zone_VR  # _XIX_Klappen109aStellen_XIX_Innenraumheizenelektrisch_XIX_ACT_109a_XIX_ClimateControl_VR_XIX_Innenraumheizenelektrisch_XIX_Zone_VR_XIX_ACT109a_Verfahrrichtung
    delegate ClimateControl_VR_XIX_Innenraumheizenelektrisch_XIX_Zone_VR.RP_IF_ACT109a_Positionsvorgabe_Status_XIX_ClimateControl_VR_XIX_Innenraumheizenelektrisch_XIX_Zone_VR <-> outer port RP_IF_ACT109a_Positionsvorgabe_Status_XIX_Zone_VR  # _XIX_Klappen109aStellen_XIX_Innenraumheizenelektrisch_XIX_ACT_109a_XIX_ClimateControl_VR_XIX_Innenraumheizenelektrisch_XIX_Zone_VR_XIX_ACT109a_Positionsvorgabe_Status
    delegate ClimateControl_VR_XIX_Innenraumheizenelektrisch_XIX_Zone_VR.RP_IF_ACT109a_Notlaufposition_XIX_ClimateControl_VR_XIX_Innenraumheizenelektrisch_XIX_Zone_VR <-> outer port RP_IF_ACT109a_Notlaufposition_XIX_Zone_VR  # _XIX_Klappen109aStellen_XIX_Innenraumheizenelektrisch_XIX_ACT_109a_XIX_ClimateControl_VR_XIX_Innenraumheizenelektrisch_XIX_Zone_VR_XIX_ACT109a_Notlaufposition
    delegate ClimateControl_VR_XIX_Innenraumheizenelektrisch_XIX_Zone_VR.RP_IF_ACT109a_Ist_Position_Aktuator_XIX_ClimateControl_VR_XIX_Innenraumheizenelektrisch_XIX_Zone_VR <-> outer port RP_IF_ACT109a_Ist_Position_Aktuator_XIX_Zone_VR  # _XIX_Klappen109aStellen_XIX_Innenraumheizenelektrisch_XIX_ACT_109a_XIX_ClimateControl_VR_XIX_Innenraumheizenelektrisch_XIX_Zone_VR_XIX_ACT109a_Ist_Position_Aktuator
    delegate ClimateControl_VR_XIX_Innenraumheizenelektrisch_XIX_Zone_VR.RP_IF_ACT109a_Uebertemperatur_XIX_ClimateControl_VR_XIX_Innenraumheizenelektrisch_XIX_Zone_VR <-> outer port RP_IF_ACT109a_Uebertemperatur_XIX_Zone_VR  # _XIX_Klappen109aStellen_XIX_Innenraumheizenelektrisch_XIX_ACT_109a_XIX_ClimateControl_VR_XIX_Innenraumheizenelektrisch_XIX_Zone_VR_XIX_ACT109a_Uebertemperatur
    delegate ClimateControl_VR_XIX_Innenraumheizenelektrisch_XIX_Zone_VR.RP_IF_ACT109a_Geschwindigkeitsstatus_XIX_ClimateControl_VR_XIX_Innenraumheizenelektrisch_XIX_Zone_VR <-> outer port RP_IF_ACT109a_Geschwindigkeitsstatus_XIX_Zone_VR  # _XIX_Klappen109aStellen_XIX_Innenraumheizenelektrisch_XIX_ACT_109a_XIX_ClimateControl_VR_XIX_Innenraumheizenelektrisch_XIX_Zone_VR_XIX_ACT109a_Geschwindigkeitsstatus
    delegate ClimateControl_VR_XIX_Innenraumheizenelektrisch_XIX_Zone_VR.RP_IF_ACT109a_Reset_XIX_ClimateControl_VR_XIX_Innenraumheizenelektrisch_XIX_Zone_VR <-> outer port RP_IF_ACT109a_Reset_XIX_Zone_VR  # _XIX_Klappen109aStellen_XIX_Innenraumheizenelektrisch_XIX_ACT_109a_XIX_ClimateControl_VR_XIX_Innenraumheizenelektrisch_XIX_Zone_VR_XIX_ACT109a_Reset
    delegate ClimateControl_VR_XIX_Innenraumheizenelektrisch_XIX_Zone_VR.RP_IF_ACT109a_Adresse_Aktuator_XIX_ClimateControl_VR_XIX_Innenraumheizenelektrisch_XIX_Zone_VR <-> outer port RP_IF_ACT109a_Adresse_Aktuator_XIX_Zone_VR  # _XIX_Klappen109aStellen_XIX_Innenraumheizenelektrisch_XIX_ACT_109a_XIX_ClimateControl_VR_XIX_Innenraumheizenelektrisch_XIX_Zone_VR_XIX_ACT109a_Adresse_Aktuator
    delegate ClimateControl_VR_XIX_Innenraumheizenelektrisch_XIX_Zone_VR.RP_IF_ACT109a_Stopmodus_XIX_ClimateControl_VR_XIX_Innenraumheizenelektrisch_XIX_Zone_VR <-> outer port RP_IF_ACT109a_Stopmodus_XIX_Zone_VR  # _XIX_Klappen109aStellen_XIX_Innenraumheizenelektrisch_XIX_ACT_109a_XIX_ClimateControl_VR_XIX_Innenraumheizenelektrisch_XIX_Zone_VR_XIX_ACT109a_Stopmodus
    delegate ClimateControl_VR_XIX_Innenraumheizenelektrisch_XIX_Zone_VR.RP_IF_ACT109a_Spulenbestromung_XIX_ClimateControl_VR_XIX_Innenraumheizenelektrisch_XIX_Zone_VR <-> outer port RP_IF_ACT109a_Spulenbestromung_XIX_Zone_VR  # _XIX_Klappen109aStellen_XIX_Innenraumheizenelektrisch_XIX_ACT_109a_XIX_ClimateControl_VR_XIX_Innenraumheizenelektrisch_XIX_Zone_VR_XIX_ACT109a_Spulenbestromung
    delegate ClimateControl_VR_XIX_Innenraumheizenelektrisch_XIX_Zone_VR.RP_IF_ACT109a_Versorgungsspannung_XIX_ClimateControl_VR_XIX_Innenraumheizenelektrisch_XIX_Zone_VR <-> outer port RP_IF_ACT109a_Versorgungsspannung_XIX_Zone_VR  # _XIX_Klappen109aStellen_XIX_Innenraumheizenelektrisch_XIX_ACT_109a_XIX_ClimateControl_VR_XIX_Innenraumheizenelektrisch_XIX_Zone_VR_XIX_ACT109a_Versorgungsspannung
    delegate ClimateControl_VR_XIX_Innenraumheizenelektrisch_XIX_Zone_VR.RP_IF_ACT109a_Variante_XIX_ClimateControl_VR_XIX_Innenraumheizenelektrisch_XIX_Zone_VR <-> outer port RP_IF_ACT109a_Variante_XIX_Zone_VR  # _XIX_Klappen109aStellen_XIX_Innenraumheizenelektrisch_XIX_ACT_109a_XIX_ClimateControl_VR_XIX_Innenraumheizenelektrisch_XIX_Zone_VR_XIX_ACT109a_Variante
    delegate ClimateControl_VR_XIX_Innenraumheizenelektrisch_XIX_Zone_VR.RP_IF_ACT109a_Blockierung_aufgetreten_XIX_ClimateControl_VR_XIX_Innenraumheizenelektrisch_XIX_Zone_VR <-> outer port RP_IF_ACT109a_Blockierung_aufgetreten_XIX_Zone_VR  # _XIX_Klappen109aStellen_XIX_Innenraumheizenelektrisch_XIX_ACT_109a_XIX_ClimateControl_VR_XIX_Innenraumheizenelektrisch_XIX_Zone_VR_XIX_ACT109a_Blockierung_aufgetreten
    delegate ClimateControl_VR_XIX_Innenraumheizenelektrisch_XIX_Zone_VR.RP_IF_ACT109a_Notlauffreigabe_XIX_ClimateControl_VR_XIX_Innenraumheizenelektrisch_XIX_Zone_VR <-> outer port RP_IF_ACT109a_Notlauffreigabe_XIX_Zone_VR  # _XIX_Klappen109aStellen_XIX_Innenraumheizenelektrisch_XIX_ACT_109a_XIX_ClimateControl_VR_XIX_Innenraumheizenelektrisch_XIX_Zone_VR_XIX_ACT109a_Notlauffreigabe
    delegate ClimateControl_VR_XIX_Innenraumheizenelektrisch_XIX_Zone_VR.RP_IF_ACT109a_Sonderfunktionen_XIX_ClimateControl_VR_XIX_Innenraumheizenelektrisch_XIX_Zone_VR <-> outer port RP_IF_ACT109a_Sonderfunktionen_XIX_Zone_VR  # _XIX_Klappen109aStellen_XIX_Innenraumheizenelektrisch_XIX_ACT_109a_XIX_ClimateControl_VR_XIX_Innenraumheizenelektrisch_XIX_Zone_VR_XIX_ACT109a_Sonderfunktionen
    delegate ClimateControl_VR_XIX_Innenraumheizenelektrisch_XIX_Zone_VR.RP_IF_ACT109a_Drehrichtung_XIX_ClimateControl_VR_XIX_Innenraumheizenelektrisch_XIX_Zone_VR <-> outer port RP_IF_ACT109a_Drehrichtung_XIX_Zone_VR  # _XIX_Klappen109aStellen_XIX_Innenraumheizenelektrisch_XIX_ACT_109a_XIX_ClimateControl_VR_XIX_Innenraumheizenelektrisch_XIX_Zone_VR_XIX_ACT109a_Drehrichtung
    delegate ClimateControl_VR_XIX_Innenraumheizenelektrisch_XIX_Zone_VR.RP_IF_ACT109a_Notlauf_aufgetreten_XIX_ClimateControl_VR_XIX_Innenraumheizenelektrisch_XIX_Zone_VR <-> outer port RP_IF_ACT109a_Notlauf_aufgetreten_XIX_Zone_VR  # _XIX_Klappen109aStellen_XIX_Innenraumheizenelektrisch_XIX_ACT_109a_XIX_ClimateControl_VR_XIX_Innenraumheizenelektrisch_XIX_Zone_VR_XIX_ACT109a_Notlauf_aufgetreten
    delegate ClimateControl_VR_XIX_Innenraumheizenelektrisch_XIX_Zone_VR.RP_IF_ACT109a_el_Defekt_XIX_ClimateControl_VR_XIX_Innenraumheizenelektrisch_XIX_Zone_VR <-> outer port RP_IF_ACT109a_el_Defekt_XIX_Zone_VR  # _XIX_Klappen109aStellen_XIX_Innenraumheizenelektrisch_XIX_ACT_109a_XIX_ClimateControl_VR_XIX_Innenraumheizenelektrisch_XIX_Zone_VR_XIX_ACT109a_el_Defekt
    delegate ClimateControl_VR_XIX_Innenraumheizenelektrisch_XIX_Zone_VR.RP_IF_ACT109a_Selbsthaltemoment_XIX_ClimateControl_VR_XIX_Innenraumheizenelektrisch_XIX_Zone_VR <-> outer port RP_IF_ACT109a_Selbsthaltemoment_XIX_Zone_VR  # _XIX_Klappen109aStellen_XIX_Innenraumheizenelektrisch_XIX_ACT_109a_XIX_ClimateControl_VR_XIX_Innenraumheizenelektrisch_XIX_Zone_VR_XIX_ACT109a_Selbsthaltemoment
    delegate ClimateControl_VR_XIX_Innenraumheizenelektrisch_XIX_Zone_VR.RP_IF_KPH_Auto_re_XIX_ClimateControl_VR_XIX_Innenraumheizenelektrisch_XIX_Zone_VR <-> outer port RP_IF_KPH_Auto_re_XIX_Zone_VR  # _XIX_KlimasteuerungHinten_XIX_Innenraumheizenelektrisch_XIX_KPH_XIX_ClimateControl_VR_XIX_Innenraumheizenelektrisch_XIX_Zone_VR_XIX_KPH_Auto_re
    delegate ClimateControl_VR_XIX_Innenraumheizenelektrisch_XIX_Zone_VR.RP_IF_KPH_Flaechenheizung_XIX_ClimateControl_VR_XIX_Innenraumheizenelektrisch_XIX_Zone_VR <-> outer port RP_IF_KPH_Flaechenheizung_XIX_Zone_VR  # _XIX_KlimasteuerungHinten_XIX_Innenraumheizenelektrisch_XIX_KPH_XIX_ClimateControl_VR_XIX_Innenraumheizenelektrisch_XIX_Zone_VR_XIX_KPH_Flaechenheizung
    delegate ClimateControl_VR_XIX_Innenraumheizenelektrisch_XIX_Zone_VR.RP_IF_KPH_ResponseError_XIX_ClimateControl_VR_XIX_Innenraumheizenelektrisch_XIX_Zone_VR <-> outer port RP_IF_KPH_ResponseError_XIX_Zone_VR  # _XIX_KlimasteuerungHinten_XIX_Innenraumheizenelektrisch_XIX_KPH_XIX_ClimateControl_VR_XIX_Innenraumheizenelektrisch_XIX_Zone_VR_XIX_KPH_ResponseError
    delegate ClimateControl_VR_XIX_Innenraumheizenelektrisch_XIX_Zone_VR.RP_IF_KPH_Sync_XIX_ClimateControl_VR_XIX_Innenraumheizenelektrisch_XIX_Zone_VR <-> outer port RP_IF_KPH_Sync_XIX_Zone_VR  # _XIX_KlimasteuerungHinten_XIX_Innenraumheizenelektrisch_XIX_KPH_XIX_ClimateControl_VR_XIX_Innenraumheizenelektrisch_XIX_Zone_VR_XIX_KPH_Sync
    delegate ClimateControl_VR_XIX_Innenraumheizenelektrisch_XIX_Zone_VR.RP_IF_KPH_ECO_links_XIX_ClimateControl_VR_XIX_Innenraumheizenelektrisch_XIX_Zone_VR <-> outer port RP_IF_KPH_ECO_links_XIX_Zone_VR  # _XIX_KlimasteuerungHinten_XIX_Innenraumheizenelektrisch_XIX_KPH_XIX_ClimateControl_VR_XIX_Innenraumheizenelektrisch_XIX_Zone_VR_XIX_KPH_ECO_links
    delegate ClimateControl_VR_XIX_Innenraumheizenelektrisch_XIX_Zone_VR.RP_IF_KPH_Sitzlueftung_re_XIX_ClimateControl_VR_XIX_Innenraumheizenelektrisch_XIX_Zone_VR <-> outer port RP_IF_KPH_Sitzlueftung_re_XIX_Zone_VR  # _XIX_KlimasteuerungHinten_XIX_Innenraumheizenelektrisch_XIX_KPH_XIX_ClimateControl_VR_XIX_Innenraumheizenelektrisch_XIX_Zone_VR_XIX_KPH_Sitzlueftung_re
    delegate ClimateControl_VR_XIX_Innenraumheizenelektrisch_XIX_Zone_VR.RP_IF_KPH_Neigungssensor_XIX_ClimateControl_VR_XIX_Innenraumheizenelektrisch_XIX_Zone_VR <-> outer port RP_IF_KPH_Neigungssensor_XIX_Zone_VR  # _XIX_KlimasteuerungHinten_XIX_Innenraumheizenelektrisch_XIX_KPH_XIX_ClimateControl_VR_XIX_Innenraumheizenelektrisch_XIX_Zone_VR_XIX_KPH_Neigungssensor
    delegate ClimateControl_VR_XIX_Innenraumheizenelektrisch_XIX_Zone_VR.RP_IF_KPH_Tasten_Fehler_XIX_ClimateControl_VR_XIX_Innenraumheizenelektrisch_XIX_Zone_VR <-> outer port RP_IF_KPH_Tasten_Fehler_XIX_Zone_VR  # _XIX_KlimasteuerungHinten_XIX_Innenraumheizenelektrisch_XIX_KPH_XIX_ClimateControl_VR_XIX_Innenraumheizenelektrisch_XIX_Zone_VR_XIX_KPH_Tasten_Fehler
    delegate ClimateControl_VR_XIX_Innenraumheizenelektrisch_XIX_Zone_VR.RP_IF_KPH_Luftverteilung_Oben_re_XIX_ClimateControl_VR_XIX_Innenraumheizenelektrisch_XIX_Zone_VR <-> outer port RP_IF_KPH_Luftverteilung_Oben_re_XIX_Zone_VR  # _XIX_KlimasteuerungHinten_XIX_Innenraumheizenelektrisch_XIX_KPH_XIX_ClimateControl_VR_XIX_Innenraumheizenelektrisch_XIX_Zone_VR_XIX_KPH_Luftverteilung_Oben_re
    delegate ClimateControl_VR_XIX_Innenraumheizenelektrisch_XIX_Zone_VR.RP_IF_KPH_Sitzlueftung_li_XIX_ClimateControl_VR_XIX_Innenraumheizenelektrisch_XIX_Zone_VR <-> outer port RP_IF_KPH_Sitzlueftung_li_XIX_Zone_VR  # _XIX_KlimasteuerungHinten_XIX_Innenraumheizenelektrisch_XIX_KPH_XIX_ClimateControl_VR_XIX_Innenraumheizenelektrisch_XIX_Zone_VR_XIX_KPH_Sitzlueftung_li
    delegate ClimateControl_VR_XIX_Innenraumheizenelektrisch_XIX_Zone_VR.RP_IF_KPH_Luftverteilung_Auto_li_XIX_ClimateControl_VR_XIX_Innenraumheizenelektrisch_XIX_Zone_VR <-> outer port RP_IF_KPH_Luftverteilung_Auto_li_XIX_Zone_VR  # _XIX_KlimasteuerungHinten_XIX_Innenraumheizenelektrisch_XIX_KPH_XIX_ClimateControl_VR_XIX_Innenraumheizenelektrisch_XIX_Zone_VR_XIX_KPH_Luftverteilung_Auto_li
    delegate ClimateControl_VR_XIX_Innenraumheizenelektrisch_XIX_Zone_VR.RP_IF_KPH_Geblaese_Auto_re_XIX_ClimateControl_VR_XIX_Innenraumheizenelektrisch_XIX_Zone_VR <-> outer port RP_IF_KPH_Geblaese_Auto_re_XIX_Zone_VR  # _XIX_KlimasteuerungHinten_XIX_Innenraumheizenelektrisch_XIX_KPH_XIX_ClimateControl_VR_XIX_Innenraumheizenelektrisch_XIX_Zone_VR_XIX_KPH_Geblaese_Auto_re
    delegate ClimateControl_VR_XIX_Innenraumheizenelektrisch_XIX_Zone_VR.RP_IF_KPH_Geblaese_Stufe_re_XIX_ClimateControl_VR_XIX_Innenraumheizenelektrisch_XIX_Zone_VR <-> outer port RP_IF_KPH_Geblaese_Stufe_re_XIX_Zone_VR  # _XIX_KlimasteuerungHinten_XIX_Innenraumheizenelektrisch_XIX_KPH_XIX_ClimateControl_VR_XIX_Innenraumheizenelektrisch_XIX_Zone_VR_XIX_KPH_Geblaese_Stufe_re
    delegate ClimateControl_VR_XIX_Innenraumheizenelektrisch_XIX_Zone_VR.RP_IF_KPH_Geblaese_Auto_li_XIX_ClimateControl_VR_XIX_Innenraumheizenelektrisch_XIX_Zone_VR <-> outer port RP_IF_KPH_Geblaese_Auto_li_XIX_Zone_VR  # _XIX_KlimasteuerungHinten_XIX_Innenraumheizenelektrisch_XIX_KPH_XIX_ClimateControl_VR_XIX_Innenraumheizenelektrisch_XIX_Zone_VR_XIX_KPH_Geblaese_Auto_li
    delegate ClimateControl_VR_XIX_Innenraumheizenelektrisch_XIX_Zone_VR.RP_IF_KPH_Geblaese_Stufe_li_XIX_ClimateControl_VR_XIX_Innenraumheizenelektrisch_XIX_Zone_VR <-> outer port RP_IF_KPH_Geblaese_Stufe_li_XIX_Zone_VR  # _XIX_KlimasteuerungHinten_XIX_Innenraumheizenelektrisch_XIX_KPH_XIX_ClimateControl_VR_XIX_Innenraumheizenelektrisch_XIX_Zone_VR_XIX_KPH_Geblaese_Stufe_li
    delegate ClimateControl_VR_XIX_Innenraumheizenelektrisch_XIX_Zone_VR.RP_IF_KPH_ECO_XIX_ClimateControl_VR_XIX_Innenraumheizenelektrisch_XIX_Zone_VR <-> outer port RP_IF_KPH_ECO_XIX_Zone_VR  # _XIX_KlimasteuerungHinten_XIX_Innenraumheizenelektrisch_XIX_KPH_XIX_ClimateControl_VR_XIX_Innenraumheizenelektrisch_XIX_Zone_VR_XIX_KPH_ECO
    delegate ClimateControl_VR_XIX_Innenraumheizenelektrisch_XIX_Zone_VR.RP_IF_KPH_Temp_re_XIX_ClimateControl_VR_XIX_Innenraumheizenelektrisch_XIX_Zone_VR <-> outer port RP_IF_KPH_Temp_re_XIX_Zone_VR  # _XIX_KlimasteuerungHinten_XIX_Innenraumheizenelektrisch_XIX_KPH_XIX_ClimateControl_VR_XIX_Innenraumheizenelektrisch_XIX_Zone_VR_XIX_KPH_Temp_re
    delegate ClimateControl_VR_XIX_Innenraumheizenelektrisch_XIX_Zone_VR.RP_IF_KPH_Sitzheizung_re_XIX_ClimateControl_VR_XIX_Innenraumheizenelektrisch_XIX_Zone_VR <-> outer port RP_IF_KPH_Sitzheizung_re_XIX_Zone_VR  # _XIX_KlimasteuerungHinten_XIX_Innenraumheizenelektrisch_XIX_KPH_XIX_ClimateControl_VR_XIX_Innenraumheizenelektrisch_XIX_Zone_VR_XIX_KPH_Sitzheizung_re
    delegate ClimateControl_VR_XIX_Innenraumheizenelektrisch_XIX_Zone_VR.RP_IF_KPH_Luftverteilung_Unten_li_XIX_ClimateControl_VR_XIX_Innenraumheizenelektrisch_XIX_Zone_VR <-> outer port RP_IF_KPH_Luftverteilung_Unten_li_XIX_Zone_VR  # _XIX_KlimasteuerungHinten_XIX_Innenraumheizenelektrisch_XIX_KPH_XIX_ClimateControl_VR_XIX_Innenraumheizenelektrisch_XIX_Zone_VR_XIX_KPH_Luftverteilung_Unten_li
    delegate ClimateControl_VR_XIX_Innenraumheizenelektrisch_XIX_Zone_VR.RP_IF_KPH_Luftverteilung_Mitte_li_XIX_ClimateControl_VR_XIX_Innenraumheizenelektrisch_XIX_Zone_VR <-> outer port RP_IF_KPH_Luftverteilung_Mitte_li_XIX_Zone_VR  # _XIX_KlimasteuerungHinten_XIX_Innenraumheizenelektrisch_XIX_KPH_XIX_ClimateControl_VR_XIX_Innenraumheizenelektrisch_XIX_Zone_VR_XIX_KPH_Luftverteilung_Mitte_li
    delegate ClimateControl_VR_XIX_Innenraumheizenelektrisch_XIX_Zone_VR.RP_IF_KPH_Beduftung_XIX_ClimateControl_VR_XIX_Innenraumheizenelektrisch_XIX_Zone_VR <-> outer port RP_IF_KPH_Beduftung_XIX_Zone_VR  # _XIX_KlimasteuerungHinten_XIX_Innenraumheizenelektrisch_XIX_KPH_XIX_ClimateControl_VR_XIX_Innenraumheizenelektrisch_XIX_Zone_VR_XIX_KPH_Beduftung
    delegate ClimateControl_VR_XIX_Innenraumheizenelektrisch_XIX_Zone_VR.RP_IF_KPH_Luftverteilung_Oben_li_XIX_ClimateControl_VR_XIX_Innenraumheizenelektrisch_XIX_Zone_VR <-> outer port RP_IF_KPH_Luftverteilung_Oben_li_XIX_Zone_VR  # _XIX_KlimasteuerungHinten_XIX_Innenraumheizenelektrisch_XIX_KPH_XIX_ClimateControl_VR_XIX_Innenraumheizenelektrisch_XIX_Zone_VR_XIX_KPH_Luftverteilung_Oben_li
    delegate ClimateControl_VR_XIX_Innenraumheizenelektrisch_XIX_Zone_VR.RP_IF_KPH_Sitzheizung_li_XIX_ClimateControl_VR_XIX_Innenraumheizenelektrisch_XIX_Zone_VR <-> outer port RP_IF_KPH_Sitzheizung_li_XIX_Zone_VR  # _XIX_KlimasteuerungHinten_XIX_Innenraumheizenelektrisch_XIX_KPH_XIX_ClimateControl_VR_XIX_Innenraumheizenelektrisch_XIX_Zone_VR_XIX_KPH_Sitzheizung_li
    delegate ClimateControl_VR_XIX_Innenraumheizenelektrisch_XIX_Zone_VR.RP_IF_KPH_Luftverteilung_Unten_re_XIX_ClimateControl_VR_XIX_Innenraumheizenelektrisch_XIX_Zone_VR <-> outer port RP_IF_KPH_Luftverteilung_Unten_re_XIX_Zone_VR  # _XIX_KlimasteuerungHinten_XIX_Innenraumheizenelektrisch_XIX_KPH_XIX_ClimateControl_VR_XIX_Innenraumheizenelektrisch_XIX_Zone_VR_XIX_KPH_Luftverteilung_Unten_re
    delegate ClimateControl_VR_XIX_Innenraumheizenelektrisch_XIX_Zone_VR.RP_IF_KPH_Status_Spannung_XIX_ClimateControl_VR_XIX_Innenraumheizenelektrisch_XIX_Zone_VR <-> outer port RP_IF_KPH_Status_Spannung_XIX_Zone_VR  # _XIX_KlimasteuerungHinten_XIX_Innenraumheizenelektrisch_XIX_KPH_XIX_ClimateControl_VR_XIX_Innenraumheizenelektrisch_XIX_Zone_VR_XIX_KPH_Status_Spannung
    delegate ClimateControl_VR_XIX_Innenraumheizenelektrisch_XIX_Zone_VR.RP_IF_KPH_Auto_li_XIX_ClimateControl_VR_XIX_Innenraumheizenelektrisch_XIX_Zone_VR <-> outer port RP_IF_KPH_Auto_li_XIX_Zone_VR  # _XIX_KlimasteuerungHinten_XIX_Innenraumheizenelektrisch_XIX_KPH_XIX_ClimateControl_VR_XIX_Innenraumheizenelektrisch_XIX_Zone_VR_XIX_KPH_Auto_li
    delegate ClimateControl_VR_XIX_Innenraumheizenelektrisch_XIX_Zone_VR.RP_IF_KPH_Off_XIX_ClimateControl_VR_XIX_Innenraumheizenelektrisch_XIX_Zone_VR <-> outer port RP_IF_KPH_Off_XIX_Zone_VR  # _XIX_KlimasteuerungHinten_XIX_Innenraumheizenelektrisch_XIX_KPH_XIX_ClimateControl_VR_XIX_Innenraumheizenelektrisch_XIX_Zone_VR_XIX_KPH_Off
    delegate ClimateControl_VR_XIX_Innenraumheizenelektrisch_XIX_Zone_VR.RP_IF_KPH_Temp_Platine_XIX_ClimateControl_VR_XIX_Innenraumheizenelektrisch_XIX_Zone_VR <-> outer port RP_IF_KPH_Temp_Platine_XIX_Zone_VR  # _XIX_KlimasteuerungHinten_XIX_Innenraumheizenelektrisch_XIX_KPH_XIX_ClimateControl_VR_XIX_Innenraumheizenelektrisch_XIX_Zone_VR_XIX_KPH_Temp_Platine
    delegate ClimateControl_VR_XIX_Innenraumheizenelektrisch_XIX_Zone_VR.RP_IF_KPH_ECO_rechts_XIX_ClimateControl_VR_XIX_Innenraumheizenelektrisch_XIX_Zone_VR <-> outer port RP_IF_KPH_ECO_rechts_XIX_Zone_VR  # _XIX_KlimasteuerungHinten_XIX_Innenraumheizenelektrisch_XIX_KPH_XIX_ClimateControl_VR_XIX_Innenraumheizenelektrisch_XIX_Zone_VR_XIX_KPH_ECO_rechts
    delegate ClimateControl_VR_XIX_Innenraumheizenelektrisch_XIX_Zone_VR.RP_IF_KPH_Lokalaktiv_XIX_ClimateControl_VR_XIX_Innenraumheizenelektrisch_XIX_Zone_VR <-> outer port RP_IF_KPH_Lokalaktiv_XIX_Zone_VR  # _XIX_KlimasteuerungHinten_XIX_Innenraumheizenelektrisch_XIX_KPH_XIX_ClimateControl_VR_XIX_Innenraumheizenelektrisch_XIX_Zone_VR_XIX_KPH_Lokalaktiv
    delegate ClimateControl_VR_XIX_Innenraumheizenelektrisch_XIX_Zone_VR.RP_IF_KPH_Panel_Error_XIX_ClimateControl_VR_XIX_Innenraumheizenelektrisch_XIX_Zone_VR <-> outer port RP_IF_KPH_Panel_Error_XIX_Zone_VR  # _XIX_KlimasteuerungHinten_XIX_Innenraumheizenelektrisch_XIX_KPH_XIX_ClimateControl_VR_XIX_Innenraumheizenelektrisch_XIX_Zone_VR_XIX_KPH_Panel_Error
    delegate ClimateControl_VR_XIX_Innenraumheizenelektrisch_XIX_Zone_VR.RP_IF_KPH_Temp_li_XIX_ClimateControl_VR_XIX_Innenraumheizenelektrisch_XIX_Zone_VR <-> outer port RP_IF_KPH_Temp_li_XIX_Zone_VR  # _XIX_KlimasteuerungHinten_XIX_Innenraumheizenelektrisch_XIX_KPH_XIX_ClimateControl_VR_XIX_Innenraumheizenelektrisch_XIX_Zone_VR_XIX_KPH_Temp_li
    delegate ClimateControl_VR_XIX_Innenraumheizenelektrisch_XIX_Zone_VR.RP_IF_KPH_Ionisator_XIX_ClimateControl_VR_XIX_Innenraumheizenelektrisch_XIX_Zone_VR <-> outer port RP_IF_KPH_Ionisator_XIX_Zone_VR  # _XIX_KlimasteuerungHinten_XIX_Innenraumheizenelektrisch_XIX_KPH_XIX_ClimateControl_VR_XIX_Innenraumheizenelektrisch_XIX_Zone_VR_XIX_KPH_Ionisator
    delegate ClimateControl_VR_XIX_Innenraumheizenelektrisch_XIX_Zone_VR.RP_IF_KPH_AC_XIX_ClimateControl_VR_XIX_Innenraumheizenelektrisch_XIX_Zone_VR <-> outer port RP_IF_KPH_AC_XIX_Zone_VR  # _XIX_KlimasteuerungHinten_XIX_Innenraumheizenelektrisch_XIX_KPH_XIX_ClimateControl_VR_XIX_Innenraumheizenelektrisch_XIX_Zone_VR_XIX_KPH_AC
    delegate ClimateControl_VR_XIX_Innenraumheizenelektrisch_XIX_Zone_VR.RP_IF_KPH_Klima_Menue_MMI_XIX_ClimateControl_VR_XIX_Innenraumheizenelektrisch_XIX_Zone_VR <-> outer port RP_IF_KPH_Klima_Menue_MMI_XIX_Zone_VR  # _XIX_KlimasteuerungHinten_XIX_Innenraumheizenelektrisch_XIX_KPH_XIX_ClimateControl_VR_XIX_Innenraumheizenelektrisch_XIX_Zone_VR_XIX_KPH_Klima_Menue_MMI
    delegate ClimateControl_VR_XIX_Innenraumheizenelektrisch_XIX_Zone_VR.RP_IF_KPH_Luftverteilung_Mitte_re_XIX_ClimateControl_VR_XIX_Innenraumheizenelektrisch_XIX_Zone_VR <-> outer port RP_IF_KPH_Luftverteilung_Mitte_re_XIX_Zone_VR  # _XIX_KlimasteuerungHinten_XIX_Innenraumheizenelektrisch_XIX_KPH_XIX_ClimateControl_VR_XIX_Innenraumheizenelektrisch_XIX_Zone_VR_XIX_KPH_Luftverteilung_Mitte_re
    delegate ClimateControl_VR_XIX_Innenraumheizenelektrisch_XIX_Zone_VR.RP_IF_KPH_Init_XIX_ClimateControl_VR_XIX_Innenraumheizenelektrisch_XIX_Zone_VR <-> outer port RP_IF_KPH_Init_XIX_Zone_VR  # _XIX_KlimasteuerungHinten_XIX_Innenraumheizenelektrisch_XIX_KPH_XIX_ClimateControl_VR_XIX_Innenraumheizenelektrisch_XIX_Zone_VR_XIX_KPH_Init
    delegate ClimateControl_VR_XIX_Innenraumheizenelektrisch_XIX_Zone_VR.RP_IF_KPH_AC_max_XIX_ClimateControl_VR_XIX_Innenraumheizenelektrisch_XIX_Zone_VR <-> outer port RP_IF_KPH_AC_max_XIX_Zone_VR  # _XIX_KlimasteuerungHinten_XIX_Innenraumheizenelektrisch_XIX_KPH_XIX_ClimateControl_VR_XIX_Innenraumheizenelektrisch_XIX_Zone_VR_XIX_KPH_AC_max
    delegate ClimateControl_VR_XIX_Innenraumheizenelektrisch_XIX_Zone_VR.RP_IF_KPH_Luftverteilung_Auto_re_XIX_ClimateControl_VR_XIX_Innenraumheizenelektrisch_XIX_Zone_VR <-> outer port RP_IF_KPH_Luftverteilung_Auto_re_XIX_Zone_VR  # _XIX_KlimasteuerungHinten_XIX_Innenraumheizenelektrisch_XIX_KPH_XIX_ClimateControl_VR_XIX_Innenraumheizenelektrisch_XIX_Zone_VR_XIX_KPH_Luftverteilung_Auto_re
    delegate ClimateControl_VR_XIX_Innenraumheizenelektrisch_XIX_Zone_VR.RP_IF_KPH_Umluft_XIX_ClimateControl_VR_XIX_Innenraumheizenelektrisch_XIX_Zone_VR <-> outer port RP_IF_KPH_Umluft_XIX_Zone_VR  # _XIX_KlimasteuerungHinten_XIX_Innenraumheizenelektrisch_XIX_KPH_XIX_ClimateControl_VR_XIX_Innenraumheizenelektrisch_XIX_Zone_VR_XIX_KPH_Umluft
    delegate ClimateControl_VR_XIX_Innenraumheizenelektrisch_XIX_Zone_VR.RP_IF_KPH_Lautsprecher_XIX_ClimateControl_VR_XIX_Innenraumheizenelektrisch_XIX_Zone_VR <-> outer port RP_IF_KPH_Lautsprecher_XIX_Zone_VR  # _XIX_KlimasteuerungHinten_XIX_Innenraumheizenelektrisch_XIX_KPH_XIX_ClimateControl_VR_XIX_Innenraumheizenelektrisch_XIX_Zone_VR_XIX_KPH_Lautsprecher
    delegate ThermalManagement_VR_XIX_BereitstellungAuentemperatursignal_XIX_Zone_VR.SP_IF_TME_T_OutsideAirTemp_raw_XIX_ThermalManagement_VR_XIX_BereitstellungAuentemperatursignal_XIX_Zone_VR <-> outer port SP_IF_TME_T_OutsideAirTemp_raw_XIX_Zone_VR  # _XIX_ThermalManagement_VR_XIX_BereitstellungAuentemperatursignal_XIX_Zone_VR_XIX_OutsideTemperatureProvider_XIX_BereitstellungAuentemperatursignal_XIX_VCP_Body_XIX_TME_T_OutsideAirTemp_raw
  composition sw component type Grundumfang_XIX_Zone_VR
    provide port SP_IF_Zone_VR_SNI_10_XIX_Grundumfang_XIX_Zone_VR: provided-interface=IF_Zone_VR_SNI_10
  composition sw component type ThermalManagement_VR_XIX_BereitstellungAuentemperatursignal_XIX_Zone_VR
    provide port SP_IF_TME_T_OutsideAirTemp_raw_XIX_ThermalManagement_VR_XIX_BereitstellungAuentemperatursignal_XIX_Zone_VR: provided-interface=IF_TME_T_OutsideAirTemp_raw
